VERSION ""

NS_ :

BS_:

BU_:

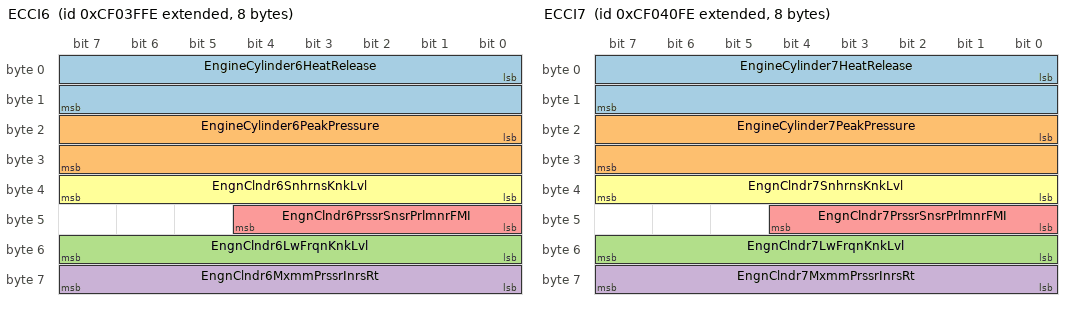
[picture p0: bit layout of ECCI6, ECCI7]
BO_ 2364555262 ECCI6: 8 Vector__XXX
 SG_ EngineCylinder6HeatRelease : 0|16@1+ (0.0001220703125,-1) [-1|6.84362793] "kJ/l" Vector__XXX
 SG_ EngineCylinder6PeakPressure : 16|16@1+ (0.0009765625,0) [0|62.74902344] "MPa" Vector__XXX
 SG_ EngnClndr6LwFrqnKnkLvl : 48|8@1+ (1,0) [0|250] "%" Vector__XXX
 SG_ EngnClndr6MxmmPrssrInrsRt : 56|8@1+ (16,0) [0|4000] "kPa/deg crank angle" Vector__XXX
 SG_ EngnClndr6PrssrSnsrPrlmnrFMI : 40|5@1+ (1,0) [0|31] "binary" Vector__XXX
 SG_ EngnClndr6SnhrnsKnkLvl : 32|8@1+ (1,0) [0|250] "%" Vector__XXX

BO_ 2364555518 ECCI7: 8 Vector__XXX
 SG_ EngineCylinder7HeatRelease : 0|16@1+ (0.0001220703125,-1) [-1|6.84362793] "kJ/l" Vector__XXX
 SG_ EngineCylinder7PeakPressure : 16|16@1+ (0.0009765625,0) [0|62.74902344] "MPa" Vector__XXX
 SG_ EngnClndr7LwFrqnKnkLvl : 48|8@1+ (1,0) [0|250] "%" Vector__XXX
 SG_ EngnClndr7MxmmPrssrInrsRt : 56|8@1+ (16,0) [0|4000] "kPa/deg crank angle" Vector__XXX
 SG_ EngnClndr7PrssrSnsrPrlmnrFMI : 40|5@1+ (1,0) [0|31] "binary" Vector__XXX
 SG_ EngnClndr7SnhrnsKnkLvl : 32|8@1+ (1,0) [0|250] "%" Vector__XXX

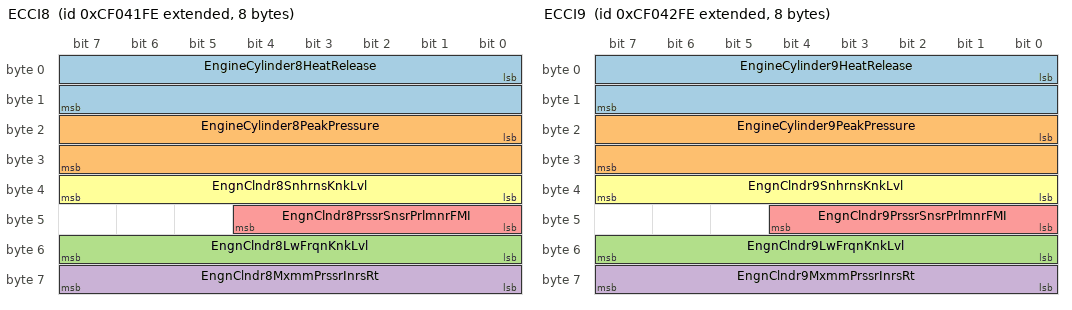
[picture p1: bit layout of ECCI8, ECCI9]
BO_ 2364555774 ECCI8: 8 Vector__XXX
 SG_ EngineCylinder8HeatRelease : 0|16@1+ (0.0001220703125,-1) [-1|6.84362793] "kJ/l" Vector__XXX
 SG_ EngineCylinder8PeakPressure : 16|16@1+ (0.0009765625,0) [0|62.74902344] "MPa" Vector__XXX
 SG_ EngnClndr8LwFrqnKnkLvl : 48|8@1+ (1,0) [0|250] "%" Vector__XXX
 SG_ EngnClndr8MxmmPrssrInrsRt : 56|8@1+ (16,0) [0|4000] "kPa/deg crank angle" Vector__XXX
 SG_ EngnClndr8PrssrSnsrPrlmnrFMI : 40|5@1+ (1,0) [0|31] "binary" Vector__XXX
 SG_ EngnClndr8SnhrnsKnkLvl : 32|8@1+ (1,0) [0|250] "%" Vector__XXX

BO_ 2364556030 ECCI9: 8 Vector__XXX
 SG_ EngineCylinder9HeatRelease : 0|16@1+ (0.0001220703125,-1) [-1|6.84362793] "kJ/l" Vector__XXX
 SG_ EngineCylinder9PeakPressure : 16|16@1+ (0.0009765625,0) [0|62.74902344] "MPa" Vector__XXX
 SG_ EngnClndr9LwFrqnKnkLvl : 48|8@1+ (1,0) [0|250] "%" Vector__XXX
 SG_ EngnClndr9MxmmPrssrInrsRt : 56|8@1+ (16,0) [0|4000] "kPa/deg crank angle" Vector__XXX
 SG_ EngnClndr9PrssrSnsrPrlmnrFMI : 40|5@1+ (1,0) [0|31] "binary" Vector__XXX
 SG_ EngnClndr9SnhrnsKnkLvl : 32|8@1+ (1,0) [0|250] "%" Vector__XXX

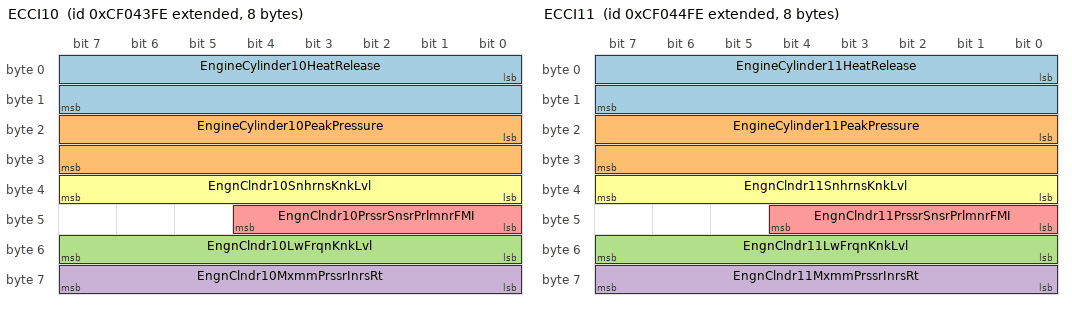
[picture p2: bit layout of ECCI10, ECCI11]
BO_ 2364556286 ECCI10: 8 Vector__XXX
 SG_ EngineCylinder10HeatRelease : 0|16@1+ (0.0001220703125,-1) [-1|6.84362793] "kJ/l" Vector__XXX
 SG_ EngineCylinder10PeakPressure : 16|16@1+ (0.0009765625,0) [0|62.74902344] "MPa" Vector__XXX
 SG_ EngnClndr10LwFrqnKnkLvl : 48|8@1+ (1,0) [0|250] "%" Vector__XXX
 SG_ EngnClndr10MxmmPrssrInrsRt : 56|8@1+ (16,0) [0|4000] "kPa/deg crank angle" Vector__XXX
 SG_ EngnClndr10PrssrSnsrPrlmnrFMI : 40|5@1+ (1,0) [0|31] "binary" Vector__XXX
 SG_ EngnClndr10SnhrnsKnkLvl : 32|8@1+ (1,0) [0|250] "%" Vector__XXX

BO_ 2364556542 ECCI11: 8 Vector__XXX
 SG_ EngineCylinder11HeatRelease : 0|16@1+ (0.0001220703125,-1) [-1|6.84362793] "kJ/l" Vector__XXX
 SG_ EngineCylinder11PeakPressure : 16|16@1+ (0.0009765625,0) [0|62.74902344] "MPa" Vector__XXX
 SG_ EngnClndr11LwFrqnKnkLvl : 48|8@1+ (1,0) [0|250] "%" Vector__XXX
 SG_ EngnClndr11MxmmPrssrInrsRt : 56|8@1+ (16,0) [0|4000] "kPa/deg crank angle" Vector__XXX
 SG_ EngnClndr11PrssrSnsrPrlmnrFMI : 40|5@1+ (1,0) [0|31] "binary" Vector__XXX
 SG_ EngnClndr11SnhrnsKnkLvl : 32|8@1+ (1,0) [0|250] "%" Vector__XXX

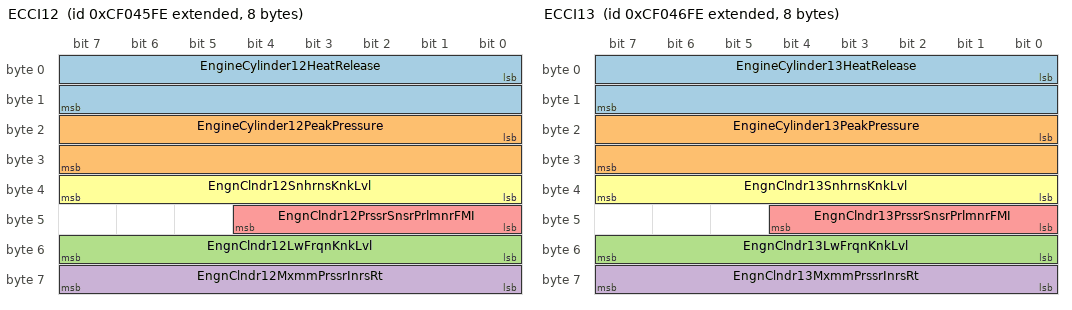
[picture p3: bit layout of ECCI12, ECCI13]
BO_ 2364556798 ECCI12: 8 Vector__XXX
 SG_ EngineCylinder12HeatRelease : 0|16@1+ (0.0001220703125,-1) [-1|6.84362793] "kJ/l" Vector__XXX
 SG_ EngineCylinder12PeakPressure : 16|16@1+ (0.0009765625,0) [0|62.74902344] "MPa" Vector__XXX
 SG_ EngnClndr12LwFrqnKnkLvl : 48|8@1+ (1,0) [0|250] "%" Vector__XXX
 SG_ EngnClndr12MxmmPrssrInrsRt : 56|8@1+ (16,0) [0|4000] "kPa/deg crank angle" Vector__XXX
 SG_ EngnClndr12PrssrSnsrPrlmnrFMI : 40|5@1+ (1,0) [0|31] "binary" Vector__XXX
 SG_ EngnClndr12SnhrnsKnkLvl : 32|8@1+ (1,0) [0|250] "%" Vector__XXX

BO_ 2364557054 ECCI13: 8 Vector__XXX
 SG_ EngineCylinder13HeatRelease : 0|16@1+ (0.0001220703125,-1) [-1|6.84362793] "kJ/l" Vector__XXX
 SG_ EngineCylinder13PeakPressure : 16|16@1+ (0.0009765625,0) [0|62.74902344] "MPa" Vector__XXX
 SG_ EngnClndr13LwFrqnKnkLvl : 48|8@1+ (1,0) [0|250] "%" Vector__XXX
 SG_ EngnClndr13MxmmPrssrInrsRt : 56|8@1+ (16,0) [0|4000] "kPa/deg crank angle" Vector__XXX
 SG_ EngnClndr13PrssrSnsrPrlmnrFMI : 40|5@1+ (1,0) [0|31] "binary" Vector__XXX
 SG_ EngnClndr13SnhrnsKnkLvl : 32|8@1+ (1,0) [0|250] "%" Vector__XXX

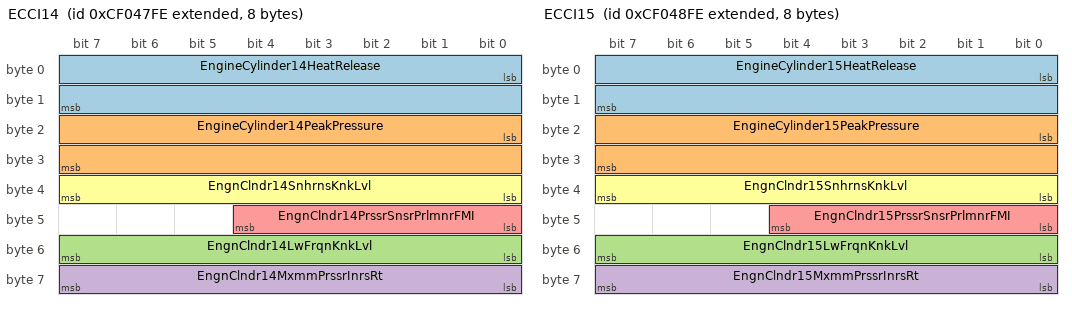
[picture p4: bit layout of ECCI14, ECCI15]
BO_ 2364557310 ECCI14: 8 Vector__XXX
 SG_ EngineCylinder14HeatRelease : 0|16@1+ (0.0001220703125,-1) [-1|6.84362793] "kJ/l" Vector__XXX
 SG_ EngineCylinder14PeakPressure : 16|16@1+ (0.0009765625,0) [0|62.74902344] "MPa" Vector__XXX
 SG_ EngnClndr14LwFrqnKnkLvl : 48|8@1+ (1,0) [0|250] "%" Vector__XXX
 SG_ EngnClndr14MxmmPrssrInrsRt : 56|8@1+ (16,0) [0|4000] "kPa/deg crank angle" Vector__XXX
 SG_ EngnClndr14PrssrSnsrPrlmnrFMI : 40|5@1+ (1,0) [0|31] "binary" Vector__XXX
 SG_ EngnClndr14SnhrnsKnkLvl : 32|8@1+ (1,0) [0|250] "%" Vector__XXX

BO_ 2364557566 ECCI15: 8 Vector__XXX
 SG_ EngineCylinder15HeatRelease : 0|16@1+ (0.0001220703125,-1) [-1|6.84362793] "kJ/l" Vector__XXX
 SG_ EngineCylinder15PeakPressure : 16|16@1+ (0.0009765625,0) [0|62.74902344] "MPa" Vector__XXX
 SG_ EngnClndr15LwFrqnKnkLvl : 48|8@1+ (1,0) [0|250] "%" Vector__XXX
 SG_ EngnClndr15MxmmPrssrInrsRt : 56|8@1+ (16,0) [0|4000] "kPa/deg crank angle" Vector__XXX
 SG_ EngnClndr15PrssrSnsrPrlmnrFMI : 40|5@1+ (1,0) [0|31] "binary" Vector__XXX
 SG_ EngnClndr15SnhrnsKnkLvl : 32|8@1+ (1,0) [0|250] "%" Vector__XXX

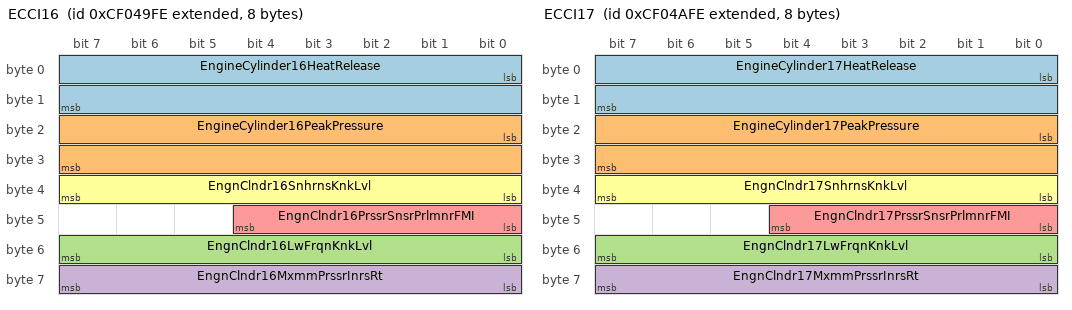
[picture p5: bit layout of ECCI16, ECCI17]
BO_ 2364557822 ECCI16: 8 Vector__XXX
 SG_ EngineCylinder16HeatRelease : 0|16@1+ (0.0001220703125,-1) [-1|6.84362793] "kJ/l" Vector__XXX
 SG_ EngineCylinder16PeakPressure : 16|16@1+ (0.0009765625,0) [0|62.74902344] "MPa" Vector__XXX
 SG_ EngnClndr16LwFrqnKnkLvl : 48|8@1+ (1,0) [0|250] "%" Vector__XXX
 SG_ EngnClndr16MxmmPrssrInrsRt : 56|8@1+ (16,0) [0|4000] "kPa/deg crank angle" Vector__XXX
 SG_ EngnClndr16PrssrSnsrPrlmnrFMI : 40|5@1+ (1,0) [0|31] "binary" Vector__XXX
 SG_ EngnClndr16SnhrnsKnkLvl : 32|8@1+ (1,0) [0|250] "%" Vector__XXX

BO_ 2364558078 ECCI17: 8 Vector__XXX
 SG_ EngineCylinder17HeatRelease : 0|16@1+ (0.0001220703125,-1) [-1|6.84362793] "kJ/l" Vector__XXX
 SG_ EngineCylinder17PeakPressure : 16|16@1+ (0.0009765625,0) [0|62.74902344] "MPa" Vector__XXX
 SG_ EngnClndr17LwFrqnKnkLvl : 48|8@1+ (1,0) [0|250] "%" Vector__XXX
 SG_ EngnClndr17MxmmPrssrInrsRt : 56|8@1+ (16,0) [0|4000] "kPa/deg crank angle" Vector__XXX
 SG_ EngnClndr17PrssrSnsrPrlmnrFMI : 40|5@1+ (1,0) [0|31] "binary" Vector__XXX
 SG_ EngnClndr17SnhrnsKnkLvl : 32|8@1+ (1,0) [0|250] "%" Vector__XXX

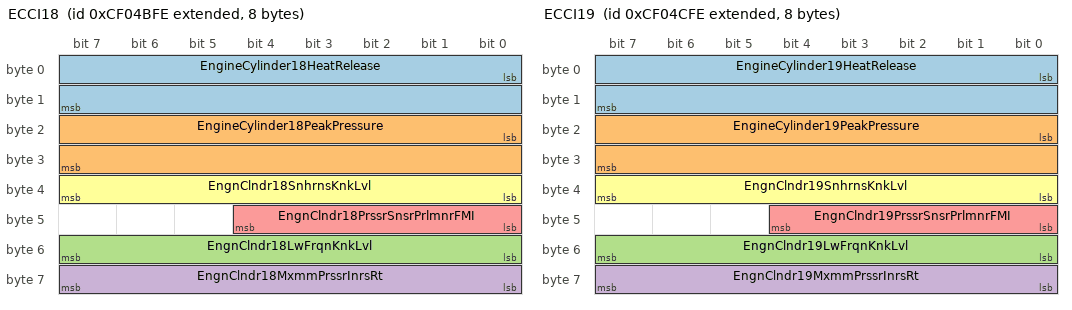
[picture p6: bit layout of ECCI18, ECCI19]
BO_ 2364558334 ECCI18: 8 Vector__XXX
 SG_ EngineCylinder18HeatRelease : 0|16@1+ (0.0001220703125,-1) [-1|6.84362793] "kJ/l" Vector__XXX
 SG_ EngineCylinder18PeakPressure : 16|16@1+ (0.0009765625,0) [0|62.74902344] "MPa" Vector__XXX
 SG_ EngnClndr18LwFrqnKnkLvl : 48|8@1+ (1,0) [0|250] "%" Vector__XXX
 SG_ EngnClndr18MxmmPrssrInrsRt : 56|8@1+ (16,0) [0|4000] "kPa/deg crank angle" Vector__XXX
 SG_ EngnClndr18PrssrSnsrPrlmnrFMI : 40|5@1+ (1,0) [0|31] "binary" Vector__XXX
 SG_ EngnClndr18SnhrnsKnkLvl : 32|8@1+ (1,0) [0|250] "%" Vector__XXX

BO_ 2364558590 ECCI19: 8 Vector__XXX
 SG_ EngineCylinder19HeatRelease : 0|16@1+ (0.0001220703125,-1) [-1|6.84362793] "kJ/l" Vector__XXX
 SG_ EngineCylinder19PeakPressure : 16|16@1+ (0.0009765625,0) [0|62.74902344] "MPa" Vector__XXX
 SG_ EngnClndr19LwFrqnKnkLvl : 48|8@1+ (1,0) [0|250] "%" Vector__XXX
 SG_ EngnClndr19MxmmPrssrInrsRt : 56|8@1+ (16,0) [0|4000] "kPa/deg crank angle" Vector__XXX
 SG_ EngnClndr19PrssrSnsrPrlmnrFMI : 40|5@1+ (1,0) [0|31] "binary" Vector__XXX
 SG_ EngnClndr19SnhrnsKnkLvl : 32|8@1+ (1,0) [0|250] "%" Vector__XXX

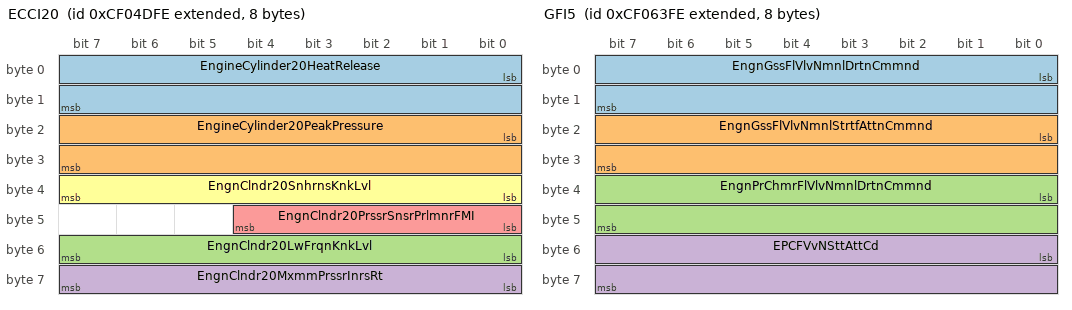
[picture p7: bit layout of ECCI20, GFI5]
BO_ 2364558846 ECCI20: 8 Vector__XXX
 SG_ EngineCylinder20HeatRelease : 0|16@1+ (0.0001220703125,-1) [-1|6.84362793] "kJ/l" Vector__XXX
 SG_ EngineCylinder20PeakPressure : 16|16@1+ (0.0009765625,0) [0|62.74902344] "MPa" Vector__XXX
 SG_ EngnClndr20LwFrqnKnkLvl : 48|8@1+ (1,0) [0|250] "%" Vector__XXX
 SG_ EngnClndr20MxmmPrssrInrsRt : 56|8@1+ (16,0) [0|4000] "kPa/deg crank angle" Vector__XXX
 SG_ EngnClndr20PrssrSnsrPrlmnrFMI : 40|5@1+ (1,0) [0|31] "binary" Vector__XXX
 SG_ EngnClndr20SnhrnsKnkLvl : 32|8@1+ (1,0) [0|250] "%" Vector__XXX

BO_ 2364564478 GFI5: 8 Vector__XXX
 SG_ EngnGssFlVlvNmnlDrtnCmmnd : 0|16@1+ (2,0) [0|128510] "micro s" Vector__XXX
 SG_ EngnGssFlVlvNmnlStrtfAttnCmmnd : 16|16@1+ (0.0078125,-400) [-400|101.99] "deg" Vector__XXX
 SG_ EngnPrChmrFlVlvNmnlDrtnCmmnd : 32|16@1+ (2,0) [0|128510] "micro s" Vector__XXX
 SG_ EPCFVvNSttAttCd : 48|16@1+ (0.0078125,-400) [-400|101.99] "deg" Vector__XXX

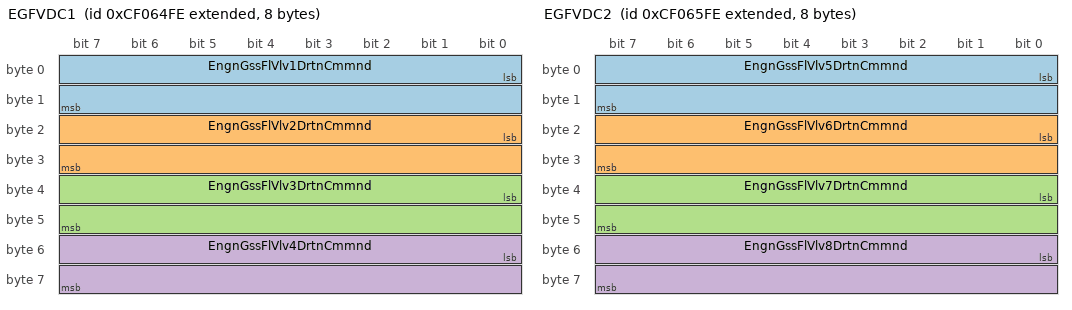
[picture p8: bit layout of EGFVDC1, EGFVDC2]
BO_ 2364564734 EGFVDC1: 8 Vector__XXX
 SG_ EngnGssFlVlv1DrtnCmmnd : 0|16@1+ (2,0) [0|128510] "micro s" Vector__XXX
 SG_ EngnGssFlVlv2DrtnCmmnd : 16|16@1+ (2,0) [0|128510] "micro s" Vector__XXX
 SG_ EngnGssFlVlv3DrtnCmmnd : 32|16@1+ (2,0) [0|128510] "micro s" Vector__XXX
 SG_ EngnGssFlVlv4DrtnCmmnd : 48|16@1+ (2,0) [0|128510] "micro s" Vector__XXX

BO_ 2364564990 EGFVDC2: 8 Vector__XXX
 SG_ EngnGssFlVlv5DrtnCmmnd : 0|16@1+ (2,0) [0|128510] "micro s" Vector__XXX
 SG_ EngnGssFlVlv6DrtnCmmnd : 16|16@1+ (2,0) [0|128510] "micro s" Vector__XXX
 SG_ EngnGssFlVlv7DrtnCmmnd : 32|16@1+ (2,0) [0|128510] "micro s" Vector__XXX
 SG_ EngnGssFlVlv8DrtnCmmnd : 48|16@1+ (2,0) [0|128510] "micro s" Vector__XXX

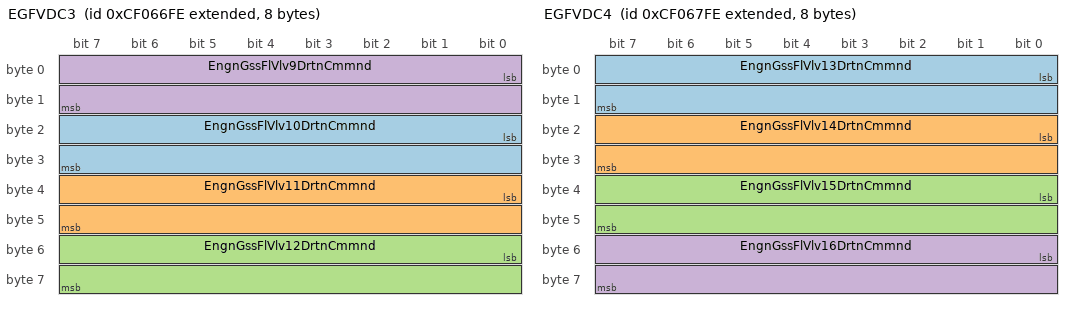
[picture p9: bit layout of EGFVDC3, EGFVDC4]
BO_ 2364565246 EGFVDC3: 8 Vector__XXX
 SG_ EngnGssFlVlv10DrtnCmmnd : 16|16@1+ (2,0) [0|128510] "micro s" Vector__XXX
 SG_ EngnGssFlVlv11DrtnCmmnd : 32|16@1+ (2,0) [0|128510] "micro s" Vector__XXX
 SG_ EngnGssFlVlv12DrtnCmmnd : 48|16@1+ (2,0) [0|128510] "micro s" Vector__XXX
 SG_ EngnGssFlVlv9DrtnCmmnd : 0|16@1+ (2,0) [0|128510] "micro s" Vector__XXX

BO_ 2364565502 EGFVDC4: 8 Vector__XXX
 SG_ EngnGssFlVlv13DrtnCmmnd : 0|16@1+ (2,0) [0|128510] "micro s" Vector__XXX
 SG_ EngnGssFlVlv14DrtnCmmnd : 16|16@1+ (2,0) [0|128510] "micro s" Vector__XXX
 SG_ EngnGssFlVlv15DrtnCmmnd : 32|16@1+ (2,0) [0|128510] "micro s" Vector__XXX
 SG_ EngnGssFlVlv16DrtnCmmnd : 48|16@1+ (2,0) [0|128510] "micro s" Vector__XXX

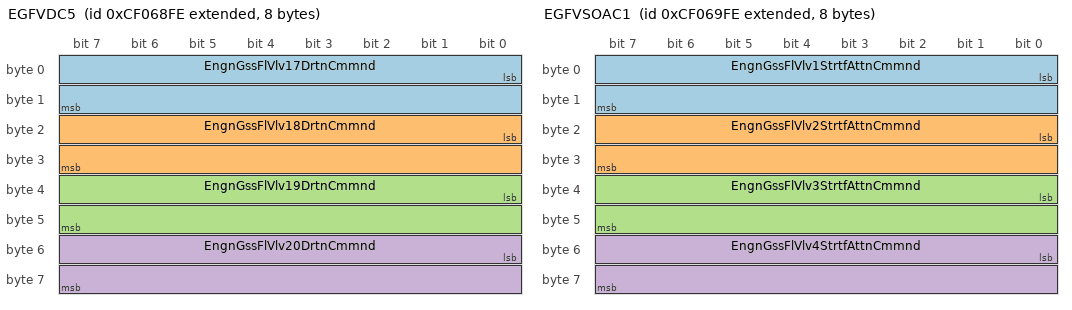
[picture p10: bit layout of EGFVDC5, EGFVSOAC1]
BO_ 2364565758 EGFVDC5: 8 Vector__XXX
 SG_ EngnGssFlVlv17DrtnCmmnd : 0|16@1+ (2,0) [0|128510] "micro s" Vector__XXX
 SG_ EngnGssFlVlv18DrtnCmmnd : 16|16@1+ (2,0) [0|128510] "micro s" Vector__XXX
 SG_ EngnGssFlVlv19DrtnCmmnd : 32|16@1+ (2,0) [0|128510] "micro s" Vector__XXX
 SG_ EngnGssFlVlv20DrtnCmmnd : 48|16@1+ (2,0) [0|128510] "micro s" Vector__XXX

BO_ 2364566014 EGFVSOAC1: 8 Vector__XXX
 SG_ EngnGssFlVlv1StrtfAttnCmmnd : 0|16@1+ (0.0078125,-400) [-400|101.99] "deg" Vector__XXX
 SG_ EngnGssFlVlv2StrtfAttnCmmnd : 16|16@1+ (0.0078125,-400) [-400|101.99] "deg" Vector__XXX
 SG_ EngnGssFlVlv3StrtfAttnCmmnd : 32|16@1+ (0.0078125,-400) [-400|101.99] "deg" Vector__XXX
 SG_ EngnGssFlVlv4StrtfAttnCmmnd : 48|16@1+ (0.0078125,-400) [-400|101.99] "deg" Vector__XXX

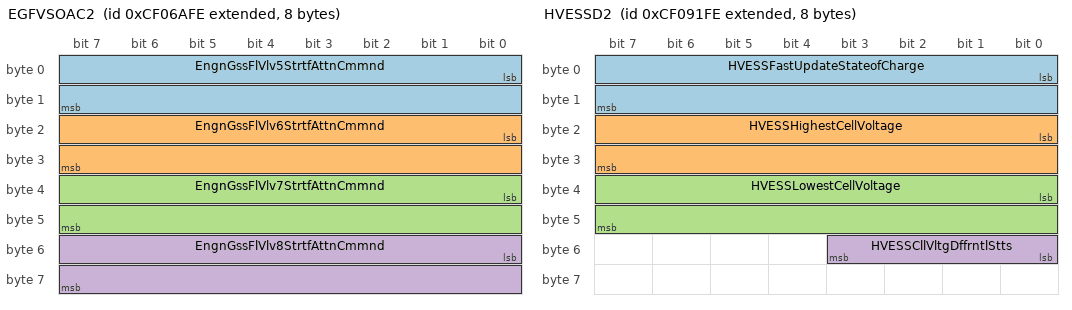
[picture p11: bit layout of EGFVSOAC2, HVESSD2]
BO_ 2364566270 EGFVSOAC2: 8 Vector__XXX
 SG_ EngnGssFlVlv5StrtfAttnCmmnd : 0|16@1+ (0.0078125,-400) [-400|101.99] "deg" Vector__XXX
 SG_ EngnGssFlVlv6StrtfAttnCmmnd : 16|16@1+ (0.0078125,-400) [-400|101.99] "deg" Vector__XXX
 SG_ EngnGssFlVlv7StrtfAttnCmmnd : 32|16@1+ (0.0078125,-400) [-400|101.99] "deg" Vector__XXX
 SG_ EngnGssFlVlv8StrtfAttnCmmnd : 48|16@1+ (0.0078125,-400) [-400|101.99] "deg" Vector__XXX

BO_ 2364566526 EGFVSOAC3: 8 Vector__XXX
 SG_ EngnGssFlVlv10StrtfAttnCmmnd : 16|16@1+ (0.0078125,-400) [-400|101.99] "deg" Vector__XXX
 SG_ EngnGssFlVlv11StrtfAttnCmmnd : 32|16@1+ (0.0078125,-400) [-400|101.99] "deg" Vector__XXX
 SG_ EngnGssFlVlv12StrtfAttnCmmnd : 48|16@1+ (0.0078125,-400) [-400|101.99] "deg" Vector__XXX
 SG_ EngnGssFlVlv9StrtfAttnCmmnd : 0|16@1+ (0.0078125,-400) [-400|101.99] "deg" Vector__XXX

BO_ 2364566782 EGFVSOAC4: 8 Vector__XXX
 SG_ EngnGssFlVlv13StrtfAttnCmmnd : 0|16@1+ (0.0078125,-400) [-400|101.99] "deg" Vector__XXX
 SG_ EngnGssFlVlv14StrtfAttnCmmnd : 16|16@1+ (0.0078125,-400) [-400|101.99] "deg" Vector__XXX
 SG_ EngnGssFlVlv15StrtfAttnCmmnd : 32|16@1+ (0.0078125,-400) [-400|101.99] "deg" Vector__XXX
 SG_ EngnGssFlVlv16StrtfAttnCmmnd : 48|16@1+ (0.0078125,-400) [-400|101.99] "deg" Vector__XXX

BO_ 2364567038 EGFVSOAC5: 8 Vector__XXX
 SG_ EngnGssFlVlv17StrtfAttnCmmnd : 0|16@1+ (0.0078125,-400) [-400|101.99] "deg" Vector__XXX
 SG_ EngnGssFlVlv18StrtfAttnCmmnd : 16|16@1+ (0.0078125,-400) [-400|101.99] "deg" Vector__XXX
 SG_ EngnGssFlVlv19StrtfAttnCmmnd : 32|16@1+ (0.0078125,-400) [-400|101.99] "deg" Vector__XXX
 SG_ EngnGssFlVlv20StrtfAttnCmmnd : 48|16@1+ (0.0078125,-400) [-400|101.99] "deg" Vector__XXX

BO_ 2364567294 FPAC: 8 Vector__XXX
 SG_ EngnFlInjtnPmp1FlCntrlVlvCmmnd : 0|16@1+ (0.0025,0) [0|160.6375] "%" Vector__XXX
 SG_ EngnFlInjtnPmp2FlCntrlVlvCmmnd : 16|16@1+ (0.0025,0) [0|160.6375] "%" Vector__XXX

BO_ 2364575998 HVESSD1: 8 Vector__XXX
 SG_ HVESSAvailableDischargePower : 0|16@1+ (0.05,0) [0|3212.75] "kW" Vector__XXX
 SG_ HVESSAvailableChargePower : 16|16@1+ (0.05,0) [0|3212.75] "kW" Vector__XXX
 SG_ HVESSVoltageLevel : 32|16@1+ (0.05,0) [0|3212.75] "V" Vector__XXX
 SG_ HVESSCurrent : 48|16@1+ (0.05,-1600) [-1600|1612.75] "A" Vector__XXX

BO_ 2364576254 HVESSD2: 8 Vector__XXX
 SG_ HVESSFastUpdateStateofCharge : 0|16@1+ (0.0015625,0) [0|100.3984375] "%" Vector__XXX
 SG_ HVESSHighestCellVoltage : 16|16@1+ (0.001,0) [0|64.255] "V" Vector__XXX
 SG_ HVESSLowestCellVoltage : 32|16@1+ (0.001,0) [0|64.255] "V" Vector__XXX
 SG_ HVESSCllVltgDffrntlStts : 48|4@1+ (1,0) [0|15] "" Vector__XXX

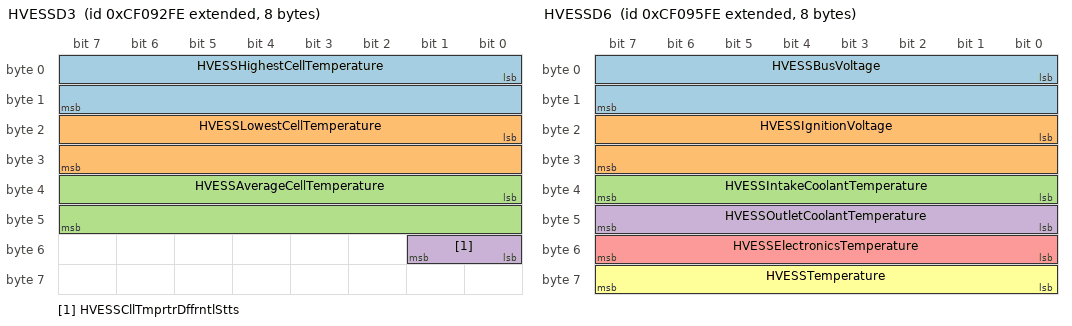
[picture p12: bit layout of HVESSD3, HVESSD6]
BO_ 2364576510 HVESSD3: 8 Vector__XXX
 SG_ HVESSHighestCellTemperature : 0|16@1+ (0.03125,-273) [-273|1734.96875] "degC" Vector__XXX
 SG_ HVESSLowestCellTemperature : 16|16@1+ (0.03125,-273) [-273|1734.96875] "degC" Vector__XXX
 SG_ HVESSAverageCellTemperature : 32|16@1+ (0.03125,-273) [-273|1734.96875] "degC" Vector__XXX
 SG_ HVESSCllTmprtrDffrntlStts : 48|2@1+ (1,0) [0|3] "" Vector__XXX

BO_ 2364576766 HVESSD4: 8 Vector__XXX
 SG_ HVESSDischargeCapacity : 0|16@1+ (0.01,0) [0|642.55] "Ah" Vector__XXX
 SG_ HVESSChargeCapacity : 16|16@1+ (0.01,0) [0|642.55] "Ah" Vector__XXX
 SG_ HVESSCellBalancingCount : 32|16@1+ (1,0) [0|64255] "count" Vector__XXX

BO_ 2364577022 HVESSD5: 8 Vector__XXX
 SG_ HVESSDischargeCurrentLimit : 0|16@1+ (0.05,-1600) [-1600|1612.75] "A" Vector__XXX
 SG_ HVESSChargeCurrentLimit : 16|16@1+ (0.05,-1600) [-1600|1612.75] "A" Vector__XXX
 SG_ HVESSMinimumCellStateofCharge : 32|16@1+ (0.0015625,0) [0|100.3984375] "%" Vector__XXX
 SG_ HVESSMaximumCellStateofCharge : 48|16@1+ (0.0015625,0) [0|100.3984375] "%" Vector__XXX

BO_ 2364577278 HVESSD6: 8 Vector__XXX
 SG_ HVESSBusVoltage : 0|16@1+ (0.05,0) [0|3212.75] "V" Vector__XXX
 SG_ HVESSIgnitionVoltage : 16|16@1+ (0.01,0) [0|642.55] "V" Vector__XXX
 SG_ HVESSIntakeCoolantTemperature : 32|8@1+ (1,-40) [-40|210] "degC" Vector__XXX
 SG_ HVESSOutletCoolantTemperature : 40|8@1+ (1,-40) [-40|210] "degC" Vector__XXX
 SG_ HVESSElectronicsTemperature : 48|8@1+ (1,-40) [-40|210] "degC" Vector__XXX
 SG_ HVESSTemperature : 56|8@1+ (1,-40) [-40|210] "degC" Vector__XXX

BO_ 2364577534 HVESSS1: 8 Vector__XXX
 SG_ HVESSHghVltgBsPstvCnttrStt : 0|2@1+ (1,0) [0|3] "" Vector__XXX
 SG_ HVESSHghVltgBsNgtvCnttrStt : 2|2@1+ (1,0) [0|3] "" Vector__XXX
 SG_ HVESSHghVltgBsDsnntFrwrnng : 4|4@1+ (1,0) [0|15] "" Vector__XXX
 SG_ HVESSHghVltgBsPrChrgRlStt : 8|2@1+ (1,0) [0|3] "" Vector__XXX
 SG_ HVESSCenterofPackContactorState : 10|2@1+ (1,0) [0|3] "" Vector__XXX
 SG_ HVESSHghVltgBsAtvIsltnTstStts : 12|4@1+ (1,0) [0|15] "" Vector__XXX
 SG_ HVESSHghVltgBsPssvIsltnTstStts : 16|4@1+ (1,0) [0|15] "" Vector__XXX
 SG_ HVESSHVILStatus : 20|2@1+ (1,0) [0|3] "" Vector__XXX
 SG_ HVESSInertiaSwitchStatus : 22|2@1+ (1,0) [0|3] "" Vector__XXX
 SG_ HVESSStateofChargeStatus : 24|4@1+ (1,0) [0|15] "" Vector__XXX
 SG_ HVESSCellBalanceStatus : 28|2@1+ (1,0) [0|3] "" Vector__XXX
 SG_ HVESSCellBalancingActive : 30|2@1+ (1,0) [0|3] "" Vector__XXX
 SG_ HVESSInternalChargerStatus : 32|2@1+ (1,0) [0|3] "" Vector__XXX
 SG_ HVESSHghVltgBsCnntnStts : 40|4@1+ (1,0) [0|15] "" Vector__XXX
 SG_ HVESSOperationalStatus : 44|4@1+ (1,0) [0|15] "" Vector__XXX
 SG_ HVESSNumberofHVESPsReady : 48|8@1+ (1,0) [0|250] "count" Vector__XXX
 SG_ HVESSStatus1Counter : 36|4@1+ (1,0) [0|15] "" Vector__XXX
 SG_ HVESSStatus1CRC : 56|8@1+ (1,0) [0|255] "count" Vector__XXX

BO_ 2364580094 HVESSD7: 8 Vector__XXX
 SG_ HVESSDischargeEnergyCapacity : 0|24@1+ (0.001,0) [0|16449.535] "kWh" Vector__XXX
 SG_ HVESSChargeEnergyCapacity : 24|24@1+ (0.001,0) [0|16449.535] "kWh" Vector__XXX
 SG_ HVESSMaximumChargeVoltageLimit : 48|16@1+ (0.05,0) [0|3212.75] "V" Vector__XXX

BO_ 2364590334 DCACAI1S2: 8 Vector__XXX
 SG_ DCACAssrInvrtr1DCSdCrrnt : 32|16@1+ (0.0625,0) [0|4015.9375] "A" Vector__XXX
 SG_ DCACAssrInvrtr1DCSdPwr : 0|16@1+ (0.0625,0) [0|4015.9375] "kW" Vector__XXX
 SG_ DCACAssrInvrtr1DCSdVltg : 16|16@1+ (0.05,0) [0|3212.75] "V" Vector__XXX
 SG_ DCACAssIvt1DCSdNtvtCsssGdVt : 48|16@1+ (0.05,0) [0|3212.75] "V" Vector__XXX

BO_ 2364590590 DCACAI1V: 8 Vector__XXX
 SG_ DCACAssrInvrtr1IgntnVltg : 0|16@1+ (0.05,0) [0|3212.75] "V" Vector__XXX
 SG_ DCACAssrInvrtr1UnswthdSLIVltg : 16|16@1+ (0.05,0) [0|3212.75] "V" Vector__XXX

BO_ 2364591102 DCACAI2S2: 8 Vector__XXX
 SG_ DCACAssrInvrtr2DCSdCrrnt : 32|16@1+ (0.0625,0) [0|4015.9375] "A" Vector__XXX
 SG_ DCACAssrInvrtr2DCSdPwr : 0|16@1+ (0.0625,0) [0|4015.9375] "kW" Vector__XXX
 SG_ DCACAssrInvrtr2DCSdVltg : 16|16@1+ (0.05,0) [0|3212.75] "V" Vector__XXX
 SG_ DCACAssIvt2DCSdNtvtCsssGdVt : 48|16@1+ (0.05,0) [0|3212.75] "V" Vector__XXX

BO_ 2364591358 DCACAI2V: 8 Vector__XXX
 SG_ DCACAssrInvrtr2IgntnVltg : 0|16@1+ (0.05,0) [0|3212.75] "V" Vector__XXX
 SG_ DCACAssrInvrtr2UnswthdSLIVltg : 16|16@1+ (0.05,0) [0|3212.75] "V" Vector__XXX

BO_ 2364592382 ECCR: 8 Vector__XXX
 SG_ EngnClndr10ExldfrmCmstnRqst : 26|2@1+ (1,0) [0|3] "" Vector__XXX
 SG_ EngnClndr11ExldfrmCmstnRqst : 28|2@1+ (1,0) [0|3] "" Vector__XXX
 SG_ EngnClndr12ExldfrmCmstnRqst : 30|2@1+ (1,0) [0|3] "" Vector__XXX
 SG_ EngnClndr13ExldfrmCmstnRqst : 32|2@1+ (1,0) [0|3] "" Vector__XXX
 SG_ EngnClndr14ExldfrmCmstnRqst : 34|2@1+ (1,0) [0|3] "" Vector__XXX
 SG_ EngnClndr15ExldfrmCmstnRqst : 36|2@1+ (1,0) [0|3] "" Vector__XXX
 SG_ EngnClndr16ExldfrmCmstnRqst : 38|2@1+ (1,0) [0|3] "" Vector__XXX
 SG_ EngnClndr17ExldfrmCmstnRqst : 40|2@1+ (1,0) [0|3] "" Vector__XXX
 SG_ EngnClndr18ExldfrmCmstnRqst : 42|2@1+ (1,0) [0|3] "" Vector__XXX
 SG_ EngnClndr19ExldfrmCmstnRqst : 44|2@1+ (1,0) [0|3] "" Vector__XXX
 SG_ EngnClndr1ExldfrmCmstnRqst : 8|2@1+ (1,0) [0|3] "" Vector__XXX
 SG_ EngnClndr20ExldfrmCmstnRqst : 46|2@1+ (1,0) [0|3] "" Vector__XXX
 SG_ EngnClndr21ExldfrmCmstnRqst : 48|2@1+ (1,0) [0|3] "" Vector__XXX
 SG_ EngnClndr22ExldfrmCmstnRqst : 50|2@1+ (1,0) [0|3] "" Vector__XXX
 SG_ EngnClndr23ExldfrmCmstnRqst : 52|2@1+ (1,0) [0|3] "" Vector__XXX
 SG_ EngnClndr24ExldfrmCmstnRqst : 54|2@1+ (1,0) [0|3] "" Vector__XXX
 SG_ EngnClndr2ExldfrmCmstnRqst : 10|2@1+ (1,0) [0|3] "" Vector__XXX
 SG_ EngnClndr3ExldfrmCmstnRqst : 12|2@1+ (1,0) [0|3] "" Vector__XXX
 SG_ EngnClndr4ExldfrmCmstnRqst : 14|2@1+ (1,0) [0|3] "" Vector__XXX
 SG_ EngnClndr5ExldfrmCmstnRqst : 16|2@1+ (1,0) [0|3] "" Vector__XXX
 SG_ EngnClndr6ExldfrmCmstnRqst : 18|2@1+ (1,0) [0|3] "" Vector__XXX
 SG_ EngnClndr7ExldfrmCmstnRqst : 20|2@1+ (1,0) [0|3] "" Vector__XXX
 SG_ EngnClndr8ExldfrmCmstnRqst : 22|2@1+ (1,0) [0|3] "" Vector__XXX
 SG_ EngnClndr9ExldfrmCmstnRqst : 24|2@1+ (1,0) [0|3] "" Vector__XXX
 SG_ NmrfEngnClndrstExldfrmCmstn : 0|8@1+ (1,0) [0|250] "count" Vector__XXX

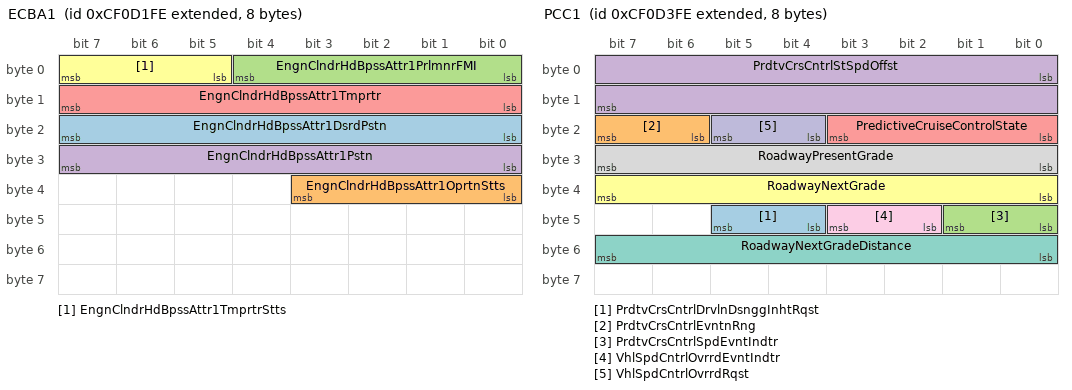
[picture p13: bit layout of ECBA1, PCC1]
BO_ 2364592638 ECBA1: 8 Vector__XXX
 SG_ EngnClndrHdBpssAttr1DsrdPstn : 16|8@1+ (0.4,0) [0|100] "%" Vector__XXX
 SG_ EngnClndrHdBpssAttr1OprtnStts : 32|4@1+ (1,0) [0|15] "" Vector__XXX
 SG_ EngnClndrHdBpssAttr1PrlmnrFMI : 0|5@1+ (1,0) [0|31] "binary" Vector__XXX
 SG_ EngnClndrHdBpssAttr1Pstn : 24|8@1+ (0.4,0) [0|100] "%" Vector__XXX
 SG_ EngnClndrHdBpssAttr1Tmprtr : 8|8@1+ (1,-40) [-40|210] "degC" Vector__XXX
 SG_ EngnClndrHdBpssAttr1TmprtrStts : 5|3@1+ (1,0) [0|7] "" Vector__XXX

BO_ 2364592894 EEC18: 8 Vector__XXX
 SG_ EngineIntakeAirSourceValve : 16|2@1+ (1,0) [0|3] "" Vector__XXX
 SG_ EngnClndrHdBpssAttr1Cmmnd : 0|16@1+ (0.0025,0) [0|160.6375] "%" Vector__XXX
 SG_ EngnExhstGsRstrtnVlvPstn : 32|16@1+ (0.0025,0) [0|160.6375] "%" Vector__XXX

BO_ 2364593150 PCC1: 8 Vector__XXX
 SG_ PrdtvCrsCntrlDrvlnDsnggInhtRqst : 44|2@1+ (1,0) [0|3] "" Vector__XXX
 SG_ PrdtvCrsCntrlEvntnRng : 22|2@1+ (1,0) [0|3] "" Vector__XXX
 SG_ PrdtvCrsCntrlSpdEvntIndtr : 40|2@1+ (1,0) [0|3] "" Vector__XXX
 SG_ PrdtvCrsCntrlStSpdOffst : 0|16@1+ (0.00390625,-125) [-125|125.996] "km/h" Vector__XXX
 SG_ PredictiveCruiseControlState : 16|4@1+ (1,0) [0|15] "" Vector__XXX
 SG_ RoadwayNextGrade : 32|8@1+ (0.125,-16) [-16|15.25] "%" Vector__XXX
 SG_ RoadwayNextGradeDistance : 48|8@1+ (25,0) [0|6250] "m" Vector__XXX
 SG_ RoadwayPresentGrade : 24|8@1+ (0.125,-16) [-16|15.25] "%" Vector__XXX
 SG_ VhlSpdCntrlOvrrdEvntIndtr : 42|2@1+ (1,0) [0|3] "" Vector__XXX
 SG_ VhlSpdCntrlOvrrdRqst : 20|2@1+ (1,0) [0|3] "" Vector__XXX

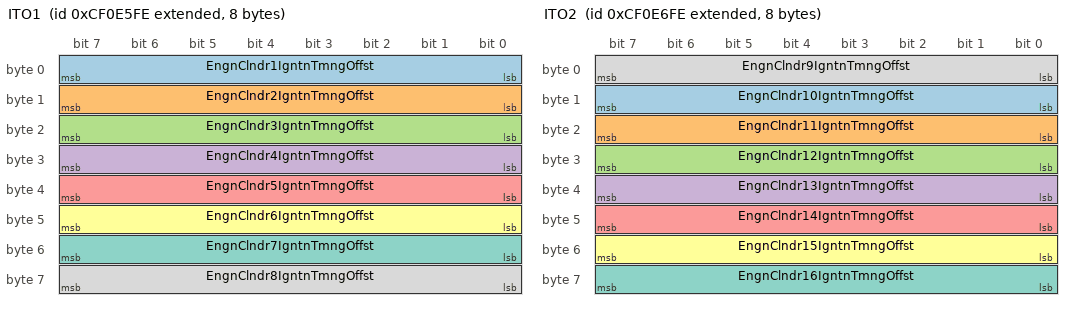
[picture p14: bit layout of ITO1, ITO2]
BO_ 2364597758 ITO1: 8 Vector__XXX
 SG_ EngnClndr1IgntnTmngOffst : 0|8@1+ (0.1,-12.5) [-12.5|12.5] "deg" Vector__XXX
 SG_ EngnClndr2IgntnTmngOffst : 8|8@1+ (0.1,-12.5) [-12.5|12.5] "deg" Vector__XXX
 SG_ EngnClndr3IgntnTmngOffst : 16|8@1+ (0.1,-12.5) [-12.5|12.5] "deg" Vector__XXX
 SG_ EngnClndr4IgntnTmngOffst : 24|8@1+ (0.1,-12.5) [-12.5|12.5] "deg" Vector__XXX
 SG_ EngnClndr5IgntnTmngOffst : 32|8@1+ (0.1,-12.5) [-12.5|12.5] "deg" Vector__XXX
 SG_ EngnClndr6IgntnTmngOffst : 40|8@1+ (0.1,-12.5) [-12.5|12.5] "deg" Vector__XXX
 SG_ EngnClndr7IgntnTmngOffst : 48|8@1+ (0.1,-12.5) [-12.5|12.5] "deg" Vector__XXX
 SG_ EngnClndr8IgntnTmngOffst : 56|8@1+ (0.1,-12.5) [-12.5|12.5] "deg" Vector__XXX

BO_ 2364598014 ITO2: 8 Vector__XXX
 SG_ EngnClndr10IgntnTmngOffst : 8|8@1+ (0.1,-12.5) [-12.5|12.5] "deg" Vector__XXX
 SG_ EngnClndr11IgntnTmngOffst : 16|8@1+ (0.1,-12.5) [-12.5|12.5] "deg" Vector__XXX
 SG_ EngnClndr12IgntnTmngOffst : 24|8@1+ (0.1,-12.5) [-12.5|12.5] "deg" Vector__XXX
 SG_ EngnClndr13IgntnTmngOffst : 32|8@1+ (0.1,-12.5) [-12.5|12.5] "deg" Vector__XXX
 SG_ EngnClndr14IgntnTmngOffst : 40|8@1+ (0.1,-12.5) [-12.5|12.5] "deg" Vector__XXX
 SG_ EngnClndr15IgntnTmngOffst : 48|8@1+ (0.1,-12.5) [-12.5|12.5] "deg" Vector__XXX
 SG_ EngnClndr16IgntnTmngOffst : 56|8@1+ (0.1,-12.5) [-12.5|12.5] "deg" Vector__XXX
 SG_ EngnClndr9IgntnTmngOffst : 0|8@1+ (0.1,-12.5) [-12.5|12.5] "deg" Vector__XXX

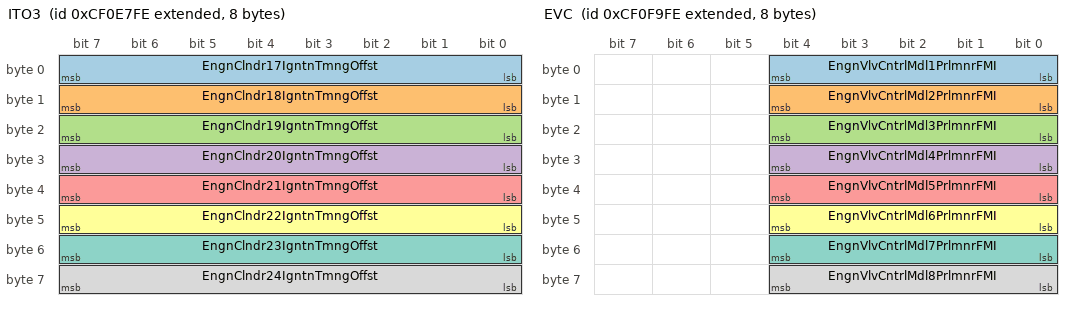
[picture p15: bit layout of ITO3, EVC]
BO_ 2364598270 ITO3: 8 Vector__XXX
 SG_ EngnClndr17IgntnTmngOffst : 0|8@1+ (0.1,-12.5) [-12.5|12.5] "deg" Vector__XXX
 SG_ EngnClndr18IgntnTmngOffst : 8|8@1+ (0.1,-12.5) [-12.5|12.5] "deg" Vector__XXX
 SG_ EngnClndr19IgntnTmngOffst : 16|8@1+ (0.1,-12.5) [-12.5|12.5] "deg" Vector__XXX
 SG_ EngnClndr20IgntnTmngOffst : 24|8@1+ (0.1,-12.5) [-12.5|12.5] "deg" Vector__XXX
 SG_ EngnClndr21IgntnTmngOffst : 32|8@1+ (0.1,-12.5) [-12.5|12.5] "deg" Vector__XXX
 SG_ EngnClndr22IgntnTmngOffst : 40|8@1+ (0.1,-12.5) [-12.5|12.5] "deg" Vector__XXX
 SG_ EngnClndr23IgntnTmngOffst : 48|8@1+ (0.1,-12.5) [-12.5|12.5] "deg" Vector__XXX
 SG_ EngnClndr24IgntnTmngOffst : 56|8@1+ (0.1,-12.5) [-12.5|12.5] "deg" Vector__XXX

BO_ 2364598526 TFAC2: 8 Vector__XXX
 SG_ EngnFlAttr3CntrlCmmnd : 32|16@1+ (0.0025,0) [0|160.6375] "%" Vector__XXX
 SG_ EngnFlAttr4CntrlCmmnd : 48|16@1+ (0.0025,0) [0|160.6375] "%" Vector__XXX

BO_ 2364602878 EVC: 8 Vector__XXX
 SG_ EngnVlvCntrlMdl1PrlmnrFMI : 0|5@1+ (1,0) [0|31] "binary" Vector__XXX
 SG_ EngnVlvCntrlMdl2PrlmnrFMI : 8|5@1+ (1,0) [0|31] "binary" Vector__XXX
 SG_ EngnVlvCntrlMdl3PrlmnrFMI : 16|5@1+ (1,0) [0|31] "binary" Vector__XXX
 SG_ EngnVlvCntrlMdl4PrlmnrFMI : 24|5@1+ (1,0) [0|31] "binary" Vector__XXX
 SG_ EngnVlvCntrlMdl5PrlmnrFMI : 32|5@1+ (1,0) [0|31] "binary" Vector__XXX
 SG_ EngnVlvCntrlMdl6PrlmnrFMI : 40|5@1+ (1,0) [0|31] "binary" Vector__XXX
 SG_ EngnVlvCntrlMdl7PrlmnrFMI : 48|5@1+ (1,0) [0|31] "binary" Vector__XXX
 SG_ EngnVlvCntrlMdl8PrlmnrFMI : 56|5@1+ (1,0) [0|31] "binary" Vector__XXX

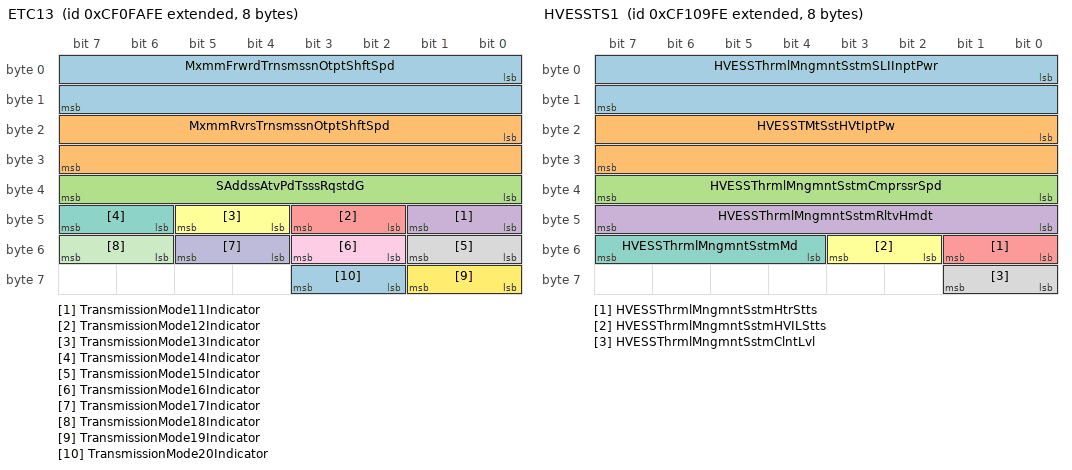
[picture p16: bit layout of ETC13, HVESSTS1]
BO_ 2364603134 ETC13: 8 Vector__XXX
 SG_ MxmmFrwrdTrnsmssnOtptShftSpd : 0|16@1+ (0.125,0) [0|8031.875] "rpm" Vector__XXX
 SG_ MxmmRvrsTrnsmssnOtptShftSpd : 16|16@1+ (0.125,0) [0|8031.875] "rpm" Vector__XXX
 SG_ SAddssAtvPdTsssRqstdG : 32|8@1+ (1,0) [0|255] "SA" Vector__XXX
 SG_ TransmissionMode11Indicator : 40|2@1+ (1,0) [0|3] "" Vector__XXX
 SG_ TransmissionMode12Indicator : 42|2@1+ (1,0) [0|3] "" Vector__XXX
 SG_ TransmissionMode13Indicator : 44|2@1+ (1,0) [0|3] "" Vector__XXX
 SG_ TransmissionMode14Indicator : 46|2@1+ (1,0) [0|3] "" Vector__XXX
 SG_ TransmissionMode15Indicator : 48|2@1+ (1,0) [0|3] "" Vector__XXX
 SG_ TransmissionMode16Indicator : 50|2@1+ (1,0) [0|3] "" Vector__XXX
 SG_ TransmissionMode17Indicator : 52|2@1+ (1,0) [0|3] "" Vector__XXX
 SG_ TransmissionMode18Indicator : 54|2@1+ (1,0) [0|3] "" Vector__XXX
 SG_ TransmissionMode19Indicator : 56|2@1+ (1,0) [0|3] "" Vector__XXX
 SG_ TransmissionMode20Indicator : 58|2@1+ (1,0) [0|3] "" Vector__XXX

BO_ 2364603390 A1SCRDSR3: 8 Vector__XXX
 SG_ Atttt1DsExstFdDsVv1Cd : 16|16@1+ (0.0025,0) [0|160.6375] "%" Vector__XXX
 SG_ Atttt1DsExstFdRqstdQttIttHRst : 0|16@1+ (0.001,0) [0|64.255] "g" Vector__XXX

BO_ 2364603646 A2SCRDSR3: 8 Vector__XXX
 SG_ Atttt2DsExstFdRqstdQttIttHRst : 0|16@1+ (0.001,0) [0|64.255] "g" Vector__XXX

BO_ 2364603902 A1SCRDSI4: 8 Vector__XXX
 SG_ Atttt1DsExstFdAtQttIttHRst : 0|16@1+ (0.001,0) [0|64.255] "g" Vector__XXX

BO_ 2364604158 A2SCRDSI4: 8 Vector__XXX
 SG_ Atttt2DsExstFdAtQttIttHRst : 0|16@1+ (0.001,0) [0|64.255] "g" Vector__XXX

BO_ 2364605438 GTRACE: 8 Vector__XXX
 SG_ GeneratorTripkVArHoursExport : 32|32@1+ (1,0) [0|4211081215] "kVArh" Vector__XXX
 SG_ GeneratorTripkWHoursExport : 0|32@1+ (1,0) [0|4211081215] "kWh" Vector__XXX

BO_ 2364605950 HPD: 8 Vector__XXX
 SG_ HydraulicLinePressure : 0|16@1+ (1,0) [0|64255] "kPa" Vector__XXX
 SG_ MechanicalMovementAngle : 16|16@1+ (0.0078125,0) [0|501.99] "deg" Vector__XXX

BO_ 2364606718 HVESSMS1: 8 Vector__XXX
 SG_ HVESSModule1OperationalStatus : 0|2@1+ (1,0) [0|3] "" Vector__XXX
 SG_ HVESSModule2OperationalStatus : 2|2@1+ (1,0) [0|3] "" Vector__XXX
 SG_ HVESSModule3OperationalStatus : 4|2@1+ (1,0) [0|3] "" Vector__XXX
 SG_ HVESSModule4OperationalStatus : 6|2@1+ (1,0) [0|3] "" Vector__XXX
 SG_ HVESSModule5OperationalStatus : 8|2@1+ (1,0) [0|3] "" Vector__XXX
 SG_ HVESSModule6OperationalStatus : 10|2@1+ (1,0) [0|3] "" Vector__XXX
 SG_ HVESSModule7OperationalStatus : 12|2@1+ (1,0) [0|3] "" Vector__XXX
 SG_ HVESSModule8OperationalStatus : 14|2@1+ (1,0) [0|3] "" Vector__XXX
 SG_ HVESSModule9OperationalStatus : 16|2@1+ (1,0) [0|3] "" Vector__XXX
 SG_ HVESSModule10OperationalStatus : 18|2@1+ (1,0) [0|3] "" Vector__XXX
 SG_ HVESSModule11OperationalStatus : 20|2@1+ (1,0) [0|3] "" Vector__XXX
 SG_ HVESSModule12OperationalStatus : 22|2@1+ (1,0) [0|3] "" Vector__XXX
 SG_ HVESSModule13OperationalStatus : 24|2@1+ (1,0) [0|3] "" Vector__XXX
 SG_ HVESSModule14OperationalStatus : 26|2@1+ (1,0) [0|3] "" Vector__XXX
 SG_ HVESSModule15OperationalStatus : 28|2@1+ (1,0) [0|3] "" Vector__XXX
 SG_ HVESSModule16OperationalStatus : 30|2@1+ (1,0) [0|3] "" Vector__XXX
 SG_ HVESSModule17OperationalStatus : 32|2@1+ (1,0) [0|3] "" Vector__XXX
 SG_ HVESSModule18OperationalStatus : 34|2@1+ (1,0) [0|3] "" Vector__XXX
 SG_ HVESSModule19OperationalStatus : 36|2@1+ (1,0) [0|3] "" Vector__XXX
 SG_ HVESSModule20OperationalStatus : 38|2@1+ (1,0) [0|3] "" Vector__XXX
 SG_ HVESSModule21OperationalStatus : 40|2@1+ (1,0) [0|3] "" Vector__XXX
 SG_ HVESSModule22OperationalStatus : 42|2@1+ (1,0) [0|3] "" Vector__XXX
 SG_ HVESSModule23OperationalStatus : 44|2@1+ (1,0) [0|3] "" Vector__XXX
 SG_ HVESSModule24OperationalStatus : 46|2@1+ (1,0) [0|3] "" Vector__XXX
 SG_ HVESSModule25OperationalStatus : 48|2@1+ (1,0) [0|3] "" Vector__XXX
 SG_ HVESSModule26OperationalStatus : 50|2@1+ (1,0) [0|3] "" Vector__XXX
 SG_ HVESSModule27OperationalStatus : 52|2@1+ (1,0) [0|3] "" Vector__XXX
 SG_ HVESSModule28OperationalStatus : 54|2@1+ (1,0) [0|3] "" Vector__XXX
 SG_ HVESSModule29OperationalStatus : 56|2@1+ (1,0) [0|3] "" Vector__XXX
 SG_ HVESSModule30OperationalStatus : 58|2@1+ (1,0) [0|3] "" Vector__XXX
 SG_ HVESSModule31OperationalStatus : 60|2@1+ (1,0) [0|3] "" Vector__XXX
 SG_ HVESSModule32OperationalStatus : 62|2@1+ (1,0) [0|3] "" Vector__XXX

BO_ 2364606974 HVESSTS1: 8 Vector__XXX
 SG_ HVESSThrmlMngmntSstmSLIInptPwr : 0|16@1+ (0.5,0) [0|32127.5] "W" Vector__XXX
 SG_ HVESSTMtSstHVtIptPw : 16|16@1+ (0.5,0) [0|32127.5] "W" Vector__XXX
 SG_ HVESSThrmlMngmntSstmCmprssrSpd : 32|8@1+ (32,0) [0|8000] "rpm" Vector__XXX
 SG_ HVESSThrmlMngmntSstmRltvHmdt : 40|8@1+ (0.4,0) [0|100] "%" Vector__XXX
 SG_ HVESSThrmlMngmntSstmHtrStts : 48|2@1+ (1,0) [0|3] "" Vector__XXX
 SG_ HVESSThrmlMngmntSstmHVILStts : 50|2@1+ (1,0) [0|3] "" Vector__XXX
 SG_ HVESSThrmlMngmntSstmMd : 52|4@1+ (1,0) [0|15] "" Vector__XXX
 SG_ HVESSThrmlMngmntSstmClntLvl : 56|2@1+ (1,0) [0|3] "" Vector__XXX

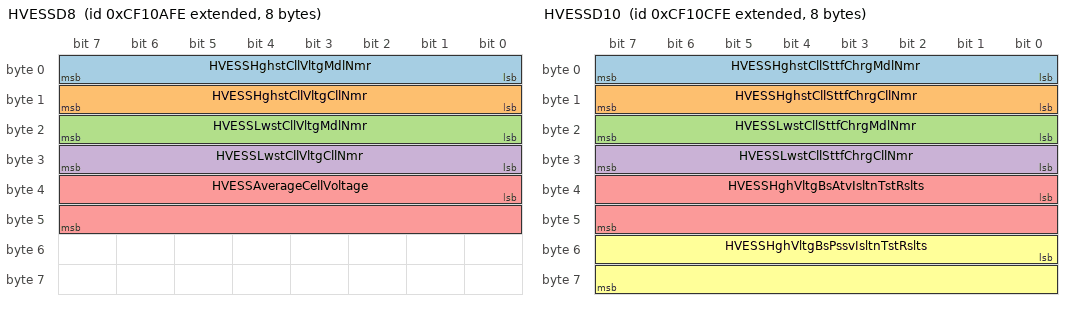
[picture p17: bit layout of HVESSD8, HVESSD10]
BO_ 2364607230 HVESSD8: 8 Vector__XXX
 SG_ HVESSHghstCllVltgMdlNmr : 0|8@1+ (1,0) [0|250] "count" Vector__XXX
 SG_ HVESSHghstCllVltgCllNmr : 8|8@1+ (1,0) [0|250] "count" Vector__XXX
 SG_ HVESSLwstCllVltgMdlNmr : 16|8@1+ (1,0) [0|250] "count" Vector__XXX
 SG_ HVESSLwstCllVltgCllNmr : 24|8@1+ (1,0) [0|250] "count" Vector__XXX
 SG_ HVESSAverageCellVoltage : 32|16@1+ (0.001,0) [0|64.255] "V" Vector__XXX

BO_ 2364607486 HVESSD9: 8 Vector__XXX
 SG_ HVESSHghstCllTmprtrMdlNmr : 0|8@1+ (1,0) [0|250] "count" Vector__XXX
 SG_ HVESSHghstCllTmprtrCllNmr : 8|8@1+ (1,0) [0|250] "count" Vector__XXX
 SG_ HVESSLwstCllTmprtrMdlNmr : 16|8@1+ (1,0) [0|250] "count" Vector__XXX
 SG_ HVESSLwstCllTmprtrCllNmr : 24|8@1+ (1,0) [0|250] "count" Vector__XXX

BO_ 2364607742 HVESSD10: 8 Vector__XXX
 SG_ HVESSHghstCllSttfChrgMdlNmr : 0|8@1+ (1,0) [0|250] "count" Vector__XXX
 SG_ HVESSHghstCllSttfChrgCllNmr : 8|8@1+ (1,0) [0|250] "count" Vector__XXX
 SG_ HVESSLwstCllSttfChrgMdlNmr : 16|8@1+ (1,0) [0|250] "count" Vector__XXX
 SG_ HVESSLwstCllSttfChrgCllNmr : 24|8@1+ (1,0) [0|250] "count" Vector__XXX
 SG_ HVESSHghVltgBsAtvIsltnTstRslts : 32|16@1+ (0.1,0) [0|6425.5] "ohm/V" Vector__XXX
 SG_ HVESSHghVltgBsPssvIsltnTstRslts : 48|16@1+ (0.1,0) [0|6425.5] "ohm/V" Vector__XXX

BO_ 2364608510 EOI2: 8 Vector__XXX
 SG_ EnginePowerDerateRequest : 16|16@1+ (0.5,0) [0|32127.5] "kW" Vector__XXX
 SG_ EngineSelfInducedDerateLoad : 0|16@1+ (0.5,0) [0|32127.5] "kW" Vector__XXX

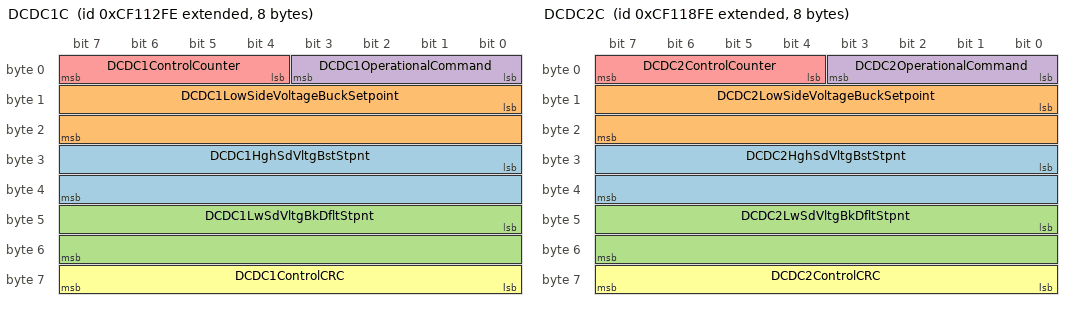
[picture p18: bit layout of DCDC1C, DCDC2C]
BO_ 2364609278 DCDC1C: 8 Vector__XXX
 SG_ DCDC1HghSdVltgBstStpnt : 24|16@1+ (0.05,0) [0|3212.75] "V" Vector__XXX
 SG_ DCDC1LowSideVoltageBuckSetpoint : 8|16@1+ (0.01,0) [0|642.55] "V" Vector__XXX
 SG_ DCDC1LwSdVltgBkDfltStpnt : 40|16@1+ (0.01,0) [0|642.55] "V" Vector__XXX
 SG_ DCDC1OperationalCommand : 0|4@1+ (1,0) [0|15] "" Vector__XXX
 SG_ DCDC1ControlCounter : 4|4@1+ (1,0) [0|15] "" Vector__XXX
 SG_ DCDC1ControlCRC : 56|8@1+ (1,0) [0|255] "count" Vector__XXX

BO_ 2364609534 DCDC1OS: 8 Vector__XXX
 SG_ DCDC1HVILStatus : 4|2@1+ (1,0) [0|3] "" Vector__XXX
 SG_ DCDC1LoadshedRequest : 6|2@1+ (1,0) [0|3] "" Vector__XXX
 SG_ DCDC1OperationalStatus : 0|4@1+ (1,0) [0|15] "" Vector__XXX
 SG_ DCDC1PwrLmtdtCnvrtrTmprtr : 20|2@1+ (1,0) [0|3] "" Vector__XXX
 SG_ DCDC1PwrLmtdtEltrnFltrTmprtr : 22|2@1+ (1,0) [0|3] "" Vector__XXX
 SG_ DCDC1PwrLmtdtHghSdCrrnt : 8|2@1+ (1,0) [0|3] "" Vector__XXX
 SG_ DCDC1PwrLmtdtHghSdVltgMnmm : 12|2@1+ (1,0) [0|3] "" Vector__XXX
 SG_ DCDC1PwrLmtdtHghSdVltgMxmm : 14|2@1+ (1,0) [0|3] "" Vector__XXX
 SG_ DCDC1PwrLmtdtLwSdCrrnt : 10|2@1+ (1,0) [0|3] "" Vector__XXX
 SG_ DCDC1PwrLmtdtLwSdVltgMnmm : 16|2@1+ (1,0) [0|3] "" Vector__XXX
 SG_ DCDC1PwrLmtdtLwSdVltgMxmm : 18|2@1+ (1,0) [0|3] "" Vector__XXX
 SG_ DCDC1PwrLmtdtPwrEltrnsTmprtr : 24|2@1+ (1,0) [0|3] "" Vector__XXX
 SG_ DCDC1PwrLmtdtSLIBttrTrmnlCrrnt : 28|2@1+ (1,0) [0|3] "" Vector__XXX
 SG_ DCDC1PwrLmtdtSLIBttrTrmnlTmprtr : 30|2@1+ (1,0) [0|3] "" Vector__XXX
 SG_ DCDC1PwrLmtdtSLIBttrTrmnlVltg : 26|2@1+ (1,0) [0|3] "" Vector__XXX
 SG_ DCDC1PwrLmtdtUndfndRsn : 32|2@1+ (1,0) [0|3] "" Vector__XXX
 SG_ DCDC1OperatingStatusCounter : 52|4@1+ (1,0) [0|15] "" Vector__XXX
 SG_ DCDC1OperatingStatusCRC : 56|8@1+ (1,0) [0|255] "count" Vector__XXX

BO_ 2364609790 DCDC1VC: 8 Vector__XXX
 SG_ DCDC1HighSideCurrent : 48|16@1+ (0.1,-3212.7) [-3212.7|3212.8] "A" Vector__XXX
 SG_ DCDC1HighSideVoltage : 32|16@1+ (0.05,0) [0|3212.75] "V" Vector__XXX
 SG_ DCDC1LowSideCurrent : 16|16@1+ (0.1,-3212.7) [-3212.7|3212.8] "A" Vector__XXX
 SG_ DCDC1LowSideVoltage : 0|16@1+ (0.01,0) [0|642.55] "V" Vector__XXX

BO_ 2364610046 DCDC1SBS: 8 Vector__XXX
 SG_ DCDC1SLIBatteryTerminalCurrent : 16|16@1+ (0.1,-3212.7) [-3212.7|3212.8] "A" Vector__XXX
 SG_ DCDC1SLIBatteryTerminalVoltage : 0|16@1+ (0.01,0) [0|642.55] "V" Vector__XXX
 SG_ DCDC1SLIBttrTrmnlTmprtr : 32|8@1+ (1,-40) [-40|210] "degC" Vector__XXX

BO_ 2364610558 DCDC1S2: 8 Vector__XXX
 SG_ DCDC1HighSidePower : 16|16@1+ (0.05,-1600) [-1600|1612.75] "kW" Vector__XXX
 SG_ DCDC1LowSidePower : 0|16@1+ (0.05,-1600) [-1600|1612.75] "kW" Vector__XXX
 SG_ DCDC1HghSdNgtvtChsssGrndVltg : 32|16@1+ (0.05,0) [0|3212.75] "V" Vector__XXX

BO_ 2364610814 DCDC2C: 8 Vector__XXX
 SG_ DCDC2HghSdVltgBstStpnt : 24|16@1+ (0.05,0) [0|3212.75] "V" Vector__XXX
 SG_ DCDC2LowSideVoltageBuckSetpoint : 8|16@1+ (0.01,0) [0|642.55] "V" Vector__XXX
 SG_ DCDC2LwSdVltgBkDfltStpnt : 40|16@1+ (0.01,0) [0|642.55] "V" Vector__XXX
 SG_ DCDC2OperationalCommand : 0|4@1+ (1,0) [0|15] "" Vector__XXX
 SG_ DCDC2ControlCounter : 4|4@1+ (1,0) [0|15] "" Vector__XXX
 SG_ DCDC2ControlCRC : 56|8@1+ (1,0) [0|255] "count" Vector__XXX

BO_ 2364611070 DCDC2OS: 8 Vector__XXX
 SG_ DCDC2HVILStatus : 4|2@1+ (1,0) [0|3] "" Vector__XXX
 SG_ DCDC2LoadshedRequest : 6|2@1+ (1,0) [0|3] "" Vector__XXX
 SG_ DCDC2OperationalStatus : 0|4@1+ (1,0) [0|15] "" Vector__XXX
 SG_ DCDC2PwrLmtdtCnvrtrTmprtr : 20|2@1+ (1,0) [0|3] "" Vector__XXX
 SG_ DCDC2PwrLmtdtEltrnFltrTmprtr : 22|2@1+ (1,0) [0|3] "" Vector__XXX
 SG_ DCDC2PwrLmtdtHghSdCrrnt : 8|2@1+ (1,0) [0|3] "" Vector__XXX
 SG_ DCDC2PwrLmtdtHghSdVltgMnmm : 12|2@1+ (1,0) [0|3] "" Vector__XXX
 SG_ DCDC2PwrLmtdtHghSdVltgMxmm : 14|2@1+ (1,0) [0|3] "" Vector__XXX
 SG_ DCDC2PwrLmtdtLwSdCrrnt : 10|2@1+ (1,0) [0|3] "" Vector__XXX
 SG_ DCDC2PwrLmtdtLwSdVltgMnmm : 16|2@1+ (1,0) [0|3] "" Vector__XXX
 SG_ DCDC2PwrLmtdtLwSdVltgMxmm : 18|2@1+ (1,0) [0|3] "" Vector__XXX
 SG_ DCDC2PwrLmtdtPwrEltrnsTmprtr : 24|2@1+ (1,0) [0|3] "" Vector__XXX
 SG_ DCDC2PwrLmtdtSLIBttrTrmnlCrrnt : 28|2@1+ (1,0) [0|3] "" Vector__XXX
 SG_ DCDC2PwrLmtdtSLIBttrTrmnlTmprtr : 30|2@1+ (1,0) [0|3] "" Vector__XXX
 SG_ DCDC2PwrLmtdtSLIBttrTrmnlVltg : 26|2@1+ (1,0) [0|3] "" Vector__XXX
 SG_ DCDC2PwrLmtdtUndfndRsn : 32|2@1+ (1,0) [0|3] "" Vector__XXX
 SG_ DCDC2OperatingStatusCounter : 52|4@1+ (1,0) [0|15] "" Vector__XXX
 SG_ DCDC2OperatingStatusCRC : 56|8@1+ (1,0) [0|255] "count" Vector__XXX

BO_ 2364611326 DCDC2VC: 8 Vector__XXX
 SG_ DCDC2HighSideCurrent : 48|16@1+ (0.1,-3212.7) [-3212.7|3212.8] "A" Vector__XXX
 SG_ DCDC2HighSideVoltage : 32|16@1+ (0.05,0) [0|3212.75] "V" Vector__XXX
 SG_ DCDC2LowSideCurrent : 16|16@1+ (0.1,-3212.7) [-3212.7|3212.8] "A" Vector__XXX
 SG_ DCDC2LowSideVoltage : 0|16@1+ (0.01,0) [0|642.55] "V" Vector__XXX

BO_ 2364611582 DCDC2SBS: 8 Vector__XXX
 SG_ DCDC2SLIBatteryTerminalCurrent : 16|16@1+ (0.1,-3212.7) [-3212.7|3212.8] "A" Vector__XXX
 SG_ DCDC2SLIBatteryTerminalVoltage : 0|16@1+ (0.01,0) [0|642.55] "V" Vector__XXX
 SG_ DCDC2SLIBttrTrmnlTmprtr : 32|8@1+ (1,-40) [-40|210] "degC" Vector__XXX

BO_ 2364611838 DCDC2S2: 8 Vector__XXX
 SG_ DCDC2HighSidePower : 16|16@1+ (0.05,-1600) [-1600|1612.75] "kW" Vector__XXX
 SG_ DCDC2LowSidePower : 0|16@1+ (0.05,-1600) [-1600|1612.75] "kW" Vector__XXX
 SG_ DCDC2HghSdNgtvtChsssGrndVltg : 32|16@1+ (0.05,0) [0|3212.75] "V" Vector__XXX

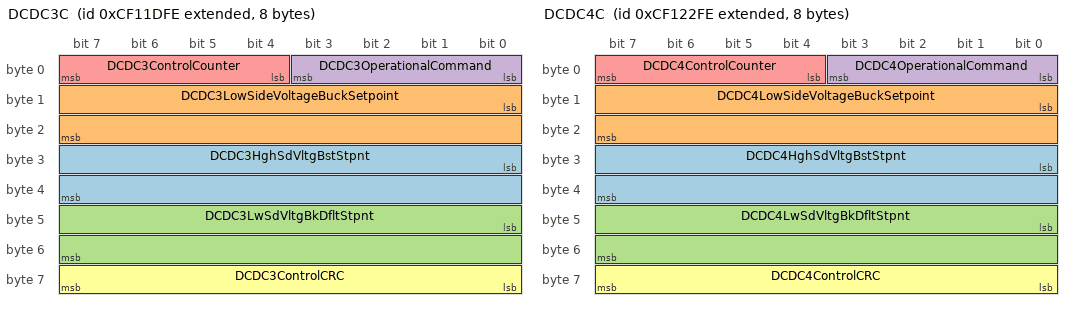
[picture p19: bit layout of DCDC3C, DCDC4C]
BO_ 2364612094 DCDC3C: 8 Vector__XXX
 SG_ DCDC3HghSdVltgBstStpnt : 24|16@1+ (0.05,0) [0|3212.75] "V" Vector__XXX
 SG_ DCDC3LowSideVoltageBuckSetpoint : 8|16@1+ (0.01,0) [0|642.55] "V" Vector__XXX
 SG_ DCDC3LwSdVltgBkDfltStpnt : 40|16@1+ (0.01,0) [0|642.55] "V" Vector__XXX
 SG_ DCDC3OperationalCommand : 0|4@1+ (1,0) [0|15] "" Vector__XXX
 SG_ DCDC3ControlCounter : 4|4@1+ (1,0) [0|15] "" Vector__XXX
 SG_ DCDC3ControlCRC : 56|8@1+ (1,0) [0|255] "count" Vector__XXX

BO_ 2364612350 DCDC3OS: 8 Vector__XXX
 SG_ DCDC3HVILStatus : 4|2@1+ (1,0) [0|3] "" Vector__XXX
 SG_ DCDC3LoadshedRequest : 6|2@1+ (1,0) [0|3] "" Vector__XXX
 SG_ DCDC3OperationalStatus : 0|4@1+ (1,0) [0|15] "" Vector__XXX
 SG_ DCDC3PwrLmtdtCnvrtrTmprtr : 20|2@1+ (1,0) [0|3] "" Vector__XXX
 SG_ DCDC3PwrLmtdtEltrnFltrTmprtr : 22|2@1+ (1,0) [0|3] "" Vector__XXX
 SG_ DCDC3PwrLmtdtHghSdCrrnt : 8|2@1+ (1,0) [0|3] "" Vector__XXX
 SG_ DCDC3PwrLmtdtHghSdVltgMnmm : 12|2@1+ (1,0) [0|3] "" Vector__XXX
 SG_ DCDC3PwrLmtdtHghSdVltgMxmm : 14|2@1+ (1,0) [0|3] "" Vector__XXX
 SG_ DCDC3PwrLmtdtLwSdCrrnt : 10|2@1+ (1,0) [0|3] "" Vector__XXX
 SG_ DCDC3PwrLmtdtLwSdVltgMnmm : 16|2@1+ (1,0) [0|3] "" Vector__XXX
 SG_ DCDC3PwrLmtdtLwSdVltgMxmm : 18|2@1+ (1,0) [0|3] "" Vector__XXX
 SG_ DCDC3PwrLmtdtPwrEltrnsTmprtr : 24|2@1+ (1,0) [0|3] "" Vector__XXX
 SG_ DCDC3PwrLmtdtSLIBttrTrmnlCrrnt : 28|2@1+ (1,0) [0|3] "" Vector__XXX
 SG_ DCDC3PwrLmtdtSLIBttrTrmnlTmprtr : 30|2@1+ (1,0) [0|3] "" Vector__XXX
 SG_ DCDC3PwrLmtdtSLIBttrTrmnlVltg : 26|2@1+ (1,0) [0|3] "" Vector__XXX
 SG_ DCDC3PwrLmtdtUndfndRsn : 32|2@1+ (1,0) [0|3] "" Vector__XXX
 SG_ DCDC3OperatingStatusCounter : 52|4@1+ (1,0) [0|15] "" Vector__XXX
 SG_ DCDC3OperatingStatusCRC : 56|8@1+ (1,0) [0|255] "count" Vector__XXX

BO_ 2364612606 DCDC3VC: 8 Vector__XXX
 SG_ DCDC3HighSideCurrent : 48|16@1+ (0.1,-3212.7) [-3212.7|3212.8] "A" Vector__XXX
 SG_ DCDC3HighSideVoltage : 32|16@1+ (0.05,0) [0|3212.75] "V" Vector__XXX
 SG_ DCDC3LowSideCurrent : 16|16@1+ (0.1,-3212.7) [-3212.7|3212.8] "A" Vector__XXX
 SG_ DCDC3LowSideVoltage : 0|16@1+ (0.01,0) [0|642.55] "V" Vector__XXX

BO_ 2364612862 DCDC3SBS: 8 Vector__XXX
 SG_ DCDC3SLIBatteryTerminalCurrent : 16|16@1+ (0.1,-3212.7) [-3212.7|3212.8] "A" Vector__XXX
 SG_ DCDC3SLIBatteryTerminalVoltage : 0|16@1+ (0.01,0) [0|642.55] "V" Vector__XXX
 SG_ DCDC3SLIBttrTrmnlTmprtr : 32|8@1+ (1,-40) [-40|210] "degC" Vector__XXX

BO_ 2364613118 DCDC3S2: 8 Vector__XXX
 SG_ DCDC3HighSidePower : 16|16@1+ (0.05,-1600) [-1600|1612.75] "kW" Vector__XXX
 SG_ DCDC3LowSidePower : 0|16@1+ (0.05,-1600) [-1600|1612.75] "kW" Vector__XXX
 SG_ DCDC3HghSdNgtvtChsssGrndVltg : 32|16@1+ (0.05,0) [0|3212.75] "V" Vector__XXX

BO_ 2364613374 DCDC4C: 8 Vector__XXX
 SG_ DCDC4HghSdVltgBstStpnt : 24|16@1+ (0.05,0) [0|3212.75] "V" Vector__XXX
 SG_ DCDC4LowSideVoltageBuckSetpoint : 8|16@1+ (0.01,0) [0|642.55] "V" Vector__XXX
 SG_ DCDC4LwSdVltgBkDfltStpnt : 40|16@1+ (0.01,0) [0|642.55] "V" Vector__XXX
 SG_ DCDC4OperationalCommand : 0|4@1+ (1,0) [0|15] "" Vector__XXX
 SG_ DCDC4ControlCounter : 4|4@1+ (1,0) [0|15] "" Vector__XXX
 SG_ DCDC4ControlCRC : 56|8@1+ (1,0) [0|255] "count" Vector__XXX

CM_ BO_ 2364555262 "Engine Cylinder 6 Combustion Information";
CM_ SG_ 2364555262 EngineCylinder6HeatRelease "Engine Cylinder 6 Heat Release: The amount of heat produced during combustion in engine cylinder 6.  The negative range is to cover thermodynamic behavior during misfire.";
CM_ SG_ 2364555262 EngineCylinder6PeakPressure "Engine Cylinder 6 Peak Pressure: Peak pressure in engine cylinder 6 in combustion cycle.";
CM_ SG_ 2364555262 EngnClndr6LwFrqnKnkLvl "Engine Cylinder 6 Low Frequency Knock Level: Indicates the level of low frequency knock for engine cylinder 6. This knock occurs at frequencies below the typical knock level reported on SPNs 1357 & 6418.  The level of low frequency knock is reported ...";
CM_ SG_ 2364555262 EngnClndr6MxmmPrssrInrsRt "Engine Cylinder 6 Maximum Pressure Increase Rate: The maximum slope, in degrees of crank angle, of the pressure increase in engine cylinder 6 during the combustion cycle.";
CM_ SG_ 2364555262 EngnClndr6PrssrSnsrPrlmnrFMI "Engine Cylinder 6 Pressure Sensor Preliminary FMI: Used to identify the applicable J1939-73 FMI detected in the engine cylinder 6 pressure sensor.  In the case of multiple failures the most severe is communicated.A value of 31 is sent to indicate tha...";
CM_ SG_ 2364555262 EngnClndr6SnhrnsKnkLvl "Engine Cylinder 6 Synchronous Knock Level: Used to indicate the level of knock for engine cylinder 6. The level of knock is reported using a relative scale where 0% is least level of knock, and increasing levels indicate more knock until 100% indicat...";
CM_ BO_ 2364555518 "Engine Cylinder 7 Combustion Information";
CM_ SG_ 2364555518 EngineCylinder7HeatRelease "Engine Cylinder 7 Heat Release: The amount of heat produced during combustion in engine cylinder 7.  The negative range is to cover thermodynamic behavior during misfire.";
CM_ SG_ 2364555518 EngineCylinder7PeakPressure "Engine Cylinder 7 Peak Pressure: Peak pressure in engine cylinder 7 in combustion cycle.";
CM_ SG_ 2364555518 EngnClndr7LwFrqnKnkLvl "Engine Cylinder 7 Low Frequency Knock Level: Indicates the level of low frequency knock for engine cylinder 7. This knock occurs at frequencies below the typical knock level reported on SPNs 1358 & 6422.  The level of low frequency knock is reported ...";
CM_ SG_ 2364555518 EngnClndr7MxmmPrssrInrsRt "Engine Cylinder 7 Maximum Pressure Increase Rate: The maximum slope, in degrees of crank angle, of the pressure increase in engine cylinder 7 during the combustion cycle.";
CM_ SG_ 2364555518 EngnClndr7PrssrSnsrPrlmnrFMI "Engine Cylinder 7 Pressure Sensor Preliminary FMI: Used to identify the applicable J1939-73 FMI detected in the engine cylinder 7 pressure sensor. In the case of multiple failures the most severe is communicated.A value of 31 is sent to indicate that...";
CM_ SG_ 2364555518 EngnClndr7SnhrnsKnkLvl "Engine Cylinder 7 Synchronous Knock Level: Used to indicate the level of knock for engine cylinder 7. The level of knock is reported using a relative scale where 0% is least level of knock, and increasing levels indicate more knock until 100% indicat...";
CM_ BO_ 2364555774 "Engine Cylinder 8 Combustion Information";
CM_ SG_ 2364555774 EngineCylinder8HeatRelease "Engine Cylinder 8 Heat Release: The amount of heat produced during combustion in engine cylinder 8.  The negative range is to cover thermodynamic behavior during misfire.";
CM_ SG_ 2364555774 EngineCylinder8PeakPressure "Engine Cylinder 8 Peak Pressure: Peak pressure in engine cylinder 8 in combustion cycle.";
CM_ SG_ 2364555774 EngnClndr8LwFrqnKnkLvl "Engine Cylinder 8 Low Frequency Knock Level: Indicates the level of low frequency knock for engine cylinder 8. This knock occurs at frequencies below the typical knock level reported on SPNs 1359 & 6426.  The level of low frequency knock is reported ...";
CM_ SG_ 2364555774 EngnClndr8MxmmPrssrInrsRt "Engine Cylinder 8 Maximum Pressure Increase Rate: The maximum slope, in degrees of crank angle, of the pressure increase in engine cylinder 8 during the combustion cycle.";
CM_ SG_ 2364555774 EngnClndr8PrssrSnsrPrlmnrFMI "Engine Cylinder 8 Pressure Sensor Preliminary FMI: Used to identify the applicable J1939-73 FMI detected in the engine cylinder 8 pressure sensor.  In the case of multiple failures the most severe is communicated.A value of 31 is sent to indicate tha...";
CM_ SG_ 2364555774 EngnClndr8SnhrnsKnkLvl "Engine Cylinder 8 Synchronous Knock Level: Used to indicate the level of knock for engine cylinder 8. The level of knock is reported using a relative scale where 0% is least level of knock, and increasing levels indicate more knock until 100% indicat...";
CM_ BO_ 2364556030 "Engine Cylinder 9 Combustion Information";
CM_ SG_ 2364556030 EngineCylinder9HeatRelease "Engine Cylinder 9 Heat Release: The amount of heat produced during combustion in engine cylinder 9.  The negative range is to cover thermodynamic behavior during misfire.";
CM_ SG_ 2364556030 EngineCylinder9PeakPressure "Engine Cylinder 9 Peak Pressure: Peak pressure in engine cylinder 9 in combustion cycle.";
CM_ SG_ 2364556030 EngnClndr9LwFrqnKnkLvl "Engine Cylinder 9 Low Frequency Knock Level: Indicates the level of low frequency knock for engine cylinder 9. This knock occurs at frequencies below the typical knock level reported on SPNs 1360 & 6430.  The level of low frequency knock is reported ...";
CM_ SG_ 2364556030 EngnClndr9MxmmPrssrInrsRt "Engine Cylinder 9 Maximum Pressure Increase Rate: The maximum slope, in degrees of crank angle, of the pressure increase in engine cylinder 9 during the combustion cycle.";
CM_ SG_ 2364556030 EngnClndr9PrssrSnsrPrlmnrFMI "Engine Cylinder 9 Pressure Sensor Preliminary FMI: Used to identify the applicable J1939-73 FMI detected in the engine cylinder 9 pressure sensor.  In the case of multiple failures the most severe is communicated.A value of 31 is sent to indicate tha...";
CM_ SG_ 2364556030 EngnClndr9SnhrnsKnkLvl "Engine Cylinder 9 Synchronous Knock Level: Used to indicate the level of knock for engine cylinder 9. The level of knock is reported using a relative scale where 0% is least level of knock, and increasing levels indicate more knock until 100% indicat...";
CM_ BO_ 2364556286 "Engine Cylinder 10 Combustion Information";
CM_ SG_ 2364556286 EngineCylinder10HeatRelease "Engine Cylinder 10 Heat Release: The amount of heat produced during combustion in engine cylinder 10.  The negative range is to cover thermodynamic behavior during misfire.";
CM_ SG_ 2364556286 EngineCylinder10PeakPressure "Engine Cylinder 10 Peak Pressure: Peak pressure in engine cylinder 10 in combustion cycle.";
CM_ SG_ 2364556286 EngnClndr10LwFrqnKnkLvl "Engine Cylinder 10 Low Frequency Knock Level: Indicates the level of low frequency knock for engine cylinder 10. This knock occurs at frequencies below the typical knock level reported on SPNs 1361 & 6434.  The level of low frequency knock is reporte...";
CM_ SG_ 2364556286 EngnClndr10MxmmPrssrInrsRt "Engine Cylinder 10 Maximum Pressure Increase Rate: The maximum slope, in degrees of crank angle, of the pressure increase in engine cylinder 10 during the combustion cycle.";
CM_ SG_ 2364556286 EngnClndr10PrssrSnsrPrlmnrFMI "Engine Cylinder 10 Pressure Sensor Preliminary FMI: Used to identify the applicable J1939-73 FMI detected in the engine cylinder 10 pressure sensor.  In the case of multiple failures the most severe is communicated.A value of 31 is sent to indicate t...";
CM_ SG_ 2364556286 EngnClndr10SnhrnsKnkLvl "Engine Cylinder 10 Synchronous Knock Level: Used to indicate the level of knock for engine cylinder 10. The level of knock is reported using a relative scale where 0% is least level of knock, and increasing levels indicate more knock until 100% indic...";
CM_ BO_ 2364556542 "Engine Cylinder 11 Combustion Information";
CM_ SG_ 2364556542 EngineCylinder11HeatRelease "Engine Cylinder 11 Heat Release: The amount of heat produced during combustion in engine cylinder 11.  The negative range is to cover thermodynamic behavior during misfire.";
CM_ SG_ 2364556542 EngineCylinder11PeakPressure "Engine Cylinder 11 Peak Pressure: Peak pressure in engine cylinder 11 in combustion cycle.";
CM_ SG_ 2364556542 EngnClndr11LwFrqnKnkLvl "Engine Cylinder 11 Low Frequency Knock Level: Indicates the level of low frequency knock for engine cylinder 11. This knock occurs at frequencies below the typical knock level reported on SPNs 1362 & 6438.  The level of low frequency knock is reporte...";
CM_ SG_ 2364556542 EngnClndr11MxmmPrssrInrsRt "Engine Cylinder 11 Maximum Pressure Increase Rate: The maximum slope, in degrees of crank angle, of the pressure increase in engine cylinder 11 during the combustion cycle.";
CM_ SG_ 2364556542 EngnClndr11PrssrSnsrPrlmnrFMI "Engine Cylinder 11 Pressure Sensor Preliminary FMI: Used to identify the applicable J1939-73 FMI detected in the engine cylinder 11 pressure sensor.  In the case of multiple failures the most severe is communicated.A value of 31 is sent to indicate t...";
CM_ SG_ 2364556542 EngnClndr11SnhrnsKnkLvl "Engine Cylinder 11 Synchronous Knock Level: Used to indicate the level of knock for engine cylinder 11. The level of knock is reported using a relative scale where 0% is least level of knock, and increasing levels indicate more knock until 100% indic...";
CM_ BO_ 2364556798 "Engine Cylinder 12 Combustion Information";
CM_ SG_ 2364556798 EngineCylinder12HeatRelease "Engine Cylinder 12 Heat Release: The amount of heat produced during combustion in engine cylinder 12.  The negative range is to cover thermodynamic behavior during misfire.";
CM_ SG_ 2364556798 EngineCylinder12PeakPressure "Engine Cylinder 12 Peak Pressure: Peak pressure in engine cylinder 12 in combustion cycle.";
CM_ SG_ 2364556798 EngnClndr12LwFrqnKnkLvl "Engine Cylinder 12 Low Frequency Knock Level: Indicates the level of low frequency knock for engine cylinder 12. This knock occurs at frequencies below the typical knock level reported on SPNs 1363 & 6442.  The level of low frequency knock is reporte...";
CM_ SG_ 2364556798 EngnClndr12MxmmPrssrInrsRt "Engine Cylinder 12 Maximum Pressure Increase Rate: The maximum slope, in degrees of crank angle, of the pressure increase in engine cylinder 12 during the combustion cycle.";
CM_ SG_ 2364556798 EngnClndr12PrssrSnsrPrlmnrFMI "Engine Cylinder 12 Pressure Sensor Preliminary FMI: Used to identify the applicable J1939-73 FMI detected in the engine cylinder 12 pressure sensor.  In the case of multiple failures the most severe is communicated.A value of 31 is sent to indicate t...";
CM_ SG_ 2364556798 EngnClndr12SnhrnsKnkLvl "Engine Cylinder 12 Synchronous Knock Level: Used to indicate the level of knock for engine cylinder 12. The level of knock is reported using a relative scale where 0% is least level of knock, and increasing levels indicate more knock until 100% indic...";
CM_ BO_ 2364557054 "Engine Cylinder 13 Combustion Information";
CM_ SG_ 2364557054 EngineCylinder13HeatRelease "Engine Cylinder 13 Heat Release: The amount of heat produced during combustion in engine cylinder 13.  The negative range is to cover thermodynamic behavior during misfire.";
CM_ SG_ 2364557054 EngineCylinder13PeakPressure "Engine Cylinder 13 Peak Pressure: Peak pressure in engine cylinder 13 in combustion cycle.";
CM_ SG_ 2364557054 EngnClndr13LwFrqnKnkLvl "Engine Cylinder 13 Low Frequency Knock Level: Indicates the level of low frequency knock for engine cylinder 13. This knock occurs at frequencies below the typical knock level reported on SPNs 1364 & 6446.  The level of low frequency knock is reporte...";
CM_ SG_ 2364557054 EngnClndr13MxmmPrssrInrsRt "Engine Cylinder 13 Maximum Pressure Increase Rate: The maximum slope, in degrees of crank angle, of the pressure increase in engine cylinder 13 during the combustion cycle.";
CM_ SG_ 2364557054 EngnClndr13PrssrSnsrPrlmnrFMI "Engine Cylinder 13 Pressure Sensor Preliminary FMI: Used to identify the applicable J1939-73 FMI detected in the engine cylinder 13 pressure sensor.  In the case of multiple failures the most severe is communicated.A value of 31 is sent to indicate t...";
CM_ SG_ 2364557054 EngnClndr13SnhrnsKnkLvl "Engine Cylinder 13 Synchronous Knock Level: Used to indicate the level of knock for engine cylinder 13. The level of knock is reported using a relative scale where 0% is least level of knock, and increasing levels indicate more knock until 100% indic...";
CM_ BO_ 2364557310 "Engine Cylinder 14 Combustion Information";
CM_ SG_ 2364557310 EngineCylinder14HeatRelease "Engine Cylinder 14 Heat Release: The amount of heat produced during combustion in engine cylinder 14.  The negative range is to cover thermodynamic behavior during misfire.";
CM_ SG_ 2364557310 EngineCylinder14PeakPressure "Engine Cylinder 14 Peak Pressure: Peak pressure in engine cylinder 14 in combustion cycle.";
CM_ SG_ 2364557310 EngnClndr14LwFrqnKnkLvl "Engine Cylinder 14 Low Frequency Knock Level: Indicates the level of low frequency knock for engine cylinder 14. This knock occurs at frequencies below the typical knock level reported on SPNs 1365 & 6450.  The level of low frequency knock is reporte...";
CM_ SG_ 2364557310 EngnClndr14MxmmPrssrInrsRt "Engine Cylinder 14 Maximum Pressure Increase Rate: The maximum slope, in degrees of crank angle, of the pressure increase in engine cylinder 14 during the combustion cycle.";
CM_ SG_ 2364557310 EngnClndr14PrssrSnsrPrlmnrFMI "Engine Cylinder 14 Pressure Sensor Preliminary FMI: Used to identify the applicable J1939-73 FMI detected in the engine cylinder 14 pressure sensor.  In the case of multiple failures the most severe is communicated.A value of 31 is sent to indicate t...";
CM_ SG_ 2364557310 EngnClndr14SnhrnsKnkLvl "Engine Cylinder 14 Synchronous Knock Level: Used to indicate the level of knock for engine cylinder 14. The level of knock is reported using a relative scale where 0% is least level of knock, and increasing levels indicate more knock until 100% indic...";
CM_ BO_ 2364557566 "Engine Cylinder 15 Combustion Information";
CM_ SG_ 2364557566 EngineCylinder15HeatRelease "Engine Cylinder 15 Heat Release: The amount of heat produced during combustion in engine cylinder 15.  The negative range is to cover thermodynamic behavior during misfire.";
CM_ SG_ 2364557566 EngineCylinder15PeakPressure "Engine Cylinder 15 Peak Pressure: Peak pressure in engine cylinder 15 in combustion cycle.";
CM_ SG_ 2364557566 EngnClndr15LwFrqnKnkLvl "Engine Cylinder 15 Low Frequency Knock Level: Indicates the level of low frequency knock for engine cylinder 15. This knock occurs at frequencies below the typical knock level reported on SPNs 1366 & 6454.  The level of low frequency knock is reporte...";
CM_ SG_ 2364557566 EngnClndr15MxmmPrssrInrsRt "Engine Cylinder 15 Maximum Pressure Increase Rate: The maximum slope, in degrees of crank angle, of the pressure increase in engine cylinder 15 during the combustion cycle.";
CM_ SG_ 2364557566 EngnClndr15PrssrSnsrPrlmnrFMI "Engine Cylinder 15 Pressure Sensor Preliminary FMI: Used to identify the applicable J1939-73 FMI detected in the engine cylinder 15 pressure sensor.  In the case of multiple failures the most severe is communicated.A value of 31 is sent to indicate t...";
CM_ SG_ 2364557566 EngnClndr15SnhrnsKnkLvl "Engine Cylinder 15 Synchronous Knock Level: Used to indicate the level of knock for engine cylinder 15. The level of knock is reported using a relative scale where 0% is least level of knock, and increasing levels indicate more knock until 100% indic...";
CM_ BO_ 2364557822 "Engine Cylinder 16 Combustion Information";
CM_ SG_ 2364557822 EngineCylinder16HeatRelease "Engine Cylinder 16 Heat Release: The amount of heat produced during combustion in engine cylinder 16.  The negative range is to cover thermodynamic behavior during misfire.";
CM_ SG_ 2364557822 EngineCylinder16PeakPressure "Engine Cylinder 16 Peak Pressure: Peak pressure in engine cylinder 16 in combustion cycle.";
CM_ SG_ 2364557822 EngnClndr16LwFrqnKnkLvl "Engine Cylinder 16 Low Frequency Knock Level: Indicates the level of low frequency knock for engine cylinder 16. This knock occurs at frequencies below the typical knock level reported on SPNs 1367 & 6458.  The level of low frequency knock is reporte...";
CM_ SG_ 2364557822 EngnClndr16MxmmPrssrInrsRt "Engine Cylinder 16 Maximum Pressure Increase Rate: The maximum slope, in degrees of crank angle, of the pressure increase in engine cylinder 16 during the combustion cycle.";
CM_ SG_ 2364557822 EngnClndr16PrssrSnsrPrlmnrFMI "Engine Cylinder 16 Pressure Sensor Preliminary FMI: Used to identify the applicable J1939-73 FMI detected in the engine cylinder 16 pressure sensor.  In the case of multiple failures the most severe is communicated.A value of 31 is sent to indicate t...";
CM_ SG_ 2364557822 EngnClndr16SnhrnsKnkLvl "Engine Cylinder 16 Synchronous Knock Level: Used to indicate the level of knock for engine cylinder 16. The level of knock is reported using a relative scale where 0% is least level of knock, and increasing levels indicate more knock until 100% indic...";
CM_ BO_ 2364558078 "Engine Cylinder 17 Combustion Information";
CM_ SG_ 2364558078 EngineCylinder17HeatRelease "Engine Cylinder 17 Heat Release: The amount of heat produced during combustion in engine cylinder 17.  The negative range is to cover thermodynamic behavior during misfire.";
CM_ SG_ 2364558078 EngineCylinder17PeakPressure "Engine Cylinder 17 Peak Pressure: Peak pressure in engine cylinder 17 in combustion cycle.";
CM_ SG_ 2364558078 EngnClndr17LwFrqnKnkLvl "Engine Cylinder 17 Low Frequency Knock Level: Indicates the level of low frequency knock for engine cylinder 17. This knock occurs at frequencies below the typical knock level reported on SPNs 1368 & 6462.  The level of low frequency knock is reporte...";
CM_ SG_ 2364558078 EngnClndr17MxmmPrssrInrsRt "Engine Cylinder 17 Maximum Pressure Increase Rate: The maximum slope, in degrees of crank angle, of the pressure increase in engine cylinder 17 during the combustion cycle.";
CM_ SG_ 2364558078 EngnClndr17PrssrSnsrPrlmnrFMI "Engine Cylinder 17 Pressure Sensor Preliminary FMI: Used to identify the applicable J1939-73 FMI detected in the engine cylinder 17 pressure sensor.  In the case of multiple failures the most severe is communicated.A value of 31 is sent to indicate t...";
CM_ SG_ 2364558078 EngnClndr17SnhrnsKnkLvl "Engine Cylinder 17 Synchronous Knock Level: Used to indicate the level of knock for engine cylinder 17. The level of knock is reported using a relative scale where 0% is least level of knock, and increasing levels indicate more knock until 100% indic...";
CM_ BO_ 2364558334 "Engine Cylinder 18 Combustion Information";
CM_ SG_ 2364558334 EngineCylinder18HeatRelease "Engine Cylinder 18 Heat Release: The amount of heat produced during combustion in engine cylinder 18.  The negative range is to cover thermodynamic behavior during misfire.";
CM_ SG_ 2364558334 EngineCylinder18PeakPressure "Engine Cylinder 18 Peak Pressure: Peak pressure in engine cylinder 18 in combustion cycle.";
CM_ SG_ 2364558334 EngnClndr18LwFrqnKnkLvl "Engine Cylinder 18 Low Frequency Knock Level: Indicates the level of low frequency knock for engine cylinder 18. This knock occurs at frequencies below the typical knock level reported on SPNs 1369 & 6466.  The level of low frequency knock is reporte...";
CM_ SG_ 2364558334 EngnClndr18MxmmPrssrInrsRt "Engine Cylinder 18 Maximum Pressure Increase Rate: The maximum slope, in degrees of crank angle, of the pressure increase in engine cylinder 18 during the combustion cycle.";
CM_ SG_ 2364558334 EngnClndr18PrssrSnsrPrlmnrFMI "Engine Cylinder 18 Pressure Sensor Preliminary FMI: Used to identify the applicable J1939-73 FMI detected in the engine cylinder 18 pressure sensor. In the case of multiple failures the most severe is communicated.A value of 31 is sent to indicate th...";
CM_ SG_ 2364558334 EngnClndr18SnhrnsKnkLvl "Engine Cylinder 18 Synchronous Knock Level: Used to indicate the level of knock for engine cylinder 18. The level of knock is reported using a relative scale where 0% is least level of knock, and increasing levels indicate more knock until 100% indic...";
CM_ BO_ 2364558590 "Engine Cylinder 19 Combustion Information";
CM_ SG_ 2364558590 EngineCylinder19HeatRelease "Engine Cylinder 19 Heat Release: The amount of heat produced during combustion in engine cylinder 19.  The negative range is to cover thermodynamic behavior during misfire.";
CM_ SG_ 2364558590 EngineCylinder19PeakPressure "Engine Cylinder 19 Peak Pressure: Peak pressure in engine cylinder 19 in combustion cycle.";
CM_ SG_ 2364558590 EngnClndr19LwFrqnKnkLvl "Engine Cylinder 19 Low Frequency Knock Level: Indicates the level of low frequency knock for engine cylinder 19. This knock occurs at frequencies below the typical knock level reported on SPNs 1370 & 6470.  The level of low frequency knock is reporte...";
CM_ SG_ 2364558590 EngnClndr19MxmmPrssrInrsRt "Engine Cylinder 19 Maximum Pressure Increase Rate: The maximum slope, in degrees of crank angle, of the pressure increase in engine cylinder 19 during the combustion cycle.";
CM_ SG_ 2364558590 EngnClndr19PrssrSnsrPrlmnrFMI "Engine Cylinder 19 Pressure Sensor Preliminary FMI: Used to identify the applicable J1939-73 FMI detected in the engine cylinder 19 pressure sensor.  In the case of multiple failures the most severe is communicated.A value of 31 is sent to indicate t...";
CM_ SG_ 2364558590 EngnClndr19SnhrnsKnkLvl "Engine Cylinder 19 Synchronous Knock Level: Used to indicate the level of knock for engine cylinder 19. The level of knock is reported using a relative scale where 0% is least level of knock, and increasing levels indicate more knock until 100% indic...";
CM_ BO_ 2364558846 "Engine Cylinder 20 Combustion Information";
CM_ SG_ 2364558846 EngineCylinder20HeatRelease "Engine Cylinder 20 Heat Release: The amount of heat produced during combustion in engine cylinder 20.  The negative range is to cover thermodynamic behavior during misfire.";
CM_ SG_ 2364558846 EngineCylinder20PeakPressure "Engine Cylinder 20 Peak Pressure: Peak pressure in engine cylinder 20 in combustion cycle.";
CM_ SG_ 2364558846 EngnClndr20LwFrqnKnkLvl "Engine Cylinder 20 Low Frequency Knock Level: Indicates the level of low frequency knock for engine cylinder 20. This knock occurs at frequencies below the typical knock level reported on SPNs 1371 & 6474.  The level of low frequency knock is reporte...";
CM_ SG_ 2364558846 EngnClndr20MxmmPrssrInrsRt "Engine Cylinder 20 Maximum Pressure Increase Rate: The maximum slope, in degrees of crank angle, of the pressure increase in engine cylinder 20 during the combustion cycle.";
CM_ SG_ 2364558846 EngnClndr20PrssrSnsrPrlmnrFMI "Engine Cylinder 20 Pressure Sensor Preliminary FMI: Used to identify the applicable J1939-73 FMI detected in the engine cylinder 20 pressure sensor.  In the case of multiple failures the most severe is communicated.A value of 31 is sent to indicate t...";
CM_ SG_ 2364558846 EngnClndr20SnhrnsKnkLvl "Engine Cylinder 20 Synchronous Knock Level: Used to indicate the level of knock for engine cylinder 20. The level of knock is reported using a relative scale where 0% is least level of knock, and increasing levels indicate more knock until 100% indic...";
CM_ BO_ 2364564478 "Fuel Information 5 (Gaseous)";
CM_ SG_ 2364564478 EngnGssFlVlvNmnlDrtnCmmnd "Engine Gaseous Fuel Valve Nominal Duration Command: Amount of time the gaseous fuel valves are activated.  It's a nominal value used for all the gaseous fuel valves in the engine.Note: Please see SPNs 6658 - 6677 for duration command for each gaseous...";
CM_ SG_ 2364564478 EngnGssFlVlvNmnlStrtfAttnCmmnd "Engine Gaseous Fuel Valve Nominal Start of Actuation Command: The angle, relative to the TDC of each cylinder, with 0 being the TDC before the power stroke commences, at the which gaseous fuel valves are activated to open.  It's a nominal value used ...";
CM_ SG_ 2364564478 EngnPrChmrFlVlvNmnlDrtnCmmnd "Engine Pre-Chamber Fuel Valve Nominal Duration Command: Amount of time the pre-chamber fuel valves are activated. It's a nominal value used for all the prechamber fuel valves in the engine.Note: Please see SPNs 9591-9610 for duration command for each...";
CM_ SG_ 2364564478 EPCFVvNSttAttCd "Engine Pre-Chamber Fuel Valve Nominal Start of Actuation Command: The angle, relative to the TDC of each cylinder, with 0 being the TDC before the power stroke commences, at the which pre-chamber fuel valves are activated to open. It's a nominal valu...";
CM_ BO_ 2364564734 "Engine Gaseous Fuel Valve Duration Command 1";
CM_ SG_ 2364564734 EngnGssFlVlv1DrtnCmmnd "Engine Gaseous Fuel Valve 1 Duration Command: Amount of time the gaseous fuel valve 1 is activated.";
CM_ SG_ 2364564734 EngnGssFlVlv2DrtnCmmnd "Engine Gaseous Fuel Valve 2 Duration Command: Amount of time the gaseous fuel valve 2 is activated.";
CM_ SG_ 2364564734 EngnGssFlVlv3DrtnCmmnd "Engine Gaseous Fuel Valve 3 Duration Command: Amount of time the gaseous fuel valve 3 is activated.";
CM_ SG_ 2364564734 EngnGssFlVlv4DrtnCmmnd "Engine Gaseous Fuel Valve 4 Duration Command: Amount of time the gaseous fuel valve 4 is activated.";
CM_ BO_ 2364564990 "Engine Gaseous Fuel Valve Duration Command 2";
CM_ SG_ 2364564990 EngnGssFlVlv5DrtnCmmnd "Engine Gaseous Fuel Valve 5 Duration Command: Amount of time the gaseous fuel valve 5 is activated.";
CM_ SG_ 2364564990 EngnGssFlVlv6DrtnCmmnd "Engine Gaseous Fuel Valve 6 Duration Command: Amount of time the gaseous fuel valve 6 is activated.";
CM_ SG_ 2364564990 EngnGssFlVlv7DrtnCmmnd "Engine Gaseous Fuel Valve 7 Duration Command: Amount of time the gaseous fuel valve 7 is activated.";
CM_ SG_ 2364564990 EngnGssFlVlv8DrtnCmmnd "Engine Gaseous Fuel Valve 8 Duration Command: Amount of time the gaseous fuel valve 8 is activated.";
CM_ BO_ 2364565246 "Engine Gaseous Fuel Valve Duration Command 3";
CM_ SG_ 2364565246 EngnGssFlVlv10DrtnCmmnd "Engine Gaseous Fuel Valve 10 Duration Command: Amount of time the gaseous fuel valve 10 is activated.";
CM_ SG_ 2364565246 EngnGssFlVlv11DrtnCmmnd "Engine Gaseous Fuel Valve 11 Duration Command: Amount of time the gaseous fuel valve 11 is activated.";
CM_ SG_ 2364565246 EngnGssFlVlv12DrtnCmmnd "Engine Gaseous Fuel Valve 12 Duration Command: Amount of time the gaseous fuel valve 12 is activated.";
CM_ SG_ 2364565246 EngnGssFlVlv9DrtnCmmnd "Engine Gaseous Fuel Valve 9 Duration Command: Amount of time the gaseous fuel valve 9 is activated.";
CM_ BO_ 2364565502 "Engine Gaseous Fuel Valve Duration Command 4";
CM_ SG_ 2364565502 EngnGssFlVlv13DrtnCmmnd "Engine Gaseous Fuel Valve 13 Duration Command: Amount of time the gaseous fuel valve 13 is activated.";
CM_ SG_ 2364565502 EngnGssFlVlv14DrtnCmmnd "Engine Gaseous Fuel Valve 14 Duration Command: Amount of time the gaseous fuel valve 14 is activated.";
CM_ SG_ 2364565502 EngnGssFlVlv15DrtnCmmnd "Engine Gaseous Fuel Valve 15 Duration Command: Amount of time the gaseous fuel valve 15 is activated.";
CM_ SG_ 2364565502 EngnGssFlVlv16DrtnCmmnd "Engine Gaseous Fuel Valve 16 Duration Command: Amount of time the gaseous fuel valve 16 is activated.";
CM_ BO_ 2364565758 "Engine Gaseous Fuel Valve Duration Command 5";
CM_ SG_ 2364565758 EngnGssFlVlv17DrtnCmmnd "Engine Gaseous Fuel Valve 17 Duration Command: Amount of time the gaseous fuel valve 17 is activated.";
CM_ SG_ 2364565758 EngnGssFlVlv18DrtnCmmnd "Engine Gaseous Fuel Valve 18 Duration Command: Amount of time the gaseous fuel valve 18 is activated.";
CM_ SG_ 2364565758 EngnGssFlVlv19DrtnCmmnd "Engine Gaseous Fuel Valve 19 Duration Command: Amount of time the gaseous fuel valve 19 is activated.";
CM_ SG_ 2364565758 EngnGssFlVlv20DrtnCmmnd "Engine Gaseous Fuel Valve 20 Duration Command: Amount of time the gaseous fuel valve 20 is activated.";
CM_ BO_ 2364566014 "Engine Gaseous Fuel Valve Start of Actuation Command 1";
CM_ SG_ 2364566014 EngnGssFlVlv1StrtfAttnCmmnd "Engine Gaseous Fuel Valve 1 Start of Actuation Command: The angle, relative to the TDC of cylinder 1, with 0 being the TDC before the power stroke commences, at the which gaseous fuel valve 1 is activated to open.Timings after TDC are referred with p...";
CM_ SG_ 2364566014 EngnGssFlVlv2StrtfAttnCmmnd "Engine Gaseous Fuel Valve 2 Start of Actuation Command: The angle, relative to the TDC of cylinder 2, with 0 being the TDC before the power stroke commences, at the which gaseous fuel valve 2 is activated to open.Timings after TDC are referred with p...";
CM_ SG_ 2364566014 EngnGssFlVlv3StrtfAttnCmmnd "Engine Gaseous Fuel Valve 3 Start of Actuation Command: The angle, relative to the TDC of cylinder 3, with 0 being the TDC before the power stroke commences, at the which gaseous fuel valve 3 is activated to open.Timings after TDC are referred with p...";
CM_ SG_ 2364566014 EngnGssFlVlv4StrtfAttnCmmnd "Engine Gaseous Fuel Valve 4 Start of Actuation Command: The angle, relative to the TDC of cylinder 4, with 0 being the TDC before the power stroke commences, at the which gaseous fuel valve 4 is activated to open.Timings after TDC are referred with p...";
CM_ BO_ 2364566270 "Engine Gaseous Fuel Valve Start of Actuation Command 2";
CM_ SG_ 2364566270 EngnGssFlVlv5StrtfAttnCmmnd "Engine Gaseous Fuel Valve 5 Start of Actuation Command: The angle, relative to the TDC of cylinder 5, with 0 being the TDC before the power stroke commences, at the which gaseous fuel valve 5 is activated to open.Timings after TDC are referred with p...";
CM_ SG_ 2364566270 EngnGssFlVlv6StrtfAttnCmmnd "Engine Gaseous Fuel Valve 6 Start of Actuation Command: The angle, relative to the TDC of cylinder 6, with 0 being the TDC before the power stroke commences, at the which gaseous fuel valve 6 is activated to open.Timings after TDC are referred with p...";
CM_ SG_ 2364566270 EngnGssFlVlv7StrtfAttnCmmnd "Engine Gaseous Fuel Valve 7 Start of Actuation Command: The angle, relative to the TDC of cylinder 7, with 0 being the TDC before the power stroke commences, at the which gaseous fuel valve 7 is activated to open.Timings after TDC are referred with p...";
CM_ SG_ 2364566270 EngnGssFlVlv8StrtfAttnCmmnd "Engine Gaseous Fuel Valve 8 Start of Actuation Command: The angle, relative to the TDC of cylinder 8, with 0 being the TDC before the power stroke commences, at the which gaseous fuel valve 8 is activated to open.Timings after TDC are referred with p...";
CM_ BO_ 2364566526 "Engine Gaseous Fuel Valve Start of Actuation Command 3";
CM_ SG_ 2364566526 EngnGssFlVlv10StrtfAttnCmmnd "Engine Gaseous Fuel Valve 10 Start of Actuation Command: The angle, relative to the TDC of cylinder 10, with 0 being the TDC before the power stroke commences, at the which gaseous fuel valve 10 is activated to open.Timings after TDC are referred wit...";
CM_ SG_ 2364566526 EngnGssFlVlv11StrtfAttnCmmnd "Engine Gaseous Fuel Valve 11 Start of Actuation Command: The angle, relative to the TDC of cylinder 11, with 0 being the TDC before the power stroke commences, at the which gaseous fuel valve 11 is activated to open.Timings after TDC are referred wit...";
CM_ SG_ 2364566526 EngnGssFlVlv12StrtfAttnCmmnd "Engine Gaseous Fuel Valve 12 Start of Actuation Command: The angle, relative to the TDC of cylinder 12, with 0 being the TDC before the power stroke commences, at the which gaseous fuel valve 12 is activated to open.Timings after TDC are referred wit...";
CM_ SG_ 2364566526 EngnGssFlVlv9StrtfAttnCmmnd "Engine Gaseous Fuel Valve 9 Start of Actuation Command: The angle, relative to the TDC of cylinder 9, with 0 being the TDC before the power stroke commences, at the which gaseous fuel valve 9 is activated to open.Timings after TDC are referred with p...";
CM_ BO_ 2364566782 "Engine Gaseous Fuel Valve Start of Actuation Command 4";
CM_ SG_ 2364566782 EngnGssFlVlv13StrtfAttnCmmnd "Engine Gaseous Fuel Valve 13 Start of Actuation Command: The angle, relative to the TDC of cylinder 13, with 0 being the TDC before the power stroke commences, at the which gaseous fuel valve 13 is activated to open.Timings after TDC are referred wit...";
CM_ SG_ 2364566782 EngnGssFlVlv14StrtfAttnCmmnd "Engine Gaseous Fuel Valve 14 Start of Actuation Command: The angle, relative to the TDC of cylinder 14, with 0 being the TDC before the power stroke commences, at the which gaseous fuel valve 14 is activated to open.Timings after TDC are referred wit...";
CM_ SG_ 2364566782 EngnGssFlVlv15StrtfAttnCmmnd "Engine Gaseous Fuel Valve 15 Start of Actuation Command: The angle, relative to the TDC of cylinder 15, with 0 being the TDC before the power stroke commences, at the which gaseous fuel valve 15 is activated to open.Timings after TDC are referred wit...";
CM_ SG_ 2364566782 EngnGssFlVlv16StrtfAttnCmmnd "Engine Gaseous Fuel Valve 16 Start of Actuation Command: The angle, relative to the TDC of cylinder 16, with 0 being the TDC before the power stroke commences, at the which gaseous fuel valve 16 is activated to open.Timings after TDC are referred wit...";
CM_ BO_ 2364567038 "Engine Gaseous Fuel Valve Start of Actuation Command 5";
CM_ SG_ 2364567038 EngnGssFlVlv17StrtfAttnCmmnd "Engine Gaseous Fuel Valve 17 Start of Actuation Command: The angle, relative to the TDC of cylinder 17, with 0 being the TDC before the power stroke commences, at the which gaseous fuel valve 17 is activated to open.Timings after TDC are referred wit...";
CM_ SG_ 2364567038 EngnGssFlVlv18StrtfAttnCmmnd "Engine Gaseous Fuel Valve 18 Start of Actuation Command: The angle, relative to the TDC of cylinder 18, with 0 being the TDC before the power stroke commences, at the which gaseous fuel valve 18 is activated to open.Timings after TDC are referred wit...";
CM_ SG_ 2364567038 EngnGssFlVlv19StrtfAttnCmmnd "Engine Gaseous Fuel Valve 19 Start of Actuation Command: The angle, relative to the TDC of cylinder 19, with 0 being the TDC before the power stroke commences, at the which gaseous fuel valve 19 is activated to open.Timings after TDC are referred wit...";
CM_ SG_ 2364567038 EngnGssFlVlv20StrtfAttnCmmnd "Engine Gaseous Fuel Valve 20 Start of Actuation Command: The angle, relative to the TDC of cylinder 20, with 0 being the TDC before the power stroke commences, at the which gaseous fuel valve 20 is activated to open.Timings after TDC are referred wit...";
CM_ BO_ 2364567294 "Fuel Pump Actuator Control Command";
CM_ SG_ 2364567294 EngnFlInjtnPmp1FlCntrlVlvCmmnd "Engine Fuel Injection Pump 1 Fuel Control Valve Command: The control command to fuel control valve in fuel pump 1, normalized to percent, where 0% represents fully closed and 100% represents fully open.";
CM_ SG_ 2364567294 EngnFlInjtnPmp2FlCntrlVlvCmmnd "Engine Fuel Injection Pump 2 Fuel Control Valve Command: The control command to fuel control valve in fuel pump 2, normalized to percent, where 0% represents fully closed and 100% represents fully open.";
CM_ BO_ 2364575998 "High Voltage Energy Storage System Data 1";
CM_ SG_ 2364575998 HVESSAvailableDischargePower "HVESS Available Discharge Power: The rate at which the High Voltage Energy Storage System (or Pack 1 in systems with only one pack) can currently provide energy for propulsion or other uses.This parameter provides HVES system level information. If th...";
CM_ SG_ 2364575998 HVESSAvailableChargePower "HVESS Available Charge Power: The rate at which the High Voltage Energy Storage System (or Pack 1 in systems with only one pack) can currently receive energy from a regenerative or recharging system.This parameter provides HVES system level informati...";
CM_ SG_ 2364575998 HVESSVoltageLevel "HVESS Voltage Level: The voltage level of the High Voltage Energy Storage System (or Pack 1 in systems with only one pack). This parameter should be synchronized with SPN 5920 (HVESS Current) such that a realized power value can be calculated.  If th...";
CM_ SG_ 2364575998 HVESSCurrent "HVESS Current: The current in or out of the High Voltage Energy Storage System (or Pack 1 in systems with only one pack). This parameter should be synchronized with SPN 5919 (HVESS Voltage Level) such that a realized power value can be calculated.  T...";
CM_ BO_ 2364576254 "High Voltage Energy Storage System Data 2";
CM_ SG_ 2364576254 HVESSFastUpdateStateofCharge "HVESS Fast Update State of Charge: Indicates the High Voltage Energy Storage System (or Pack 1 in systems with only one pack) state of charge.  0% means no charge remaining, 100% means the system is fully charged in terms of physical limits of the en...";
CM_ SG_ 2364576254 HVESSHighestCellVoltage "HVESS Highest Cell Voltage: The highest voltage level reported by any cell in the High Voltage Energy Storage System (or Pack 1 in systems with only one pack). If a single voltage sensor covers more than one cell, the value in this parameter is for t...";
CM_ SG_ 2364576254 HVESSLowestCellVoltage "HVESS Lowest Cell Voltage: The lowest voltage level reported by any cell in the High Voltage Energy Storage System (or Pack 1 in systems with only one pack). If a single voltage sensor covers more than one cell, the value in this parameter is for the...";
CM_ SG_ 2364576254 HVESSCllVltgDffrntlStts "HVESS Cell Voltage Differential Status: Indicates whether or not the differential between the highest and lowest cell voltages are within acceptable limits, according to the High Voltage Energy Storage System (or Pack 1 in systems with only one pack)...";
CM_ BO_ 2364576510 "High Voltage Energy Storage System Data 3";
CM_ SG_ 2364576510 HVESSHighestCellTemperature "HVESS Highest Cell Temperature: The highest temperature level reported by any cell in the High Voltage Energy Storage System (or Pack 1 in systems with only one pack).  If a single temperature sensor covers more than one cell, the value in this param...";
CM_ SG_ 2364576510 HVESSLowestCellTemperature "HVESS Lowest Cell Temperature: The lowest temperature level reported by any cell in the High Voltage Energy Storage System (or Pack 1 in systems with only one pack).  If a single temperature sensor covers more than one cell, the value in this paramet...";
CM_ SG_ 2364576510 HVESSAverageCellTemperature "HVESS Average Cell Temperature: The average temperature level of all cells in the High Voltage Energy Storage System (or Pack 1 in systems with only one pack).This parameter provides HVES system level information. If there are multiple packs in the s...";
CM_ SG_ 2364576510 HVESSCllTmprtrDffrntlStts "HVESS Cell Temperature Differential Status: Indicates whether or not the differential between the highest and lowest cell temperatures are within acceptable limits per the High Voltage Energy Storage System (or Pack 1 in systems with only one pack). ...";
CM_ BO_ 2364576766 "High Voltage Energy Storage System Data 4";
CM_ SG_ 2364576766 HVESSDischargeCapacity "HVESS Discharge Capacity: The amount of stored electrical charge in the High Voltage Energy Storage System (or Pack 1 in systems with only one pack) that is available for use by the hybrid system, i.e. “how full is the tank”.  See SPN 8205 (HVESS Dis...";
CM_ SG_ 2364576766 HVESSChargeCapacity "HVESS Charge Capacity: The amount of unused electrical charge storage in the High Voltage Energy Storage System (or Pack 1 in systems with only one pack) that is available to be filled by charging, i.e. “how much empty space is remaining in the tank”...";
CM_ SG_ 2364576766 HVESSCellBalancingCount "HVESS Cell Balancing Count: The number of cells that are currently being balanced in the High Voltage Energy Storage System (or Pack 1 in systems with only one pack).This parameter provides HVES system level information. If there are multiple packs i...";
CM_ BO_ 2364577022 "High Voltage Energy Storage System Data 5";
CM_ SG_ 2364577022 HVESSDischargeCurrentLimit "HVESS Discharge Current Limit: The maximum permissible current flow out of the High Voltage Energy Storage System (or Pack 1 in systems with only one pack). This parameter is defined from the high voltage energy storage system's point of view.A negat...";
CM_ SG_ 2364577022 HVESSChargeCurrentLimit "HVESS Charge Current Limit: The maximum permissible current flow into the High Voltage Energy Storage System (or Pack 1 in systems with only one pack). This parameter is defined from the high voltage energy storage system's point of view.A positive v...";
CM_ SG_ 2364577022 HVESSMinimumCellStateofCharge "HVESS Minimum Cell State of Charge: Indicates the state of charge of the lowest-charged cell in the High Voltage Energy Storage System (or Pack 1 in systems with only one pack).  0% means no charge remaining, 100% means the cell is fully charged.   I...";
CM_ SG_ 2364577022 HVESSMaximumCellStateofCharge "HVESS Maximum Cell State of Charge: Indicates the state of charge of the highest-charged cell in the High Voltage Energy Storage System (or Pack 1 in systems with only one pack).  0% means no charge remaining, 100% means the cell is fully charged.  I...";
CM_ BO_ 2364577278 "High Voltage Energy Storage System Data 6";
CM_ SG_ 2364577278 HVESSBusVoltage "HVESS Bus Voltage: The voltage level of the high voltage bus, as measured by the High Voltage Energy Storage System (or Pack 1 in systems with only one pack) on the bus side (not the battery side) of its contactors.This parameter provides HVES system...";
CM_ SG_ 2364577278 HVESSIgnitionVoltage "HVESS Ignition Voltage: The voltage level at the ignition input of the High Voltage Energy Storage System (or Pack 1 in systems with only one pack) controller.This parameter provides HVES system level information. If there are multiple packs in the s...";
CM_ SG_ 2364577278 HVESSIntakeCoolantTemperature "HVESS Intake Coolant Temperature: The temperature of liquid coolant as it enters the High Voltage Energy Storage System (or Pack 1 in systems with only one pack).This parameter provides HVES system level information. If there are multiple packs in th...";
CM_ SG_ 2364577278 HVESSOutletCoolantTemperature "HVESS Outlet Coolant Temperature: The temperature of liquid coolant as it exits the High Voltage Energy Storage System (or Pack 1 in systems with only one pack).This parameter provides HVES system level information. If there are multiple packs in the...";
CM_ SG_ 2364577278 HVESSElectronicsTemperature "HVESS Electronics Temperature: The temperature of the electronics or control modules in the High Voltage Energy Storage System (or Pack 1 in systems with only one pack).  If there are multiple temperature sensors then this parameter would be set to t...";
CM_ SG_ 2364577278 HVESSTemperature "HVESS Temperature: The temperature of High Voltage Energy Storage System (or Pack 1 in systems with only one pack). The value may be determined from a unique sensor specifically for this purpose, or by aggregating various temperature sensor readings ...";
CM_ BO_ 2364577534 "High Voltage Energy Storage System Status 1";
CM_ SG_ 2364577534 HVESSHghVltgBsPstvCnttrStt "HVESS High-Voltage Bus (Positive) Contactor State: Position of the High Voltage Energy Storage System (or Pack 1 in systems with only one pack) positive side bus contactor.  When this contactor is closed, the positive side of this HVES instance is co...";
CM_ SG_ 2364577534 HVESSHghVltgBsNgtvCnttrStt "HVESS High-Voltage Bus (Negative) Contactor State: Position of the High Voltage Energy Storage System (or Pack 1 in systems with only one pack) negative side bus contactor.  When this contactor is closed, the negative side of this HVES instance is co...";
CM_ SG_ 2364577534 HVESSHghVltgBsDsnntFrwrnng "HVESS High-Voltage Bus Disconnect Forewarning: Indicates that the High Voltage Energy Storage System (or Pack 1 in systems with only one pack) is about to disconnect from the high voltage bus due to unacceptable conditions.This parameter provides HVE...";
CM_ SG_ 2364577534 HVESSHghVltgBsPrChrgRlStt "HVESS High-Voltage Bus Pre-Charge Relay State: Position of the high-voltage bus contactor pre-charge relay.  When this relay is closed, the High Voltage Energy Storage System (or Pack 1 in systems with only one pack) is bringing the high-voltage bus ...";
CM_ SG_ 2364577534 HVESSCenterofPackContactorState "HVESS Center of Pack Contactor State: Position of the center high-voltage contactor.  When this contactor is closed, the positive half of the High Voltage Energy Storage System (or Pack 1 in systems with only one pack) is connected to the negative ha...";
CM_ SG_ 2364577534 HVESSHghVltgBsAtvIsltnTstStts "HVESS High-Voltage Bus Active Isolation Test Status: Status of the high-voltage bus electrical active isolation test as performed by the High Voltage Energy Storage System (or Pack 1 in systems with only one pack).This parameter provides HVES system ...";
CM_ SG_ 2364577534 HVESSHghVltgBsPssvIsltnTstStts "HVESS High-Voltage Bus Passive Isolation Test Status: Status of the high-voltage bus electrical passive isolation test as performed by the High Voltage Energy Storage System (or Pack 1 in systems with only one pack).This parameter provides HVES syste...";
CM_ SG_ 2364577534 HVESSHVILStatus "HVESS HVIL Status: Status of the High Voltage Interlock Loop from the viewpoint of the High Voltage Energy Storage System (or Pack 1 in systems with only one pack).This parameter provides HVES system level information. If there are multiple packs in ...";
CM_ SG_ 2364577534 HVESSInertiaSwitchStatus "HVESS Inertia Switch Status: Switch indicating that an impact has been sensed by the High Voltage Energy Storage System (or Pack 1 in systems with only one pack). The impact indication may require action by another controller, or by this HVES instanc...";
CM_ SG_ 2364577534 HVESSStateofChargeStatus "HVESS State of Charge Status: Status of the High Voltage Energy Storage System (or Pack 1 in systems with only one pack) State of Charge (SOC).  Note:  A given HVES controller may not support all of the states.This parameter provides HVES system leve...";
CM_ SG_ 2364577534 HVESSCellBalanceStatus "HVESS Cell Balance Status: Indicates whether or not the cells in the High Voltage Energy Storage System (or Pack 1 in systems with only one pack) are balanced.This parameter provides HVES system level information. If there are multiple packs in the s...";
CM_ SG_ 2364577534 HVESSCellBalancingActive "HVESS Cell Balancing Active: Indicates whether or not the cells in the High Voltage Energy Storage System (or Pack 1 in systems with only one pack) are currently being balanced.This parameter provides HVES system level information. If there are multi...";
CM_ SG_ 2364577534 HVESSInternalChargerStatus "HVESS Internal Charger Status: Indicates that the charger in this HVES instance is on.  External chargers may use the External Energy Source Connection Status (SPN 7898) and related SPs.This parameter provides HVES system level information. If there ...";
CM_ SG_ 2364577534 HVESSHghVltgBsCnntnStts "HVESS High-Voltage Bus Connection Status: This parameter provides high level feedback on the High Voltage Energy Storage System (or Pack 1 in systems with only one pack) high voltage bus connection.  For specific contactor information, see SPN 8091 (...";
CM_ SG_ 2364577534 HVESSOperationalStatus "HVESS Operational Status: Provides feedback on where the High Voltage Energy Storage System (or Pack 1 in systems with only one pack) is in its operating spectrum, and includes feedback in response to the Operation Consent [i.e. SPN 8412 (HVESS Opera...";
CM_ SG_ 2364577534 HVESSNumberofHVESPsReady "HVESS Number of HVESPs Ready: The number of High Voltage Energy Storage Packs that are currently ready to provide high voltage energy or are actively providing high voltage energy in the HVESS system. This parameter will increment after contactors ar...";
CM_ SG_ 2364577534 HVESSStatus1Counter "HVESS Status 1 Counter: The message counter is used to detect situations where the transmitting ECU malfunction repeats the same frame all the time. The receiver of the information may use the counter parameter to detect this situation. The transmitt...";
CM_ SG_ 2364577534 HVESSStatus1CRC "HVESS Status 1 CRC: The CRC is defined as follows: • Length: 8 bits • Polynomial: x^8+x^5+x^3+x^2+x+1 • Initial Value: FFh • Input Data Reflection: Not reflected • Result Data Reflection: Not reflected • XOR value: FFhSAE makes no claim of the functi...";
CM_ BO_ 2364580094 "High Voltage Energy Storage System Data 7";
CM_ SG_ 2364580094 HVESSDischargeEnergyCapacity "HVESS Discharge Energy Capacity: The amount of stored electrical energy in High Voltage Energy Storage System (or Pack 1 in systems with only one pack) that is available for use by the hybrid system, i.e. “how full is the tank”.  See SPN 8079 (HVESS ...";
CM_ SG_ 2364580094 HVESSChargeEnergyCapacity "HVESS Charge Energy Capacity: The amount of unused electrical energy storage available to be filled by charging High Voltage Energy Storage System (or Pack 1 in systems with only one pack), i.e. “how much empty space is remaining in the tank”.  See S...";
CM_ SG_ 2364580094 HVESSMaximumChargeVoltageLimit "HVESS Maximum Charge Voltage Limit: The maximum voltage level not to be exceeded while charging the High Voltage Energy Storage System (or Pack 1 in systems with only one pack).  If this parameter is not supported, the maximum charge voltage should b...";
CM_ BO_ 2364590334 "DC/AC Accessory Inverter 1 Status 2";
CM_ SG_ 2364590334 DCACAssrInvrtr1DCSdCrrnt "DC/AC Accessory Inverter 1 DC Side Current: DC Side input current measured at the point of control inside the DC/AC Accessory Inverter.";
CM_ SG_ 2364590334 DCACAssrInvrtr1DCSdPwr "DC/AC Accessory Inverter 1 DC Side Power: Power measured at the DC Side input to the DC/AC Accessory Inverter. ";
CM_ SG_ 2364590334 DCACAssrInvrtr1DCSdVltg "DC/AC Accessory Inverter 1 DC Side Voltage: DC Side input voltage measured at the point of control inside the DC/AC Accessory Inverter.";
CM_ SG_ 2364590334 DCACAssIvt1DCSdNtvtCsssGdVt "DC/AC Accessory Inverter 1 DC Side Negative to Chassis Ground Voltage: The voltage level of the high voltage DC side, as measured by the DC/AC between the negative side of the High Voltage DC Side input and the chassis of the DC/AC enclosure.  This v...";
CM_ BO_ 2364590590 "DC/AC Accessory Inverter 1 Voltage";
CM_ SG_ 2364590590 DCACAssrInvrtr1IgntnVltg "DC/AC Accessory Inverter 1 Ignition Voltage: Ignition voltage supplied to the  DC/AC Accessory Inverter controller.";
CM_ SG_ 2364590590 DCACAssrInvrtr1UnswthdSLIVltg "DC/AC Accessory Inverter 1 Unswitched SLI Voltage: Continuously supplied SLI power to this instance of the DC/AC Accessory Inverter controller.";
CM_ BO_ 2364591102 "DC/AC Accessory Inverter 2 Status 2";
CM_ SG_ 2364591102 DCACAssrInvrtr2DCSdCrrnt "DC/AC Accessory Inverter 2 DC Side Current: DC Side input current measured at the point of control inside the DC/AC Accessory Inverter.";
CM_ SG_ 2364591102 DCACAssrInvrtr2DCSdPwr "DC/AC Accessory Inverter 2 DC Side Power: Power measured at the DC Side input to the DC/AC Accessory Inverter. ";
CM_ SG_ 2364591102 DCACAssrInvrtr2DCSdVltg "DC/AC Accessory Inverter 2 DC Side Voltage: DC Side input voltage measured at the point of control inside the DC/AC Accessory Inverter.";
CM_ SG_ 2364591102 DCACAssIvt2DCSdNtvtCsssGdVt "DC/AC Accessory Inverter 2 DC Side Negative to Chassis Ground Voltage: The voltage level of the high voltage DC side, as measured by the DC/AC between the negative side of the High Voltage DC Side input and the chassis of the DC/AC enclosure.  This v...";
CM_ BO_ 2364591358 "DC/AC Accessory Inverter 2 Voltage";
CM_ SG_ 2364591358 DCACAssrInvrtr2IgntnVltg "DC/AC Accessory Inverter 2 Ignition Voltage: Ignition voltage supplied to the  DC/AC Accessory Inverter controller.";
CM_ SG_ 2364591358 DCACAssrInvrtr2UnswthdSLIVltg "DC/AC Accessory Inverter 2 Unswitched SLI Voltage: Continuously supplied SLI power to this instance of the DC/AC Accessory Inverter controller.";
CM_ BO_ 2364592382 "Engine Cylinder Combustion Request";
CM_ SG_ 2364592382 EngnClndr10ExldfrmCmstnRqst "Engine Cylinder 10 Exclude from Combustion Request: Request to the engine ECU to exclude (skip or cut-out) cylinder 10 from combustion.00b = Exclude from Combustion01b = Include for Combustion10b = Reserved11b = Not available/Do not care";
CM_ SG_ 2364592382 EngnClndr11ExldfrmCmstnRqst "Engine Cylinder 11 Exclude from Combustion Request: Request to the engine ECU to exclude (skip or cut-out) cylinder 11 from combustion.00b = Exclude from Combustion01b = Include for Combustion10b = Reserved11b = Not available/Do not care";
CM_ SG_ 2364592382 EngnClndr12ExldfrmCmstnRqst "Engine Cylinder 12 Exclude from Combustion Request: Request to the engine ECU to exclude (skip or cut-out) cylinder 12 from combustion.00b = Exclude from Combustion01b = Include for Combustion10b = Reserved11b = Not available/Do not care";
CM_ SG_ 2364592382 EngnClndr13ExldfrmCmstnRqst "Engine Cylinder 13 Exclude from Combustion Request: Request to the engine ECU to exclude (skip or cut-out) cylinder 13 from combustion.00b = Exclude from Combustion01b = Include for Combustion10b = Reserved11b = Not available/Do not care";
CM_ SG_ 2364592382 EngnClndr14ExldfrmCmstnRqst "Engine Cylinder 14 Exclude from Combustion Request: Request to the engine ECU to exclude (skip or cut-out) cylinder 14 from combustion.00b = Exclude from Combustion01b = Include for Combustion10b = Reserved11b = Not available/Do not care";
CM_ SG_ 2364592382 EngnClndr15ExldfrmCmstnRqst "Engine Cylinder 15 Exclude from Combustion Request: Request to the engine ECU to exclude (skip or cut-out) cylinder 15 from combustion.00b = Exclude from Combustion01b = Include for Combustion10b = Reserved11b = Not available/Do not care";
CM_ SG_ 2364592382 EngnClndr16ExldfrmCmstnRqst "Engine Cylinder 16 Exclude from Combustion Request: Request to the engine ECU to exclude (skip or cut-out) cylinder 16 from combustion.00b = Exclude from Combustion01b = Include for Combustion10b = Reserved11b = Not available/Do not care";
CM_ SG_ 2364592382 EngnClndr17ExldfrmCmstnRqst "Engine Cylinder 17 Exclude from Combustion Request: Request to the engine ECU to exclude (skip or cut-out) cylinder 17 from combustion.00b = Exclude from Combustion01b = Include for Combustion10b = Reserved11b = Not available/Do not care";
CM_ SG_ 2364592382 EngnClndr18ExldfrmCmstnRqst "Engine Cylinder 18 Exclude from Combustion Request: Request to the engine ECU to exclude (skip or cut-out) cylinder 18 from combustion.00b = Exclude from Combustion01b = Include for Combustion10b = Reserved11b = Not available/Do not care";
CM_ SG_ 2364592382 EngnClndr19ExldfrmCmstnRqst "Engine Cylinder 19 Exclude from Combustion Request: Request to the engine ECU to exclude (skip or cut-out) cylinder 19 from combustion.00b = Exclude from Combustion01b = Include for Combustion10b = Reserved11b = Not available/Do not care";
CM_ SG_ 2364592382 EngnClndr1ExldfrmCmstnRqst "Engine Cylinder 1 Exclude from Combustion Request: Request to the engine ECU to exclude (skip or cut-out) cylinder 1 from combustion.00b = Exclude from Combustion01b = Include for Combustion10b = Reserved11b = Not available/Do not care";
CM_ SG_ 2364592382 EngnClndr20ExldfrmCmstnRqst "Engine Cylinder 20 Exclude from Combustion Request: Request to the engine ECU to exclude (skip or cut-out) cylinder 20 from combustion.00b = Exclude from Combustion01b = Include for Combustion10b = Reserved11b = Not available/Do not care";
CM_ SG_ 2364592382 EngnClndr21ExldfrmCmstnRqst "Engine Cylinder 21 Exclude from Combustion Request: Request to the engine ECU to exclude (skip or cut-out) cylinder 21 from combustion.00b = Exclude from Combustion01b = Include for Combustion10b = Reserved11b = Not available/Do not care";
CM_ SG_ 2364592382 EngnClndr22ExldfrmCmstnRqst "Engine Cylinder 22 Exclude from Combustion Request: Request to the engine ECU to exclude (skip or cut-out) cylinder 22 from combustion.00b = Exclude from Combustion01b = Include for Combustion10b = Reserved11b = Not available/Do not care";
CM_ SG_ 2364592382 EngnClndr23ExldfrmCmstnRqst "Engine Cylinder 23 Exclude from Combustion Request: Request to the engine ECU to exclude (skip or cut-out) cylinder 23 from combustion.00b = Exclude from Combustion01b = Include for Combustion10b = Reserved11b = Not available/Do not care";
CM_ SG_ 2364592382 EngnClndr24ExldfrmCmstnRqst "Engine Cylinder 24 Exclude from Combustion Request: Request to the engine ECU to exclude (skip or cut-out) cylinder 24 from combustion.00b = Exclude from Combustion01b = Include for Combustion10b = Reserved11b = Not available/Do not care";
CM_ SG_ 2364592382 EngnClndr2ExldfrmCmstnRqst "Engine Cylinder 2 Exclude from Combustion Request: Request to the engine ECU to exclude (skip or cut-out) cylinder 2 from combustion.00b = Exclude from Combustion01b = Include for Combustion10b = Reserved11b = Not available/Do not care";
CM_ SG_ 2364592382 EngnClndr3ExldfrmCmstnRqst "Engine Cylinder 3 Exclude from Combustion Request: Request to the engine ECU to exclude (skip or cut-out) cylinder 3 from combustion.00b = Exclude from Combustion01b = Include for Combustion10b = Reserved11b = Not available/Do not care";
CM_ SG_ 2364592382 EngnClndr4ExldfrmCmstnRqst "Engine Cylinder 4 Exclude from Combustion Request: Request to the engine ECU to exclude (skip or cut-out) cylinder 4 from combustion.00b = Exclude from Combustion01b = Include for Combustion10b = Reserved11b = Not available/Do not care";
CM_ SG_ 2364592382 EngnClndr5ExldfrmCmstnRqst "Engine Cylinder 5 Exclude from Combustion Request: Request to the engine ECU to exclude (skip or cut-out) cylinder 5 from combustion.00b = Exclude from Combustion01b = Include for Combustion10b = Reserved11b = Not available/Do not care";
CM_ SG_ 2364592382 EngnClndr6ExldfrmCmstnRqst "Engine Cylinder 6 Exclude from Combustion Request: Request to the engine ECU to exclude (skip or cut-out) cylinder 6 from combustion.00b = Exclude from Combustion01b = Include for Combustion10b = Reserved11b = Not available/Do not care";
CM_ SG_ 2364592382 EngnClndr7ExldfrmCmstnRqst "Engine Cylinder 7 Exclude from Combustion Request: Request to the engine ECU to exclude (skip or cut-out) cylinder 7 from combustion.00b = Exclude from Combustion01b = Include for Combustion10b = Reserved11b = Not available/Do not care";
CM_ SG_ 2364592382 EngnClndr8ExldfrmCmstnRqst "Engine Cylinder 8 Exclude from Combustion Request: Request to the engine ECU to exclude (skip or cut-out) cylinder 8 from combustion.00b = Exclude from Combustion01b = Include for Combustion10b = Reserved11b = Not available/Do not care";
CM_ SG_ 2364592382 EngnClndr9ExldfrmCmstnRqst "Engine Cylinder 9 Exclude from Combustion Request: Request to the engine ECU to exclude (skip or cut-out) cylinder 9 from combustion.00b = Exclude from Combustion01b = Include for Combustion10b = Reserved11b = Not available/Do not care";
CM_ SG_ 2364592382 NmrfEngnClndrstExldfrmCmstn "Number of Engine Cylinders to Exclude from Combustion: Request to the engine ECU for the number of cylinders to exclude from combustion (cut-out or skip) for a given instance in time.  The engine ECU can decide on the cylinders to exclude from combus...";
CM_ BO_ 2364592638 "Engine Cylinder Head Bypass Actuator 1";
CM_ SG_ 2364592638 EngnClndrHdBpssAttr1DsrdPstn "Engine Cylinder Head Bypass Actuator 1 Desired Position: Requested position of Engine Cylinder Head Bypass actuator by engine ECM, where 0% represents bypass fully closed and 100% represents fully open. This is the position that the device is attempt...";
CM_ SG_ 2364592638 EngnClndrHdBpssAttr1OprtnStts "Engine Cylinder Head Bypass Actuator 1 Operation Status: Identifies the status of Engine Cylinder Head Bypass Actuator 1.Cylinder head bypass valve is used to release the air at the high pressure compressor outlet into turbocharger turbine inlet when...";
CM_ SG_ 2364592638 EngnClndrHdBpssAttr1PrlmnrFMI "Engine Cylinder Head Bypass Actuator 1 Preliminary FMI: Used to identify the applicable J1939-73 FMI detected in Engine Cylinder Head Bypass Actuator 1 by the manufacturer's software. When there are multiple failures, the most severe is transmitted.A...";
CM_ SG_ 2364592638 EngnClndrHdBpssAttr1Pstn "Engine Cylinder Head Bypass Actuator 1 Position: Actual position of Engine Cylinder Head Bypass actuator, where 0% represents fully closed and 100% represents fully open.Cylinder Head bypass valve is used to release the air at the high pressure compr...";
CM_ SG_ 2364592638 EngnClndrHdBpssAttr1Tmprtr "Engine Cylinder Head Bypass Actuator 1 Temperature: Temperature of the Engine Cylinder Head Bypass Actuator 1 drive circuitry. Temperature excursions may affect the torque output.Cylinder Head bypass valve is used to release the air at the high press...";
CM_ SG_ 2364592638 EngnClndrHdBpssAttr1TmprtrStts "Engine Cylinder Head Bypass Actuator 1 Temperature Status: Identifies the status of the Engine Cylinder Head Bypass Blowoff Actuator 1 drive circuitry temperature. Temperature excursions may affect the torque output.Cylinder Head bypass valve is used...";
CM_ BO_ 2364592894 "Engine Electronic Controller 18";
CM_ SG_ 2364592894 EngineIntakeAirSourceValve "Engine Intake Air Source Valve: Status of the actuator/valve in the airbox used to source engine intake air from either the engine compartment or external to the vehicle.00b = Off01b = On10b = Error11b = Not available";
CM_ SG_ 2364592894 EngnClndrHdBpssAttr1Cmmnd "Engine Cylinder Head Bypass Actuator 1 Command: Command to cylinder head bypass actuator 1, normalized to percent, where 0% nominally represents fully closed (No Flow) and 100% represents fully open (Max Flow). The purpose of the cylinder bypass valv...";
CM_ SG_ 2364592894 EngnExhstGsRstrtnVlvPstn "Engine Exhaust Gas Restriction Valve Position: The position of the exhaust gas restriction valve expressed as a percentage of full travel. 0% means the valve is closed and no exhaust gas is flowing into the intake air stream. 100% means the valve is ...";
CM_ BO_ 2364593150 "Predictive Cruise Control 1";
CM_ SG_ 2364593150 PrdtvCrsCntrlDrvlnDsnggInhtRqst "Predictive Cruise Control Driveline Disengage Inhibit Request: Request to temporarily inhibit a fuel saving feature that would normally open the driveline. Under certain conditions and with knowledge of the terrain, inhibiting this feature may improv...";
CM_ SG_ 2364593150 PrdtvCrsCntrlEvntnRng "Predictive Cruise Control Event in Range: Indicates that an event, such as a grade, is detected within the range of the predictive cruise control (PCC) look-ahead distance.00b = No PCC event in range01b = PCC event in range10b = Error11b = Not availa...";
CM_ SG_ 2364593150 PrdtvCrsCntrlSpdEvntIndtr "Predictive Cruise Control Speed Event Indicator: Indicates to the operator that a predictive cruise control (PCC) speed event is active. Typically, this will correspond to a Predictive Cruise Control Set Speed Offset (SPN 7316) request to increase or...";
CM_ SG_ 2364593150 PrdtvCrsCntrlStSpdOffst "Predictive Cruise Control Set Speed Offset: The amount by which the actual set point used by the cruise control algorithm should be changed as determined by external factors (e.g., anticipated road grade).If SPN 7317 indicates Enabled (0001b) and if ...";
CM_ SG_ 2364593150 PredictiveCruiseControlState "Predictive Cruise Control State: Indicates the state of the PCC controller.If this parameter is 0001b, the cruise control set point may be modified by the Predictive Cruise Control Set Speed Offset (SPN 7316) . For states other than 0001, the value i...";
CM_ SG_ 2364593150 RoadwayNextGrade "Roadway Next Grade: Road grade at an upcoming distance.  If SPN 9199 is supported, then this the road grade at the distance specified by SPN 9199. Positive numbers indicate uphill grade, negative are downhill for vehicle direction of travel.   For gr...";
CM_ SG_ 2364593150 RoadwayNextGradeDistance "Roadway Next Grade Distance: The distance from the current vehicle position to the grade indicated in SPN 7433.";
CM_ SG_ 2364593150 RoadwayPresentGrade "Roadway Present Grade: Road grade at present vehicle position. Positive numbers indicate uphill grade, negative are downhill for present vehicle direction of travel. For grades beyond the limits of the parameter, the limit value shall be reported.Par...";
CM_ SG_ 2364593150 VhlSpdCntrlOvrrdEvntIndtr "Vehicle Speed Control Override Event Indicator: Indicates to the operator that a Speed Control override event is active.  Speed Control refers to retarders or methods of automatically limiting vehicle speed, for instance on downhill grades.  An activ...";
CM_ SG_ 2364593150 VhlSpdCntrlOvrrdRqst "Vehicle Speed Control Override Request: Speed control override requested. Indicates that the minimum restriction of speed is desired, for instance when travelling downhill towards an impending uphill grade. This is not a request to inhibit engine bra...";
CM_ BO_ 2364597758 "Engine Ignition Timing Offset 1";
CM_ SG_ 2364597758 EngnClndr1IgntnTmngOffst "Engine Cylinder 1 Ignition Timing Offset: The ignition timing offset for Cylinder 1 from the engine timing advance (SPN 7355) as a command to the ignition control module. Positive values command an increasingly advanced timing.";
CM_ SG_ 2364597758 EngnClndr2IgntnTmngOffst "Engine Cylinder 2 Ignition Timing Offset: The ignition timing offset for Cylinder 2 from the engine timing advance (SPN 7355) as a command to the ignition control module. Positive values command an increasingly advanced timing.";
CM_ SG_ 2364597758 EngnClndr3IgntnTmngOffst "Engine Cylinder 3 Ignition Timing Offset: The ignition timing offset for Cylinder 3 from the engine timing advance (SPN 7355) as a command to the ignition control module. Positive values command an increasingly advanced timing.";
CM_ SG_ 2364597758 EngnClndr4IgntnTmngOffst "Engine Cylinder 4 Ignition Timing Offset: The ignition timing offset for Cylinder 4 from the engine timing advance (SPN 7355) as a command to the ignition control module. Positive values command an increasingly advanced timing.";
CM_ SG_ 2364597758 EngnClndr5IgntnTmngOffst "Engine Cylinder 5 Ignition Timing Offset: The ignition timing offset for Cylinder 5 from the engine timing advance (SPN 7355) as a command to the ignition control module. Positive values command an increasingly advanced timing.";
CM_ SG_ 2364597758 EngnClndr6IgntnTmngOffst "Engine Cylinder 6 Ignition Timing Offset: The ignition timing offset for Cylinder 6 from the engine timing advance (SPN 7355) as a command to the ignition control module. Positive values command an increasingly advanced timing.";
CM_ SG_ 2364597758 EngnClndr7IgntnTmngOffst "Engine Cylinder 7 Ignition Timing Offset: The ignition timing offset for Cylinder 7 from the engine timing advance (SPN 7355) as a command to the ignition control module. Positive values command an increasingly advanced timing.";
CM_ SG_ 2364597758 EngnClndr8IgntnTmngOffst "Engine Cylinder 8 Ignition Timing Offset: The ignition timing offset for Cylinder 8 from the engine timing advance (SPN 7355) as a command to the ignition control module. Positive values command an increasingly advanced timing.";
CM_ BO_ 2364598014 "Engine Ignition Timing Offset 2";
CM_ SG_ 2364598014 EngnClndr10IgntnTmngOffst "Engine Cylinder 10 Ignition Timing Offset: The ignition timing offset for Cylinder 10 from the engine timing advance (SPN 7355) as a command to the ignition control module. Positive values command an increasingly advanced timing.";
CM_ SG_ 2364598014 EngnClndr11IgntnTmngOffst "Engine Cylinder 11 Ignition Timing Offset: The ignition timing offset for Cylinder 11 from the engine timing advance (SPN 7355) as a command to the ignition control module. Positive values command an increasingly advanced timing.";
CM_ SG_ 2364598014 EngnClndr12IgntnTmngOffst "Engine Cylinder 12 Ignition Timing Offset: The ignition timing offset for Cylinder 12 from the engine timing advance (SPN 7355) as a command to the ignition control module. Positive values command an increasingly advanced timing.";
CM_ SG_ 2364598014 EngnClndr13IgntnTmngOffst "Engine Cylinder 13 Ignition Timing Offset: The ignition timing offset for Cylinder 13 from the engine timing advance (SPN 7355) as a command to the ignition control module. Positive values command an increasingly advanced timing.";
CM_ SG_ 2364598014 EngnClndr14IgntnTmngOffst "Engine Cylinder 14 Ignition Timing Offset: The ignition timing offset for Cylinder 14 from the engine timing advance (SPN 7355) as a command to the ignition control module. Positive values command an increasingly advanced timing.";
CM_ SG_ 2364598014 EngnClndr15IgntnTmngOffst "Engine Cylinder 15 Ignition Timing Offset: The ignition timing offset for Cylinder 15 from the engine timing advance (SPN 7355) as a command to the ignition control module. Positive values command an increasingly advanced timing.";
CM_ SG_ 2364598014 EngnClndr16IgntnTmngOffst "Engine Cylinder 16 Ignition Timing Offset: The ignition timing offset for Cylinder 16 from the engine timing advance (SPN 7355) as a command to the ignition control module. Positive values command an increasingly advanced timing.";
CM_ SG_ 2364598014 EngnClndr9IgntnTmngOffst "Engine Cylinder 9 Ignition Timing Offset: The ignition timing offset for Cylinder 9 from the engine timing advance (SPN 7355) as a command to the ignition control module. Positive values command an increasingly advanced timing.";
CM_ BO_ 2364598270 "Engine Ignition Timing Offset 3";
CM_ SG_ 2364598270 EngnClndr17IgntnTmngOffst "Engine Cylinder 17 Ignition Timing Offset: The ignition timing offset for Cylinder 17 from the engine timing advance (SPN 7355) as a command to the ignition control module. Positive values command an increasingly advanced timing.";
CM_ SG_ 2364598270 EngnClndr18IgntnTmngOffst "Engine Cylinder 18 Ignition Timing Offset: The ignition timing offset for Cylinder 18 from the engine timing advance (SPN 7355) as a command to the ignition control module. Positive values command an increasingly advanced timing.";
CM_ SG_ 2364598270 EngnClndr19IgntnTmngOffst "Engine Cylinder 19 Ignition Timing Offset: The ignition timing offset for Cylinder 19 from the engine timing advance (SPN 7355) as a command to the ignition control module. Positive values command an increasingly advanced timing.";
CM_ SG_ 2364598270 EngnClndr20IgntnTmngOffst "Engine Cylinder 20 Ignition Timing Offset: The ignition timing offset for Cylinder 20 from the engine timing advance (SPN 7355) as a command to the ignition control module. Positive values command an increasingly advanced timing.";
CM_ SG_ 2364598270 EngnClndr21IgntnTmngOffst "Engine Cylinder 21 Ignition Timing Offset: The ignition timing offset for Cylinder 21 from the engine timing advance (SPN 7355) as a command to the ignition control module. Positive values command an increasingly advanced timing.";
CM_ SG_ 2364598270 EngnClndr22IgntnTmngOffst "Engine Cylinder 22 Ignition Timing Offset: The ignition timing offset for Cylinder 22 from the engine timing advance (SPN 7355) as a command to the ignition control module. Positive values command an increasingly advanced timing.";
CM_ SG_ 2364598270 EngnClndr23IgntnTmngOffst "Engine Cylinder 23 Ignition Timing Offset: The ignition timing offset for Cylinder 23 from the engine timing advance (SPN 7355) as a command to the ignition control module. Positive values command an increasingly advanced timing.";
CM_ SG_ 2364598270 EngnClndr24IgntnTmngOffst "Engine Cylinder 24 Ignition Timing Offset: The ignition timing offset for Cylinder 24 from the engine timing advance (SPN 7355) as a command to the ignition control module. Positive values command an increasingly advanced timing.";
CM_ BO_ 2364598526 "Engine Throttle / Fuel Actuator Control Command 2";
CM_ SG_ 2364598526 EngnFlAttr3CntrlCmmnd "Engine Fuel Actuator 3 Control Command: The control command to fuel actuator 3, normalized to percent, where 0% represents fully closed and 100% represents fully open.  Typically, this fuel actuator is used to regulate low pressure natural gas flow r...";
CM_ SG_ 2364598526 EngnFlAttr4CntrlCmmnd "Engine Fuel Actuator 4 Control Command: The control command to fuel actuator 4, normalized to percent, where 0% represents fully closed and 100% represents fully open.  Typically, this fuel actuator is used to regulate low pressure natural gas flow r...";
CM_ BO_ 2364602878 "Engine Valve Controller";
CM_ SG_ 2364602878 EngnVlvCntrlMdl1PrlmnrFMI "Engine Valve Control Module 1 Preliminary FMI: Used to identify the applicable J1939-73 FMI detected in Engine Valve Control Module 1 by the manufacturer's software.  When there are multiple failures, the most severe is transmitted.A value of 31 is s...";
CM_ SG_ 2364602878 EngnVlvCntrlMdl2PrlmnrFMI "Engine Valve Control Module 2 Preliminary FMI: Used to identify the applicable J1939-73 FMI detected in Engine Valve Control Module 2 by the manufacturer's software.  When there are multiple failures, the most severe is transmitted.A value of 31 is s...";
CM_ SG_ 2364602878 EngnVlvCntrlMdl3PrlmnrFMI "Engine Valve Control Module 3 Preliminary FMI: Used to identify the applicable J1939-73 FMI detected in Engine Valve Control Module 3 by the manufacturer's software.  When there are multiple failures, the most severe is transmitted.A value of 31 is s...";
CM_ SG_ 2364602878 EngnVlvCntrlMdl4PrlmnrFMI "Engine Valve Control Module 4 Preliminary FMI: Used to identify the applicable J1939-73 FMI detected in Engine Valve Control Module 4 by the manufacturer's software.  When there are multiple failures, the most severe is transmitted.A value of 31 is s...";
CM_ SG_ 2364602878 EngnVlvCntrlMdl5PrlmnrFMI "Engine Valve Control Module 5 Preliminary FMI: Used to identify the applicable J1939-73 FMI detected in Engine Valve Control Module 5 by the manufacturer's software.  When there are multiple failures, the most severe is transmitted.A value of 31 is s...";
CM_ SG_ 2364602878 EngnVlvCntrlMdl6PrlmnrFMI "Engine Valve Control Module 6 Preliminary FMI: Used to identify the applicable J1939-73 FMI detected in Engine Valve Control Module 6 by the manufacturer's software.  When there are multiple failures, the most severe is transmitted.A value of 31 is s...";
CM_ SG_ 2364602878 EngnVlvCntrlMdl7PrlmnrFMI "Engine Valve Control Module 7 Preliminary FMI: Used to identify the applicable J1939-73 FMI detected in Engine Valve Control Module 7 by the manufacturer's software. When there are multiple failures, the most severe is transmitted.A value of 31 is se...";
CM_ SG_ 2364602878 EngnVlvCntrlMdl8PrlmnrFMI "Engine Valve Control Module 8 Preliminary FMI: Used to identify the applicable J1939-73 FMI detected in Engine Valve Control Module 8 by the manufacturer's software.  When there are multiple failures, the most severe is transmitted.A value of 31 is s...";
CM_ BO_ 2364603134 "Electronic Transmission Controller 13";
CM_ SG_ 2364603134 MxmmFrwrdTrnsmssnOtptShftSpd "Maximum Forward Transmission Output Shaft Speed: Maximum transmission output shaft speed that can be achieved in the forward direction, based on current operating conditions.";
CM_ SG_ 2364603134 MxmmRvrsTrnsmssnOtptShftSpd "Maximum Reverse Transmission Output Shaft Speed: Maximum transmission output shaft speed that can be achieved in the reverse direction, based on current operating conditions.";
CM_ SG_ 2364603134 SAddssAtvPdTsssRqstdG "Source Address of Active or Pending Transmission Requested Gear: This parameter indicates the source address of the device whose SPN 525 [Transmission Requested Gear] request is currently being acted upon by the transmission. If transmission response...";
CM_ SG_ 2364603134 TransmissionMode11Indicator "Transmission Mode 11 Indicator: This state signal is the transmission's indication that it is operating under transmission mode 11 (SPN 12949) as commanded via the TC2 message (PGN 3328).  The definition of the transmission mode is left to the discre...";
CM_ SG_ 2364603134 TransmissionMode12Indicator "Transmission Mode 12 Indicator: This state signal is the transmission's indication that it is operating under transmission mode 12 (SPN 12950) as commanded via the TC2 message (PGN 3328).  The definition of the transmission mode is left to the discre...";
CM_ SG_ 2364603134 TransmissionMode13Indicator "Transmission Mode 13 Indicator: This state signal is the transmission's indication that it is operating under transmission mode 13 (SPN 12951) as commanded via the TC2 message (PGN 3328).  The definition of the transmission mode is left to the discre...";
CM_ SG_ 2364603134 TransmissionMode14Indicator "Transmission Mode 14 Indicator: This state signal is the transmission's indication that it is operating under transmission mode 14 (SPN 12952) as commanded via the TC2 message (PGN 3328).  The definition of the transmission mode is left to the discre...";
CM_ SG_ 2364603134 TransmissionMode15Indicator "Transmission Mode 15 Indicator: This state signal is the transmission's indication that it is operating under transmission mode 15 (SPN 12953) as commanded via the TC2 message (PGN 3328).  The definition of the transmission mode is left to the discre...";
CM_ SG_ 2364603134 TransmissionMode16Indicator "Transmission Mode 16 Indicator: This state signal is the transmission's indication that it is operating under transmission mode 16 (SPN 12954) as commanded via the TC2 message (PGN 3328).  The definition of the transmission mode is left to the discre...";
CM_ SG_ 2364603134 TransmissionMode17Indicator "Transmission Mode 17 Indicator: This state signal is the transmission's indication that it is operating under transmission mode 17 (SPN 12955) as commanded via the TC2 message (PGN 3328).  The definition of the transmission mode is left to the discre...";
CM_ SG_ 2364603134 TransmissionMode18Indicator "Transmission Mode 18 Indicator: This state signal is the transmission's indication that it is operating under transmission mode 18 (SPN 12956) as commanded via the TC2 message (PGN 3328).  The definition of the transmission mode is left to the discre...";
CM_ SG_ 2364603134 TransmissionMode19Indicator "Transmission Mode 19 Indicator: This state signal is the transmission's indication that it is operating under transmission mode 19 (SPN 12957) as commanded via the TC2 message (PGN 3328).  The definition of the transmission mode is left to the discre...";
CM_ SG_ 2364603134 TransmissionMode20Indicator "Transmission Mode 20 Indicator: This state signal is the transmission's indication that it is operating under transmission mode 20 (SPN 12958) as commanded via the TC2 message (PGN 3328).  The definition of the transmission mode is left to the discre...";
CM_ BO_ 2364603390 "Aftertreatment 1 SCR Dosing System Requests 3";
CM_ SG_ 2364603390 Atttt1DsExstFdDsVv1Cd "Aftertreatment 1 Diesel Exhaust Fluid Doser Valve 1 Command: Command (in percent) sent to the diesel exhaust fluid (DEF) injector to control the amount of DEF being injected into the aftreatment exhaust stream.0% closes the valve; 100% fully opens th...";
CM_ SG_ 2364603390 Atttt1DsExstFdRqstdQttIttHRst "Aftertreatment 1 Diesel Exhaust Fluid Requested Quantity of Integrator (High Resolution): Represents the command for the diesel exhaust fluid quantity integrator in the dosing control unit. See SPN 4350 for alternate resolution.";
CM_ BO_ 2364603646 "Aftertreatment 2 SCR Dosing System Requests 3";
CM_ SG_ 2364603646 Atttt2DsExstFdRqstdQttIttHRst "Aftertreatment 2 Diesel Exhaust Fluid Requested Quantity of Integrator (High Resolution): Represents the command for the diesel exhaust fluid quantity integrator in the dosing control unit. See SPN 4403 for alternate resolution.";
CM_ BO_ 2364603902 "Aftertreatment 1 SCR Dosing System Information 4";
CM_ SG_ 2364603902 Atttt1DsExstFdAtQttIttHRst "Aftertreatment 1 Diesel Exhaust Fluid Actual Quantity of Integrator (High Resolution): The SCR requested diesel exhaust fluid integrator total quantity for aftertreatment system 1 (exhaust bank 1).  See SPN 4333 for alternate resolution.";
CM_ BO_ 2364604158 "Aftertreatment 2 SCR Dosing System Information 4";
CM_ SG_ 2364604158 Atttt2DsExstFdAtQttIttHRst "Aftertreatment 2 Diesel Exhaust Fluid Actual Quantity of Integrator (High Resolution): The SCR requested diesel exhaust fluid integrator total quantity for aftertreatment system 2 (exhaust bank 2).  See SPN 4386 for alternate resolution.";
CM_ BO_ 2364605438 "Generator Trip Energy";
CM_ SG_ 2364605438 GeneratorTripkVArHoursExport "Generator Trip kVAr Hours Export: The trip AC reactive energy exported by the generstor since the last reset of the trip kVArh meter.This value will be reset by the user at will.";
CM_ SG_ 2364605438 GeneratorTripkWHoursExport "Generator Trip kW Hours Export: The total kilowatt-hours that have been exported by the generator since the last reset of the trip kWh meter.This value will be reset by the user at will.";
CM_ BO_ 2364605950 "Hydraulic Pressure Displacement";
CM_ SG_ 2364605950 HydraulicLinePressure "Hydraulic Line Pressure: The pressure of the hydraulic fluid, measured in the hydraulic line.";
CM_ SG_ 2364605950 MechanicalMovementAngle "Mechanical Movement Angle: The angle of rotation of the mechanical component.The increase and decrease of the value (i.e. rotation about the X-axis) is in accordance to the right-hand rule, as specified in SAE J670, with the positive X axis directed ...";
CM_ BO_ 2364606718 "High Voltage Energy Storage System Module Status 1";
CM_ SG_ 2364606718 HVESSModule1OperationalStatus "HVESS Module 1 Operational Status: Operational Status of Module 1 in the High Voltage Energy Storage System (or Pack 1 in systems with only one pack).  Not Operational is used when the module is initializing or not able to function (e.g. internal mod...";
CM_ SG_ 2364606718 HVESSModule2OperationalStatus "HVESS Module 2 Operational Status: Operational Status of Module 2 in the High Voltage Energy Storage System (or Pack 1 in systems with only one pack).  Not Operational is used when the module is initializing or not able to function (e.g. internal mod...";
CM_ SG_ 2364606718 HVESSModule3OperationalStatus "HVESS Module 3 Operational Status: Operational Status of Module 3 in the High Voltage Energy Storage System (or Pack 1 in systems with only one pack).  Not Operational is used when the module is initializing or not able to function (e.g. internal mod...";
CM_ SG_ 2364606718 HVESSModule4OperationalStatus "HVESS Module 4 Operational Status: Operational Status of Module 4 in the High Voltage Energy Storage System (or Pack 1 in systems with only one pack).  Not Operational is used when the module is initializing or not able to function (e.g. internal mod...";
CM_ SG_ 2364606718 HVESSModule5OperationalStatus "HVESS Module 5 Operational Status: Operational Status of Module 5 in the High Voltage Energy Storage System (or Pack 1 in systems with only one pack).  Not Operational is used when the module is initializing or not able to function (e.g. internal mod...";
CM_ SG_ 2364606718 HVESSModule6OperationalStatus "HVESS Module 6 Operational Status: Operational Status of Module 6 in the High Voltage Energy Storage System (or Pack 1 in systems with only one pack).  Not Operational is used when the module is initializing or not able to function (e.g. internal mod...";
CM_ SG_ 2364606718 HVESSModule7OperationalStatus "HVESS Module 7 Operational Status: Operational Status of Module 7 in the High Voltage Energy Storage System (or Pack 1 in systems with only one pack).  Not Operational is used when the module is initializing or not able to function (e.g. internal mod...";
CM_ SG_ 2364606718 HVESSModule8OperationalStatus "HVESS Module 8 Operational Status: Operational Status of Module 8 in the High Voltage Energy Storage System (or Pack 1 in systems with only one pack).  Not Operational is used when the module is initializing or not able to function (e.g. internal mod...";
CM_ SG_ 2364606718 HVESSModule9OperationalStatus "HVESS Module 9 Operational Status: Operational Status of Module 9 in the High Voltage Energy Storage System (or Pack 1 in systems with only one pack).  Not Operational is used when the module is initializing or not able to function (e.g. internal mod...";
CM_ SG_ 2364606718 HVESSModule10OperationalStatus "HVESS Module 10 Operational Status: Operational Status of Module 10 in the High Voltage Energy Storage System (or Pack 1 in systems with only one pack).  Not Operational is used when the module is initializing or not able to function (e.g. internal m...";
CM_ SG_ 2364606718 HVESSModule11OperationalStatus "HVESS Module 11 Operational Status: Operational Status of Module 11 in the High Voltage Energy Storage System (or Pack 1 in systems with only one pack).  Not Operational is used when the module is initializing or not able to function (e.g. internal m...";
CM_ SG_ 2364606718 HVESSModule12OperationalStatus "HVESS Module 12 Operational Status: Operational Status of Module 12 in the High Voltage Energy Storage System (or Pack 1 in systems with only one pack).  Not Operational is used when the module is initializing or not able to function (e.g. internal m...";
CM_ SG_ 2364606718 HVESSModule13OperationalStatus "HVESS Module 13 Operational Status: Operational Status of Module 13 in the High Voltage Energy Storage System (or Pack 1 in systems with only one pack).  Not Operational is used when the module is initializing or not able to function (e.g. internal m...";
CM_ SG_ 2364606718 HVESSModule14OperationalStatus "HVESS Module 14 Operational Status: Operational Status of Module 14 in the High Voltage Energy Storage System (or Pack 1 in systems with only one pack).  Not Operational is used when the module is initializing or not able to function (e.g. internal m...";
CM_ SG_ 2364606718 HVESSModule15OperationalStatus "HVESS Module 15 Operational Status: Operational Status of Module 15 in the High Voltage Energy Storage System (or Pack 1 in systems with only one pack).  Not Operational is used when the module is initializing or not able to function (e.g. internal m...";
CM_ SG_ 2364606718 HVESSModule16OperationalStatus "HVESS Module 16 Operational Status: Operational Status of Module 16 in the High Voltage Energy Storage System (or Pack 1 in systems with only one pack).  Not Operational is used when the module is initializing or not able to function (e.g. internal m...";
CM_ SG_ 2364606718 HVESSModule17OperationalStatus "HVESS Module 17 Operational Status: Operational Status of Module 17 in the High Voltage Energy Storage System (or Pack 1 in systems with only one pack).  Not Operational is used when the module is initializing or not able to function (e.g. internal m...";
CM_ SG_ 2364606718 HVESSModule18OperationalStatus "HVESS Module 18 Operational Status: Operational Status of Module 18 in this High Voltage Energy Storage System (or Pack 1 in systems with only one pack).  Not Operational is used when the module is initializing or not able to function (e.g. internal ...";
CM_ SG_ 2364606718 HVESSModule19OperationalStatus "HVESS Module 19 Operational Status: Operational Status of Module 19 in this High Voltage Energy Storage System (or Pack 1 in systems with only one pack).  Not Operational is used when the module is initializing or not able to function (e.g. internal ...";
CM_ SG_ 2364606718 HVESSModule20OperationalStatus "HVESS Module 20 Operational Status: Operational Status of Module 20 in this High Voltage Energy Storage System (or Pack 1 in systems with only one pack).  Not Operational is used when the module is initializing or not able to function (e.g. internal ...";
CM_ SG_ 2364606718 HVESSModule21OperationalStatus "HVESS Module 21 Operational Status: Operational Status of Module 21 in this High Voltage Energy Storage System (or Pack 1 in systems with only one pack).  Not Operational is used when the module is initializing or not able to function (e.g. internal ...";
CM_ SG_ 2364606718 HVESSModule22OperationalStatus "HVESS Module 22 Operational Status: Operational Status of Module 22 in this High Voltage Energy Storage System (or Pack 1 in systems with only one pack).  Not Operational is used when the module is initializing or not able to function (e.g. internal ...";
CM_ SG_ 2364606718 HVESSModule23OperationalStatus "HVESS Module 23 Operational Status: Operational Status of Module 23 in this High Voltage Energy Storage System (or Pack 1 in systems with only one pack).  Not Operational is used when the module is initializing or not able to function (e.g. internal ...";
CM_ SG_ 2364606718 HVESSModule24OperationalStatus "HVESS Module 24 Operational Status: Operational Status of Module 24 in this High Voltage Energy Storage System (or Pack 1 in systems with only one pack).  Not Operational is used when the module is initializing or not able to function (e.g. internal ...";
CM_ SG_ 2364606718 HVESSModule25OperationalStatus "HVESS Module 25 Operational Status: Operational Status of Module 25 in this High Voltage Energy Storage System (or Pack 1 in systems with only one pack).  Not Operational is used when the module is initializing or not able to function (e.g. internal ...";
CM_ SG_ 2364606718 HVESSModule26OperationalStatus "HVESS Module 26 Operational Status: Operational Status of Module 26 in this High Voltage Energy Storage System (or Pack 1 in systems with only one pack).  Not Operational is used when the module is initializing or not able to function (e.g. internal ...";
CM_ SG_ 2364606718 HVESSModule27OperationalStatus "HVESS Module 27 Operational Status: Operational Status of Module 27 in this High Voltage Energy Storage System (or Pack 1 in systems with only one pack).  Not Operational is used when the module is initializing or not able to function (e.g. internal ...";
CM_ SG_ 2364606718 HVESSModule28OperationalStatus "HVESS Module 28 Operational Status: Operational Status of Module 28 in this High Voltage Energy Storage System (or Pack 1 in systems with only one pack).  Not Operational is used when the module is initializing or not able to function (e.g. internal ...";
CM_ SG_ 2364606718 HVESSModule29OperationalStatus "HVESS Module 29 Operational Status: Operational Status of Module 29 in this High Voltage Energy Storage System (or Pack 1 in systems with only one pack).  Not Operational is used when the module is initializing or not able to function (e.g. internal ...";
CM_ SG_ 2364606718 HVESSModule30OperationalStatus "HVESS Module 30 Operational Status: Operational Status of Module 30 in this High Voltage Energy Storage System (or Pack 1 in systems with only one pack).  Not Operational is used when the module is initializing or not able to function (e.g. internal ...";
CM_ SG_ 2364606718 HVESSModule31OperationalStatus "HVESS Module 31 Operational Status: Operational Status of Module 31 in this High Voltage Energy Storage System (or Pack 1 in systems with only one pack).  Not Operational is used when the module is initializing or not able to function (e.g. internal ...";
CM_ SG_ 2364606718 HVESSModule32OperationalStatus "HVESS Module 32 Operational Status: Operational Status of Module 32 in this High Voltage Energy Storage System (or Pack 1 in systems with only one pack).  Not Operational is used when the module is initializing or not able to function (e.g. internal ...";
CM_ BO_ 2364606974 "High Voltage Energy Storage System Thermal Management System Status 1";
CM_ SG_ 2364606974 HVESSThrmlMngmntSstmSLIInptPwr "HVESS Thermal Management System SLI Input Power: This is the low-voltage power consumed by this Thermal Management System (TMS). If there is only one pack, or a single TMS for the entire HVES system, then this represents the total low-voltage power c...";
CM_ SG_ 2364606974 HVESSTMtSstHVtIptPw "HVESS Thermal Management System High-Voltage Input Power: This is the high-voltage power consumed by this Thermal Management System (TMS). If there is only one pack, or a single TMS for the entire HVES system, then this represents the total high-volt...";
CM_ SG_ 2364606974 HVESSThrmlMngmntSstmCmprssrSpd "HVESS Thermal Management System Compressor Speed: When the High Voltage Energy Storage System (or Pack 1 in systems with only one pack) Thermal Management System is equipped with an active cooling system (e.g. air conditioner), this is the Compressor...";
CM_ SG_ 2364606974 HVESSThrmlMngmntSstmRltvHmdt "HVESS Thermal Management System Relative Humidty: When the High Voltage Energy Storage System (or Pack 1 in systems with only one pack) Thermal Management System is equipped with a relative humidity sensor, this is the  measured Relative Humidity.Thi...";
CM_ SG_ 2364606974 HVESSThrmlMngmntSstmHtrStts "HVESS Thermal Management System Heater Status: The state of the High Voltage Energy Storage System (or Pack 1 in systems with only one pack) heaterThis parameter provides HVES system level information. If there are multiple packs in the system, then ...";
CM_ SG_ 2364606974 HVESSThrmlMngmntSstmHVILStts "HVESS Thermal Management System HVIL Status: Status of the High Voltage Interlock Loop from the viewpoint of the High Voltage Energy Storage System Thermal Management System 1.00b = HVIL Closed01b = HVIL Open10b = Error11b = Not Available";
CM_ SG_ 2364606974 HVESSThrmlMngmntSstmMd "HVESS Thermal Management System Mode: Indicates the operating mode of the Thermal Management System.  The heat transfer medium may be (e.g. liquid or air).  The cooling system may be fans, liquid coolant, or a combination of mediums.  The system may ...";
CM_ SG_ 2364606974 HVESSThrmlMngmntSstmClntLvl "HVESS Thermal Management System Coolant Level: Indicates the coolant level in the High Voltage Energy Storage System (or Pack 1 in systems with only one pack) Thermal Management System.This parameter provides HVES system level information. If there a...";
CM_ BO_ 2364607230 "High Voltage Energy Storage System Data 8";
CM_ SG_ 2364607230 HVESSHghstCllVltgMdlNmr "HVESS Highest Cell Voltage Module Number: Identifies the location of the module containing SPN 5922 (HVESS Highest Cell Voltage).This parameter provides HVES system level information. If there are multiple packs in the system, then both individual pa...";
CM_ SG_ 2364607230 HVESSHghstCllVltgCllNmr "HVESS Highest Cell Voltage Cell Number: Identifies the location of SPN 5922 (HVESS Highest Cell Voltage) within SPN 8236 (HVESS Highest Cell Voltage Module Number).This parameter provides HVES system level information. If there are multiple packs in ...";
CM_ SG_ 2364607230 HVESSLwstCllVltgMdlNmr "HVESS Lowest Cell Voltage Module Number: Identifies the location of the module containing SPN 5923 (HVESS Lowest Cell Voltage).This parameter provides HVES system level information. If there are multiple packs in the system, then both individual pack...";
CM_ SG_ 2364607230 HVESSLwstCllVltgCllNmr "HVESS Lowest Cell Voltage Cell Number: Identifies the location of SPN 5923 (HVESS Lowest Cell Voltage) within SPN 8238 (HVESS Lowest Cell Voltage Module Number).This parameter provides HVES system level information. If there are multiple packs in the...";
CM_ SG_ 2364607230 HVESSAverageCellVoltage "HVESS Average Cell Voltage: The average cell voltage in the High Voltage Energy Storage System (or Pack 1 in systems with only one pack).This parameter provides HVES system level information. If there are multiple packs in the system, then both indiv...";
CM_ BO_ 2364607486 "High Voltage Energy Storage System Data 9";
CM_ SG_ 2364607486 HVESSHghstCllTmprtrMdlNmr "HVESS Highest Cell Temperature Module Number: Identifies the location of the module containing SPN 8075 (HVESS Highest Cell Temperature).This parameter provides HVES system level information. If there are multiple packs in the system, then both indiv...";
CM_ SG_ 2364607486 HVESSHghstCllTmprtrCllNmr "HVESS Highest Cell Temperature Cell Number: Identifies the location of SPN 8075 (HVESS Highest Cell Temperature) within SPN 8241 (HVESS Highest Cell Temperature Module Number).This parameter provides HVES system level information. If there are multip...";
CM_ SG_ 2364607486 HVESSLwstCllTmprtrMdlNmr "HVESS Lowest Cell Temperature Module Number: Identifies the location of the module containing SPN 8076 (HVESS Lowest Cell Temperature ).This parameter provides HVES system level information. If there are multiple packs in the system, then both indivi...";
CM_ SG_ 2364607486 HVESSLwstCllTmprtrCllNmr "HVESS Lowest Cell Temperature Cell Number: Identifies the location of SPN 8076 (HVESS Lowest Cell Temperature) within SPN 8243 (HVESS Lowest Cell Temperature Module Number).This parameter provides HVES system level information. If there are multiple ...";
CM_ BO_ 2364607742 "High Voltage Energy Storage System Data 10";
CM_ SG_ 2364607742 HVESSHghstCllSttfChrgMdlNmr "HVESS Highest Cell State of Charge Module Number: Identifies the location of the module containing SPN 8085 (HVESS Highest Cell State of Charge).This parameter provides HVES system level information. If there are multiple packs in the system, then bo...";
CM_ SG_ 2364607742 HVESSHghstCllSttfChrgCllNmr "HVESS Highest Cell State of Charge Cell Number: Identifies the location of SPN 8085 (HVESS Highest Cell State of Charge) within SPN 8245 (HVESS Highest Cell State of Charge Module Number).This parameter provides HVES system level information. If ther...";
CM_ SG_ 2364607742 HVESSLwstCllSttfChrgMdlNmr "HVESS Lowest Cell State of Charge Module Number: Identifies the location of the module containing SPN 8084 (HVESS Lowest Cell State of Charge).This parameter provides HVES system level information. If there are multiple packs in the system, then both...";
CM_ SG_ 2364607742 HVESSLwstCllSttfChrgCllNmr "HVESS Lowest Cell State of Charge Cell Number: Identifies the location of SPN 8084 (HVESS Lowest Cell State of Charge) within SPN 8247 (HVESS Lowest Cell State of Charge Module Number).This parameter provides HVES system level information. If there a...";
CM_ SG_ 2364607742 HVESSHghVltgBsAtvIsltnTstRslts "HVESS High-Voltage Bus Active Isolation Test Results: The isolation resistance expressed in Ohms per Volt that resulted from the High-Voltage Bus Active Isolation Test.See SPN 8096 (HVESS High-Voltage Bus Active Isolation Test Status) for test status...";
CM_ SG_ 2364607742 HVESSHghVltgBsPssvIsltnTstRslts "HVESS High-Voltage Bus Passive Isolation Test Results: The isolation resistance expressed in Ohms per Volt that resulted from the High-Voltage Bus Passive Isolation Test.See SPN 8097 (HVESS High-Voltage Bus Passive Isolation Test Status) for test sta...";
CM_ BO_ 2364608510 "Engine Operating Information 2";
CM_ SG_ 2364608510 EnginePowerDerateRequest "Engine Power Derate Request: Derate request made from the engine control system to an external system, where the engine is requesting an external device to reduce the load being applied. A zero value indicates no derate, while any other value indicat...";
CM_ SG_ 2364608510 EngineSelfInducedDerateLoad "Engine Self-Induced Derate Load: The self-induced derate load that the Engine Control Module is trying to achieve.  A value of 0% means there is no active derate.";
CM_ BO_ 2364609278 "DC/DC Converter 1 Control";
CM_ SG_ 2364609278 DCDC1HghSdVltgBstStpnt "DC/DC 1 High Side Voltage Boost Setpoint: The set point for regulating the high side voltage during boost mode.";
CM_ SG_ 2364609278 DCDC1LowSideVoltageBuckSetpoint "DC/DC 1 Low Side Voltage Buck Setpoint: The set point for regulating the low side voltage during buck mode.";
CM_ SG_ 2364609278 DCDC1LwSdVltgBkDfltStpnt "DC/DC 1 Low Side Voltage Buck Default Setpoint: The set point for the converter default low side voltage during buck mode.   This setting may be used for when communication has been lost with the controlling device.  When set to Not Available (FFFFh)...";
CM_ SG_ 2364609278 DCDC1OperationalCommand "DC/DC 1 Operational Command: Command to enable or disable operation.0000b = Disable - in this mode all high voltage switching is disabled0001b = Operate in standby mode; system is waiting for command to enter buck or boost mode0010b = Operate in buck...";
CM_ SG_ 2364609278 DCDC1ControlCounter "DCDC 1 Control Counter: The message counter is used to detect situations where the transmitting ECU malfunction repeats the same frame all the time. The receiver of the information may use the counter parameter to detect this situation. The transmitt...";
CM_ SG_ 2364609278 DCDC1ControlCRC "DCDC 1 Control CRC: The CRC is defined as follows: • Length: 8 bits • Polynomial: x^8+x^5+x^3+x^2+x+1 • Initial Value: FFh • Input Data Reflection: Not reflected • Result Data Reflection: Not reflected • XOR value: FFhSAE makes no claim of the functi...";
CM_ BO_ 2364609534 "DC/DC Converter 1 Operating Status";
CM_ SG_ 2364609534 DCDC1HVILStatus "DC/DC 1 HVIL Status: High Voltage Interlock Loop (HVIL) state of the DC/DC Converter.00b = HVIL Closed01b = HVIL Open10b = Error11b = Not Available";
CM_ SG_ 2364609534 DCDC1LoadshedRequest "DC/DC 1 Loadshed Request: The loadshed request is a request to the controlling device to reduce the DC/DC Converter loads.  The Loadshed Requested state is an indication that this DC/DC Converter has a malfunction or is in a limit condition and if th...";
CM_ SG_ 2364609534 DCDC1OperationalStatus "DC/DC 1 Operational Status: Operating state of the DC/DC Converter0000b = Disabled 0001b = Initialization in process.  The device is powering up.  This process may include both internal checks, as well as system checks being run by the DC/DC Converte...";
CM_ SG_ 2364609534 DCDC1PwrLmtdtCnvrtrTmprtr "DC/DC 1 Power Limit due to Converter Temperature: Indicates whether or not output power is being limited due to Converter Temperature (see SPN 8592) approaching or exceeding the maximum limit.00b = No power limit for this reason01b = Power limited fo...";
CM_ SG_ 2364609534 DCDC1PwrLmtdtEltrnFltrTmprtr "DC/DC 1 Power Limit due to Electronic Filter Temperature: Indicates whether or not output power is being limited due to Output Electronic Filter Temperature (see SPN 8693) approaching or exceeding the maximum limit.00b = No power limit for this reaso...";
CM_ SG_ 2364609534 DCDC1PwrLmtdtHghSdCrrnt "DC/DC 1 Power Limit due to High Side Current: Indicates whether or not output power is being limited due to high side current (see SPN 8588) approaching or exceeding the maximum limit (see SPN 8565).00b = No power limit for this reason01b = Power lim...";
CM_ SG_ 2364609534 DCDC1PwrLmtdtHghSdVltgMnmm "DC/DC 1 Power Limit due to High Side Voltage Minimum: Indicates whether or not output power is being limited due to high side voltage (see SPN 8587) approaching or falling below the minimum limit (see SPN 8563).00b = No power limit for this reason01b...";
CM_ SG_ 2364609534 DCDC1PwrLmtdtHghSdVltgMxmm "DC/DC 1 Power Limit due to High Side Voltage Maximum: Indicates whether or not output power is being limited due to high side voltage (see SPN 8587) approaching or exceeding the maximum limit (see SPN 8564).00b = No power limit for this reason01b = P...";
CM_ SG_ 2364609534 DCDC1PwrLmtdtLwSdCrrnt "DC/DC 1 Power Limit due to Low Side Current: Indicates whether or not output power is being limited due to low side current (see SPN 8586) approaching or exceeding the maximum limit (see SPN 8568).00b = No power limit for this reason01b = Power limit...";
CM_ SG_ 2364609534 DCDC1PwrLmtdtLwSdVltgMnmm "DC/DC 1 Power Limit due to Low Side Voltage Minimum: Indicates whether or not output power is being limited due to low side voltage (see SPN 8585) approaching or falling below the minimum limit (see SPN 8566).00b = No power limit for this reason01b =...";
CM_ SG_ 2364609534 DCDC1PwrLmtdtLwSdVltgMxmm "DC/DC 1 Power Limit due to Low Side Voltage Maximum: Indicates whether or not output power is being limited due to low side voltage (see SPN 8585) approaching or exceeding the maximum limit (see SPN 8567).00b = No power limit for this reason01b = Pow...";
CM_ SG_ 2364609534 DCDC1PwrLmtdtPwrEltrnsTmprtr "DC/DC 1 Power Limit due to Power Electronics Temperature: Indicates whether or not output power is being limited due to Power Electronics Temperature (see SPN 8594) approaching or exceeding the maximum limit.00b = No power limit for this reason01b = ...";
CM_ SG_ 2364609534 DCDC1PwrLmtdtSLIBttrTrmnlCrrnt "DC/DC 1 Power Limit due to SLI Battery Terminal Current: Indicates whether or not output power is being limited due to the SLI battery terminal current (see SPN 8590) approaching or exceeding limits (see SPN 8818).00b = No power limit for this reason...";
CM_ SG_ 2364609534 DCDC1PwrLmtdtSLIBttrTrmnlTmprtr "DC/DC 1 Power Limit due to SLI Battery Terminal Temperature: Indicates whether or not output power is being limited due to the SLI battery terminal temperature (see SPN 8591) approaching or exceeding limits (see SPN 8819).00b = No power limit for thi...";
CM_ SG_ 2364609534 DCDC1PwrLmtdtSLIBttrTrmnlVltg "DC/DC 1 Power Limit due to SLI Battery Terminal Voltage: Indicates whether or not output power is being limited due to the SLI battery terminal voltage (see SPN 8589) approaching or exceeding limits (see SPN 8817).00b = No power limit for this reason...";
CM_ SG_ 2364609534 DCDC1PwrLmtdtUndfndRsn "DC/DC 1 Power Limit due to Undefined Reason: Indicates whether or not output power is being limited due to an undefined reason.00b = No power limit for this reason01b = Power limited for this reason10b = Error11b = Not Available";
CM_ SG_ 2364609534 DCDC1OperatingStatusCounter "DCDC 1 Operating Status Counter: The message counter is used to detect situations where the transmitting ECU malfunction repeats the same frame all the time. The receiver of the information may use the counter parameter to detect this situation. The ...";
CM_ SG_ 2364609534 DCDC1OperatingStatusCRC "DCDC 1 Operating Status CRC: The CRC is defined as follows: • Length: 8 bits • Polynomial: x^8+x^5+x^3+x^2+x+1 • Initial Value: FFh • Input Data Reflection: Not reflected • Result Data Reflection: Not reflected • XOR value: FFhSAE makes no claim of t...";
CM_ BO_ 2364609790 "DC/DC Converter 1 Voltage and Current";
CM_ SG_ 2364609790 DCDC1HighSideCurrent "DC/DC 1 High Side Current: Indicates the measured HVES or high side current measured at the point of control inside the DC/DC Converter.  The current is negative if the converter is charging the SLI battery from the hybrid battery.";
CM_ SG_ 2364609790 DCDC1HighSideVoltage "DC/DC 1 High Side Voltage: Indicates the measured HVES or high side voltage measured at the point of control inside the DC/DC Converter.";
CM_ SG_ 2364609790 DCDC1LowSideCurrent "DC/DC 1 Low Side Current: Indicates the measured SLI battery or low side current measured at the point of control inside the DC/DC Converter.  The current is positive if the converter is charging the SLI battery from the hybrid battery.";
CM_ SG_ 2364609790 DCDC1LowSideVoltage "DC/DC 1 Low Side Voltage: Indicates the measured SLI battery or low side voltage measured at the point of control inside the DC/DC Converter.";
CM_ BO_ 2364610046 "DC/DC Converter 1 SLI Battery Status";
CM_ SG_ 2364610046 DCDC1SLIBatteryTerminalCurrent "DC/DC 1 SLI Battery Terminal Current: Parameter indicating the SLI battery terminal current for control use by the DC/DC converter.  The current is positive if the SLI battery or low side voltage source is being charged from the HVES.";
CM_ SG_ 2364610046 DCDC1SLIBatteryTerminalVoltage "DC/DC 1 SLI Battery Terminal Voltage: Parameter indicating the SLI battery terminal voltage for control use by the DC/DC converter.";
CM_ SG_ 2364610046 DCDC1SLIBttrTrmnlTmprtr "DC/DC 1 SLI Battery Terminal Temperature: Parameter indicating the SLI battery terminal temperature for control use by the DC/DC converter.";
CM_ BO_ 2364610558 "DC/DC Converter 1 Status 2";
CM_ SG_ 2364610558 DCDC1HighSidePower "DC/DC 1 High Side Power: Indicates the measured HVES or high side power measured at the DC/DC Converter.  The high side power is positive if the converter is charging the hybrid battery from the SLI battery (i.e. Boost Mode).  The high side power is ...";
CM_ SG_ 2364610558 DCDC1LowSidePower "DC/DC 1 Low Side Power: Indicates the measured SLI battery or low side power measured at the DC/DC Converter.  The low side power is positive if the converter is charging the SLI battery from the hybrid battery (i.e. Buck Mode).  The low side power i...";
CM_ SG_ 2364610558 DCDC1HghSdNgtvtChsssGrndVltg "DC/DC 1 High Side Negative to Chassis Ground Voltage: The voltage level of the high voltage DC side, as measured by the DC/DC between the negative side of the High Voltage DC Side input and the chassis of the DC/DC enclosure.  This voltage can be use...";
CM_ BO_ 2364610814 "DC/DC Converter 2 Control";
CM_ SG_ 2364610814 DCDC2HghSdVltgBstStpnt "DC/DC 2 High Side Voltage Boost Setpoint: The set point for regulating the high side voltage during boost mode.";
CM_ SG_ 2364610814 DCDC2LowSideVoltageBuckSetpoint "DC/DC 2 Low Side Voltage Buck Setpoint: The set point for regulating the low side voltage during buck mode.";
CM_ SG_ 2364610814 DCDC2LwSdVltgBkDfltStpnt "DC/DC 2 Low Side Voltage Buck Default Setpoint: The set point for the converter default low side voltage during buck mode.   This setting may be used for when communication has been lost with the controlling device.  When set to Not Available (FFFFh)...";
CM_ SG_ 2364610814 DCDC2OperationalCommand "DC/DC 2 Operational Command: Command to enable or disable operation.0000b = Disable - in this mode all high voltage switching is disabled0001b = Operate in standby mode; system is waiting for command to enter buck or boost mode0010b = Operate in buck...";
CM_ SG_ 2364610814 DCDC2ControlCounter "DCDC 2 Control Counter: The message counter is used to detect situations where the transmitting ECU malfunction repeats the same frame all the time. The receiver of the information may use the counter parameter to detect this situation. The transmitt...";
CM_ SG_ 2364610814 DCDC2ControlCRC "DCDC 2 Control CRC: The CRC is defined as follows: • Length: 8 bits • Polynomial: x^8+x^5+x^3+x^2+x+1 • Initial Value: FFh • Input Data Reflection: Not reflected • Result Data Reflection: Not reflected • XOR value: FFhSAE makes no claim of the functi...";
CM_ BO_ 2364611070 "DC/DC Converter 2 Operating Status";
CM_ SG_ 2364611070 DCDC2HVILStatus "DC/DC 2 HVIL Status: High Voltage Interlock Loop (HVIL) state of the DC/DC Converter.00b = HVIL Closed01b = HVIL Open10b = Error11b = Not Available";
CM_ SG_ 2364611070 DCDC2LoadshedRequest "DC/DC 2 Loadshed Request: The loadshed request is a request to the controlling device to reduce the DC/DC Converter loads.  The Loadshed Requested state is an indication that this DC/DC Converter has a malfunction or is in a limit condition and if th...";
CM_ SG_ 2364611070 DCDC2OperationalStatus "DC/DC 2 Operational Status: Operating state of the DC/DC Converter0000b = Disabled 0001b = Initialization in process.  The device is powering up.  This process may include both internal checks, as well as system checks being run by the DC/DC Converte...";
CM_ SG_ 2364611070 DCDC2PwrLmtdtCnvrtrTmprtr "DC/DC 2 Power Limit due to Converter Temperature: Indicates whether or not output power is being limited due to Converter Temperature (see SPN 8936) approaching or exceeding the maximum limit.00b = No power limit for this reason01b = Power limited fo...";
CM_ SG_ 2364611070 DCDC2PwrLmtdtEltrnFltrTmprtr "DC/DC 2 Power Limit due to Electronic Filter Temperature: Indicates whether or not output power is being limited due to Output Electronic Filter Temperature (see SPN 8937) approaching or exceeding the maximum limit.00b = No power limit for this reaso...";
CM_ SG_ 2364611070 DCDC2PwrLmtdtHghSdCrrnt "DC/DC 2 Power Limit due to High Side Current: Indicates whether or not output power is being limited due to high side current (see SPN 8914) approaching or exceeding the maximum limit (see SPN 8946).00b = No power limit for this reason01b = Power lim...";
CM_ SG_ 2364611070 DCDC2PwrLmtdtHghSdVltgMnmm "DC/DC 2 Power Limit due to High Side Voltage Minimum: Indicates whether or not output power is being limited due to high side voltage (see SPN 8913) approaching or falling below the minimum limit (see SPN 8944).00b = No power limit for this reason01b...";
CM_ SG_ 2364611070 DCDC2PwrLmtdtHghSdVltgMxmm "DC/DC 2 Power Limit due to High Side Voltage Maximum: Indicates whether or not output power is being limited due to high side voltage (see SPN 8913) approaching or exceeding the maximum limit (see SPN 8945).00b = No power limit for this reason01b = P...";
CM_ SG_ 2364611070 DCDC2PwrLmtdtLwSdCrrnt "DC/DC 2 Power Limit due to Low Side Current: Indicates whether or not output power is being limited due to low side current (see SPN 8912) approaching or exceeding the maximum limit (see SPN 8943).00b = No power limit for this reason01b = Power limit...";
CM_ SG_ 2364611070 DCDC2PwrLmtdtLwSdVltgMnmm "DC/DC 2 Power Limit due to Low Side Voltage Minimum: Indicates whether or not output power is being limited due to low side voltage (see SPN 8911) approaching or falling below the minimum limit (see SPN 8941).00b = No power limit for this reason01b =...";
CM_ SG_ 2364611070 DCDC2PwrLmtdtLwSdVltgMxmm "DC/DC 2 Power Limit due to Low Side Voltage Maximum: Indicates whether or not output power is being limited due to low side voltage (see SPN 8911) approaching or exceeding the maximum limit (see SPN 8942).00b = No power limit for this reason01b = Pow...";
CM_ SG_ 2364611070 DCDC2PwrLmtdtPwrEltrnsTmprtr "DC/DC 2 Power Limit due to Power Electronics Temperature: Indicates whether or not output power is being limited due to Power Electronics Temperature (see SPN 8938) approaching or exceeding the maximum limit.00b = No power limit for this reason01b = ...";
CM_ SG_ 2364611070 DCDC2PwrLmtdtSLIBttrTrmnlCrrnt "DC/DC 2 Power Limit due to SLI Battery Terminal Current: Indicates whether or not output power is being limited due to the SLI battery terminal current (see SPN 8916) approaching or exceeding limits (see SPN 8934).00b = No power limit for this reason...";
CM_ SG_ 2364611070 DCDC2PwrLmtdtSLIBttrTrmnlTmprtr "DC/DC 2 Power Limit due to SLI Battery Terminal Temperature: Indicates whether or not output power is being limited due to the SLI battery terminal temperature (see SPN 8917) approaching or exceeding limits (see SPN 8935).00b = No power limit for thi...";
CM_ SG_ 2364611070 DCDC2PwrLmtdtSLIBttrTrmnlVltg "DC/DC 2 Power Limit due to SLI Battery Terminal Voltage: Indicates whether or not output power is being limited due to the SLI battery terminal voltage (see SPN 8915) approaching or exceeding limits (see SPN 8933).00b = No power limit for this reason...";
CM_ SG_ 2364611070 DCDC2PwrLmtdtUndfndRsn "DC/DC 2 Power Limit due to Undefined Reason: Indicates whether or not output power is being limited due to an undefined reason.00b = No power limit for this reason01b = Power limited for this reason10b = Error11b = Not Available";
CM_ SG_ 2364611070 DCDC2OperatingStatusCounter "DCDC 2 Operating Status Counter: The message counter is used to detect situations where the transmitting ECU malfunction repeats the same frame all the time. The receiver of the information may use the counter parameter to detect this situation. The ...";
CM_ SG_ 2364611070 DCDC2OperatingStatusCRC "DCDC 2 Operating Status CRC: The CRC is defined as follows: • Length: 8 bits • Polynomial: x^8+x^5+x^3+x^2+x+1 • Initial Value: FFh • Input Data Reflection: Not reflected • Result Data Reflection: Not reflected • XOR value: FFhSAE makes no claim of t...";
CM_ BO_ 2364611326 "DC/DC Converter 2 Voltage and Current";
CM_ SG_ 2364611326 DCDC2HighSideCurrent "DC/DC 2 High Side Current: Indicates the measured HVES or high side current measured at the point of control inside the DC/DC Converter.  The current is negative if the converter is charging the SLI battery from the hybrid battery.";
CM_ SG_ 2364611326 DCDC2HighSideVoltage "DC/DC 2 High Side Voltage: Indicates the measured HVES or high side voltage measured at the point of control inside the DC/DC Converter.";
CM_ SG_ 2364611326 DCDC2LowSideCurrent "DC/DC 2 Low Side Current: Indicates the measured SLI battery or low side current measured at the point of control inside the DC/DC Converter.  The current is positive if the converter is charging the SLI battery from the hybrid battery.";
CM_ SG_ 2364611326 DCDC2LowSideVoltage "DC/DC 2 Low Side Voltage: Indicates the measured SLI battery or low side voltage measured at the point of control inside the DC/DC Converter.";
CM_ BO_ 2364611582 "DC/DC Converter 2 SLI Battery Status";
CM_ SG_ 2364611582 DCDC2SLIBatteryTerminalCurrent "DC/DC 2 SLI Battery Terminal Current: Parameter indicating the SLI battery terminal current for control use by the DC/DC converter.  The current is positive if the SLI battery or low side voltage source is being charged from the HVES.";
CM_ SG_ 2364611582 DCDC2SLIBatteryTerminalVoltage "DC/DC 2 SLI Battery Terminal Voltage: Parameter indicating the SLI battery terminal voltage for control use by the DC/DC converter.";
CM_ SG_ 2364611582 DCDC2SLIBttrTrmnlTmprtr "DC/DC 2 SLI Battery Terminal Temperature: Parameter indicating the SLI battery terminal temperature for control use by the DC/DC converter.";
CM_ BO_ 2364611838 "DC/DC Converter 2 Status 2";
CM_ SG_ 2364611838 DCDC2HighSidePower "DC/DC 2 High Side Power: Indicates the measured HVES or high side power measured at the DC/DC Converter.  The high side power is positive if the converter is charging the hybrid battery from the SLI battery (i.e. Boost Mode).  The high side power is ...";
CM_ SG_ 2364611838 DCDC2LowSidePower "DC/DC 2 Low Side Power: Indicates the measured SLI battery or low side power measured at the DC/DC Converter.  The low side power is positive if the converter is charging the SLI battery from the hybrid battery (i.e. Buck Mode).  The low side power i...";
CM_ SG_ 2364611838 DCDC2HghSdNgtvtChsssGrndVltg "DC/DC 2 High Side Negative to Chassis Ground Voltage: The voltage level of the high voltage DC side, as measured by the DC/DC between the negative side of the High Voltage DC Side input and the chassis of the DC/DC enclosure.  This voltage can be use...";
CM_ BO_ 2364612094 "DC/DC Converter 3 Control";
CM_ SG_ 2364612094 DCDC3HghSdVltgBstStpnt "DC/DC 3 High Side Voltage Boost Setpoint: The set point for regulating the high side voltage during boost mode.";
CM_ SG_ 2364612094 DCDC3LowSideVoltageBuckSetpoint "DC/DC 3 Low Side Voltage Buck Setpoint: The set point for regulating the low side voltage during buck mode.";
CM_ SG_ 2364612094 DCDC3LwSdVltgBkDfltStpnt "DC/DC 3 Low Side Voltage Buck Default Setpoint: The set point for the converter default low side voltage during buck mode.   This setting may be used for when communication has been lost with the controlling device.  When set to Not Available (FFFFh)...";
CM_ SG_ 2364612094 DCDC3OperationalCommand "DC/DC 3 Operational Command: Command to enable or disable operation.0000b = Disable - in this mode all high voltage switching is disabled0001b = Operate in standby mode; system is waiting for command to enter buck or boost mode0010b = Operate in buck...";
CM_ SG_ 2364612094 DCDC3ControlCounter "DCDC 3 Control Counter: The message counter is used to detect situations where the transmitting ECU malfunction repeats the same frame all the time. The receiver of the information may use the counter parameter to detect this situation. The transmitt...";
CM_ SG_ 2364612094 DCDC3ControlCRC "DCDC 3 Control CRC: The CRC is defined as follows: • Length: 8 bits • Polynomial: x^8+x^5+x^3+x^2+x+1 • Initial Value: FFh • Input Data Reflection: Not reflected • Result Data Reflection: Not reflected • XOR value: FFhSAE makes no claim of the functi...";
CM_ BO_ 2364612350 "DC/DC Converter 3 Operating Status";
CM_ SG_ 2364612350 DCDC3HVILStatus "DC/DC 3 HVIL Status: High Voltage Interlock Loop (HVIL) state of the DC/DC Converter.00b = HVIL Closed01b = HVIL Open10b = Error11b = Not Available";
CM_ SG_ 2364612350 DCDC3LoadshedRequest "DC/DC 3 Loadshed Request: The loadshed request is a request to the controlling device to reduce the DC/DC Converter loads.  The Loadshed Requested state is an indication that this DC/DC Converter has a malfunction or is in a limit condition and if th...";
CM_ SG_ 2364612350 DCDC3OperationalStatus "DC/DC 3 Operational Status: Operating state of the DC/DC Converter0000b = Disabled 0001b = Initialization in process.  The device is powering up.  This process may include both internal checks, as well as system checks being run by the DC/DC Converte...";
CM_ SG_ 2364612350 DCDC3PwrLmtdtCnvrtrTmprtr "DC/DC 3 Power Limit due to Converter Temperature: Indicates whether or not output power is being limited due to Converter Temperature (see SPN 8991) approaching or exceeding the maximum limit.00b = No power limit for this reason01b = Power limited fo...";
CM_ SG_ 2364612350 DCDC3PwrLmtdtEltrnFltrTmprtr "DC/DC 3 Power Limit due to Electronic Filter Temperature: Indicates whether or not output power is being limited due to Output Electronic Filter Temperature (see SPN 8992) approaching or exceeding the maximum limit.00b = No power limit for this reaso...";
CM_ SG_ 2364612350 DCDC3PwrLmtdtHghSdCrrnt "DC/DC 3 Power Limit due to High Side Current: Indicates whether or not output power is being limited due to high side current (see SPN 8969) approaching or exceeding the maximum limit (see SPN 9001).00b = No power limit for this reason01b = Power lim...";
CM_ SG_ 2364612350 DCDC3PwrLmtdtHghSdVltgMnmm "DC/DC 3 Power Limit due to High Side Voltage Minimum: Indicates whether or not output power is being limited due to high side voltage (see SPN 8968) approaching or falling below the minimum limit (see SPN 8999).00b = No power limit for this reason01b...";
CM_ SG_ 2364612350 DCDC3PwrLmtdtHghSdVltgMxmm "DC/DC 3 Power Limit due to High Side Voltage Maximum: Indicates whether or not output power is being limited due to high side voltage (see SPN 8968) approaching or exceeding the maximum limit (see SPN 9000).00b = No power limit for this reason01b = P...";
CM_ SG_ 2364612350 DCDC3PwrLmtdtLwSdCrrnt "DC/DC 3 Power Limit due to Low Side Current: Indicates whether or not output power is being limited due to low side current (see SPN 8967) approaching or exceeding the maximum limit (see SPN 8998).00b = No power limit for this reason01b = Power limit...";
CM_ SG_ 2364612350 DCDC3PwrLmtdtLwSdVltgMnmm "DC/DC 3 Power Limit due to Low Side Voltage Minimum: Indicates whether or not output power is being limited due to low side voltage (see SPN 8966) approaching or falling below the minimum limit (see SPN 8996).00b = No power limit for this reason01b =...";
CM_ SG_ 2364612350 DCDC3PwrLmtdtLwSdVltgMxmm "DC/DC 3 Power Limit due to Low Side Voltage Maximum: Indicates whether or not output power is being limited due to low side voltage (see SPN 8966) approaching or exceeding the maximum limit (see SPN 8997).00b = No power limit for this reason01b = Pow...";
CM_ SG_ 2364612350 DCDC3PwrLmtdtPwrEltrnsTmprtr "DC/DC 3 Power Limit due to Power Electronics Temperature: Indicates whether or not output power is being limited due to Power Electronics Temperature (see SPN 8993) approaching or exceeding the maximum limit.00b = No power limit for this reason01b = ...";
CM_ SG_ 2364612350 DCDC3PwrLmtdtSLIBttrTrmnlCrrnt "DC/DC 3 Power Limit due to SLI Battery Terminal Current: Indicates whether or not output power is being limited due to the SLI battery terminal current (see SPN 8971) approaching or exceeding limits (see SPN 8989).00b = No power limit for this reason...";
CM_ SG_ 2364612350 DCDC3PwrLmtdtSLIBttrTrmnlTmprtr "DC/DC 3 Power Limit due to SLI Battery Terminal Temperature: Indicates whether or not output power is being limited due to the SLI battery terminal temperature (see SPN 8972) approaching or exceeding limits (see SPN 8990).00b = No power limit for thi...";
CM_ SG_ 2364612350 DCDC3PwrLmtdtSLIBttrTrmnlVltg "DC/DC 3 Power Limit due to SLI Battery Terminal Voltage: Indicates whether or not output power is being limited due to the SLI battery terminal voltage (see SPN 8970) approaching or exceeding limits (see SPN 8988).00b = No power limit for this reason...";
CM_ SG_ 2364612350 DCDC3PwrLmtdtUndfndRsn "DC/DC 3 Power Limit due to Undefined Reason: Indicates whether or not output power is being limited due to an undefined reason.00b = No power limit for this reason01b = Power limited for this reason10b = Error11b = Not Available";
CM_ SG_ 2364612350 DCDC3OperatingStatusCounter "DCDC 3 Operating Status Counter: The message counter is used to detect situations where the transmitting ECU malfunction repeats the same frame all the time. The receiver of the information may use the counter parameter to detect this situation. The ...";
CM_ SG_ 2364612350 DCDC3OperatingStatusCRC "DCDC 3 Operating Status CRC: The CRC is defined as follows: • Length: 8 bits • Polynomial: x^8+x^5+x^3+x^2+x+1 • Initial Value: FFh • Input Data Reflection: Not reflected • Result Data Reflection: Not reflected • XOR value: FFhSAE makes no claim of t...";
CM_ BO_ 2364612606 "DC/DC Converter 3 Voltage and Current";
CM_ SG_ 2364612606 DCDC3HighSideCurrent "DC/DC 3 High Side Current: Indicates the measured HVES or high side current measured at the point of control inside the DC/DC Converter.  The current is negative if the converter is charging the SLI battery from the hybrid battery.";
CM_ SG_ 2364612606 DCDC3HighSideVoltage "DC/DC 3 High Side Voltage: Indicates the measured HVES or high side voltage measured at the point of control inside the DC/DC Converter.";
CM_ SG_ 2364612606 DCDC3LowSideCurrent "DC/DC 3 Low Side Current: Indicates the measured SLI battery or low side current measured at the point of control inside the DC/DC Converter.  The current is positive if the converter is charging the SLI battery from the hybrid battery.";
CM_ SG_ 2364612606 DCDC3LowSideVoltage "DC/DC 3 Low Side Voltage: Indicates the measured SLI battery or low side voltage measured at the point of control inside the DC/DC Converter.";
CM_ BO_ 2364612862 "DC/DC Converter 3 SLI Battery Status";
CM_ SG_ 2364612862 DCDC3SLIBatteryTerminalCurrent "DC/DC 3 SLI Battery Terminal Current: Parameter indicating the SLI battery terminal current for control use by the DC/DC converter.  The current is positive if the SLI battery or low side voltage source is being charged from the HVES.";
CM_ SG_ 2364612862 DCDC3SLIBatteryTerminalVoltage "DC/DC 3 SLI Battery Terminal Voltage: Parameter indicating the SLI battery terminal voltage for control use by the DC/DC converter.";
CM_ SG_ 2364612862 DCDC3SLIBttrTrmnlTmprtr "DC/DC 3 SLI Battery Terminal Temperature: Parameter indicating the SLI battery terminal temperature for control use by the DC/DC converter.";
CM_ BO_ 2364613118 "DC/DC Converter 3 Status 2";
CM_ SG_ 2364613118 DCDC3HighSidePower "DC/DC 3 High Side Power: Indicates the measured HVES or high side power measured at the DC/DC Converter.  The high side power is positive if the converter is charging the hybrid battery from the SLI battery (i.e. Boost Mode).  The high side power is ...";
CM_ SG_ 2364613118 DCDC3LowSidePower "DC/DC 3 Low Side Power: Indicates the measured SLI battery or low side power measured at the DC/DC Converter.  The low side power is positive if the converter is charging the SLI battery from the hybrid battery (i.e. Buck Mode).  The low side power i...";
CM_ SG_ 2364613118 DCDC3HghSdNgtvtChsssGrndVltg "DC/DC 3 High Side Negative to Chassis Ground Voltage: The voltage level of the high voltage DC side, as measured by the DC/DC between the negative side of the High Voltage DC Side input and the chassis of the DC/DC enclosure.  This voltage can be use...";
CM_ BO_ 2364613374 "DC/DC Converter 4 Control";
CM_ SG_ 2364613374 DCDC4HghSdVltgBstStpnt "DC/DC 4 High Side Voltage Boost Setpoint: The set point for regulating the high side voltage during boost mode.";
CM_ SG_ 2364613374 DCDC4LowSideVoltageBuckSetpoint "DC/DC 4 Low Side Voltage Buck Setpoint: The set point for regulating the low side voltage during buck mode.";
CM_ SG_ 2364613374 DCDC4LwSdVltgBkDfltStpnt "DC/DC 4 Low Side Voltage Buck Default Setpoint: The set point for the converter default low side voltage during buck mode.   This setting may be used for when communication has been lost with the controlling device.  When set to Not Available (FFFFh)...";
CM_ SG_ 2364613374 DCDC4OperationalCommand "DC/DC 4 Operational Command: Command to enable or disable operation.0000b = Disable - in this mode all high voltage switching is disabled0001b = Operate in standby mode; system is waiting for command to enter buck or boost mode0010b = Operate in buck...";
CM_ SG_ 2364613374 DCDC4ControlCounter "DCDC 4 Control Counter: The message counter is used to detect situations where the transmitting ECU malfunction repeats the same frame all the time. The receiver of the information may use the counter parameter to detect this situation. The transmitt...";
CM_ SG_ 2364613374 DCDC4ControlCRC "DCDC 4 Control CRC: The CRC is defined as follows: • Length: 8 bits • Polynomial: x^8+x^5+x^3+x^2+x+1 • Initial Value: FFh • Input Data Reflection: Not reflected • Result Data Reflection: Not reflected • XOR value: FFhSAE makes no claim of the functi...";
BA_DEF_ SG_  "SPN" INT 0 524287;
BA_DEF_ BO_  "VFrameFormat" ENUM  "StandardCAN","ExtendedCAN","reserved","J1939PG";
BA_DEF_DEF_  "SPN" 0;
BA_DEF_DEF_  "VFrameFormat" "J1939PG";
BA_ "SPN" SG_ 2364555262 EngineCylinder6HeatRelease 6416;
BA_ "SPN" SG_ 2364555262 EngineCylinder6PeakPressure 6417;
BA_ "SPN" SG_ 2364555262 EngnClndr6LwFrqnKnkLvl 7614;
BA_ "SPN" SG_ 2364555262 EngnClndr6MxmmPrssrInrsRt 7634;
BA_ "SPN" SG_ 2364555262 EngnClndr6PrssrSnsrPrlmnrFMI 6419;
BA_ "SPN" SG_ 2364555262 EngnClndr6SnhrnsKnkLvl 6418;
BA_ "SPN" SG_ 2364555518 EngineCylinder7HeatRelease 6420;
BA_ "SPN" SG_ 2364555518 EngineCylinder7PeakPressure 6421;
BA_ "SPN" SG_ 2364555518 EngnClndr7LwFrqnKnkLvl 7615;
BA_ "SPN" SG_ 2364555518 EngnClndr7MxmmPrssrInrsRt 7635;
BA_ "SPN" SG_ 2364555518 EngnClndr7PrssrSnsrPrlmnrFMI 6423;
BA_ "SPN" SG_ 2364555518 EngnClndr7SnhrnsKnkLvl 6422;
BA_ "SPN" SG_ 2364555774 EngineCylinder8HeatRelease 6424;
BA_ "SPN" SG_ 2364555774 EngineCylinder8PeakPressure 6425;
BA_ "SPN" SG_ 2364555774 EngnClndr8LwFrqnKnkLvl 7616;
BA_ "SPN" SG_ 2364555774 EngnClndr8MxmmPrssrInrsRt 7636;
BA_ "SPN" SG_ 2364555774 EngnClndr8PrssrSnsrPrlmnrFMI 6427;
BA_ "SPN" SG_ 2364555774 EngnClndr8SnhrnsKnkLvl 6426;
BA_ "SPN" SG_ 2364556030 EngineCylinder9HeatRelease 6428;
BA_ "SPN" SG_ 2364556030 EngineCylinder9PeakPressure 6429;
BA_ "SPN" SG_ 2364556030 EngnClndr9LwFrqnKnkLvl 7617;
BA_ "SPN" SG_ 2364556030 EngnClndr9MxmmPrssrInrsRt 7637;
BA_ "SPN" SG_ 2364556030 EngnClndr9PrssrSnsrPrlmnrFMI 6431;
BA_ "SPN" SG_ 2364556030 EngnClndr9SnhrnsKnkLvl 6430;
BA_ "SPN" SG_ 2364556286 EngineCylinder10HeatRelease 6432;
BA_ "SPN" SG_ 2364556286 EngineCylinder10PeakPressure 6433;
BA_ "SPN" SG_ 2364556286 EngnClndr10LwFrqnKnkLvl 7618;
BA_ "SPN" SG_ 2364556286 EngnClndr10MxmmPrssrInrsRt 7638;
BA_ "SPN" SG_ 2364556286 EngnClndr10PrssrSnsrPrlmnrFMI 6435;
BA_ "SPN" SG_ 2364556286 EngnClndr10SnhrnsKnkLvl 6434;
BA_ "SPN" SG_ 2364556542 EngineCylinder11HeatRelease 6436;
BA_ "SPN" SG_ 2364556542 EngineCylinder11PeakPressure 6437;
BA_ "SPN" SG_ 2364556542 EngnClndr11LwFrqnKnkLvl 7619;
BA_ "SPN" SG_ 2364556542 EngnClndr11MxmmPrssrInrsRt 7639;
BA_ "SPN" SG_ 2364556542 EngnClndr11PrssrSnsrPrlmnrFMI 6439;
BA_ "SPN" SG_ 2364556542 EngnClndr11SnhrnsKnkLvl 6438;
BA_ "SPN" SG_ 2364556798 EngineCylinder12HeatRelease 6440;
BA_ "SPN" SG_ 2364556798 EngineCylinder12PeakPressure 6441;
BA_ "SPN" SG_ 2364556798 EngnClndr12LwFrqnKnkLvl 7620;
BA_ "SPN" SG_ 2364556798 EngnClndr12MxmmPrssrInrsRt 7640;
BA_ "SPN" SG_ 2364556798 EngnClndr12PrssrSnsrPrlmnrFMI 6443;
BA_ "SPN" SG_ 2364556798 EngnClndr12SnhrnsKnkLvl 6442;
BA_ "SPN" SG_ 2364557054 EngineCylinder13HeatRelease 6444;
BA_ "SPN" SG_ 2364557054 EngineCylinder13PeakPressure 6445;
BA_ "SPN" SG_ 2364557054 EngnClndr13LwFrqnKnkLvl 7621;
BA_ "SPN" SG_ 2364557054 EngnClndr13MxmmPrssrInrsRt 7641;
BA_ "SPN" SG_ 2364557054 EngnClndr13PrssrSnsrPrlmnrFMI 6447;
BA_ "SPN" SG_ 2364557054 EngnClndr13SnhrnsKnkLvl 6446;
BA_ "SPN" SG_ 2364557310 EngineCylinder14HeatRelease 6448;
BA_ "SPN" SG_ 2364557310 EngineCylinder14PeakPressure 6449;
BA_ "SPN" SG_ 2364557310 EngnClndr14LwFrqnKnkLvl 7622;
BA_ "SPN" SG_ 2364557310 EngnClndr14MxmmPrssrInrsRt 7642;
BA_ "SPN" SG_ 2364557310 EngnClndr14PrssrSnsrPrlmnrFMI 6451;
BA_ "SPN" SG_ 2364557310 EngnClndr14SnhrnsKnkLvl 6450;
BA_ "SPN" SG_ 2364557566 EngineCylinder15HeatRelease 6452;
BA_ "SPN" SG_ 2364557566 EngineCylinder15PeakPressure 6453;
BA_ "SPN" SG_ 2364557566 EngnClndr15LwFrqnKnkLvl 7623;
BA_ "SPN" SG_ 2364557566 EngnClndr15MxmmPrssrInrsRt 7643;
BA_ "SPN" SG_ 2364557566 EngnClndr15PrssrSnsrPrlmnrFMI 6455;
BA_ "SPN" SG_ 2364557566 EngnClndr15SnhrnsKnkLvl 6454;
BA_ "SPN" SG_ 2364557822 EngineCylinder16HeatRelease 6456;
BA_ "SPN" SG_ 2364557822 EngineCylinder16PeakPressure 6457;
BA_ "SPN" SG_ 2364557822 EngnClndr16LwFrqnKnkLvl 7624;
BA_ "SPN" SG_ 2364557822 EngnClndr16MxmmPrssrInrsRt 7644;
BA_ "SPN" SG_ 2364557822 EngnClndr16PrssrSnsrPrlmnrFMI 6459;
BA_ "SPN" SG_ 2364557822 EngnClndr16SnhrnsKnkLvl 6458;
BA_ "SPN" SG_ 2364558078 EngineCylinder17HeatRelease 6460;
BA_ "SPN" SG_ 2364558078 EngineCylinder17PeakPressure 6461;
BA_ "SPN" SG_ 2364558078 EngnClndr17LwFrqnKnkLvl 7625;
BA_ "SPN" SG_ 2364558078 EngnClndr17MxmmPrssrInrsRt 7645;
BA_ "SPN" SG_ 2364558078 EngnClndr17PrssrSnsrPrlmnrFMI 6463;
BA_ "SPN" SG_ 2364558078 EngnClndr17SnhrnsKnkLvl 6462;
BA_ "SPN" SG_ 2364558334 EngineCylinder18HeatRelease 6464;
BA_ "SPN" SG_ 2364558334 EngineCylinder18PeakPressure 6465;
BA_ "SPN" SG_ 2364558334 EngnClndr18LwFrqnKnkLvl 7626;
BA_ "SPN" SG_ 2364558334 EngnClndr18MxmmPrssrInrsRt 7646;
BA_ "SPN" SG_ 2364558334 EngnClndr18PrssrSnsrPrlmnrFMI 6467;
BA_ "SPN" SG_ 2364558334 EngnClndr18SnhrnsKnkLvl 6466;
BA_ "SPN" SG_ 2364558590 EngineCylinder19HeatRelease 6468;
BA_ "SPN" SG_ 2364558590 EngineCylinder19PeakPressure 6469;
BA_ "SPN" SG_ 2364558590 EngnClndr19LwFrqnKnkLvl 7627;
BA_ "SPN" SG_ 2364558590 EngnClndr19MxmmPrssrInrsRt 7647;
BA_ "SPN" SG_ 2364558590 EngnClndr19PrssrSnsrPrlmnrFMI 6471;
BA_ "SPN" SG_ 2364558590 EngnClndr19SnhrnsKnkLvl 6470;
BA_ "SPN" SG_ 2364558846 EngineCylinder20HeatRelease 6472;
BA_ "SPN" SG_ 2364558846 EngineCylinder20PeakPressure 6473;
BA_ "SPN" SG_ 2364558846 EngnClndr20LwFrqnKnkLvl 7628;
BA_ "SPN" SG_ 2364558846 EngnClndr20MxmmPrssrInrsRt 7648;
BA_ "SPN" SG_ 2364558846 EngnClndr20PrssrSnsrPrlmnrFMI 6475;
BA_ "SPN" SG_ 2364558846 EngnClndr20SnhrnsKnkLvl 6474;
BA_ "SPN" SG_ 2364564478 EngnGssFlVlvNmnlDrtnCmmnd 6656;
BA_ "SPN" SG_ 2364564478 EngnGssFlVlvNmnlStrtfAttnCmmnd 6657;
BA_ "SPN" SG_ 2364564478 EngnPrChmrFlVlvNmnlDrtnCmmnd 9650;
BA_ "SPN" SG_ 2364564478 EPCFVvNSttAttCd 9651;
BA_ "SPN" SG_ 2364564734 EngnGssFlVlv1DrtnCmmnd 6658;
BA_ "SPN" SG_ 2364564734 EngnGssFlVlv2DrtnCmmnd 6659;
BA_ "SPN" SG_ 2364564734 EngnGssFlVlv3DrtnCmmnd 6660;
BA_ "SPN" SG_ 2364564734 EngnGssFlVlv4DrtnCmmnd 6661;
BA_ "SPN" SG_ 2364564990 EngnGssFlVlv5DrtnCmmnd 6662;
BA_ "SPN" SG_ 2364564990 EngnGssFlVlv6DrtnCmmnd 6663;
BA_ "SPN" SG_ 2364564990 EngnGssFlVlv7DrtnCmmnd 6664;
BA_ "SPN" SG_ 2364564990 EngnGssFlVlv8DrtnCmmnd 6665;
BA_ "SPN" SG_ 2364565246 EngnGssFlVlv10DrtnCmmnd 6667;
BA_ "SPN" SG_ 2364565246 EngnGssFlVlv11DrtnCmmnd 6668;
BA_ "SPN" SG_ 2364565246 EngnGssFlVlv12DrtnCmmnd 6669;
BA_ "SPN" SG_ 2364565246 EngnGssFlVlv9DrtnCmmnd 6666;
BA_ "SPN" SG_ 2364565502 EngnGssFlVlv13DrtnCmmnd 6670;
BA_ "SPN" SG_ 2364565502 EngnGssFlVlv14DrtnCmmnd 6671;
BA_ "SPN" SG_ 2364565502 EngnGssFlVlv15DrtnCmmnd 6672;
BA_ "SPN" SG_ 2364565502 EngnGssFlVlv16DrtnCmmnd 6673;
BA_ "SPN" SG_ 2364565758 EngnGssFlVlv17DrtnCmmnd 6674;
BA_ "SPN" SG_ 2364565758 EngnGssFlVlv18DrtnCmmnd 6675;
BA_ "SPN" SG_ 2364565758 EngnGssFlVlv19DrtnCmmnd 6676;
BA_ "SPN" SG_ 2364565758 EngnGssFlVlv20DrtnCmmnd 6677;
BA_ "SPN" SG_ 2364566014 EngnGssFlVlv1StrtfAttnCmmnd 6678;
BA_ "SPN" SG_ 2364566014 EngnGssFlVlv2StrtfAttnCmmnd 6679;
BA_ "SPN" SG_ 2364566014 EngnGssFlVlv3StrtfAttnCmmnd 6680;
BA_ "SPN" SG_ 2364566014 EngnGssFlVlv4StrtfAttnCmmnd 6681;
BA_ "SPN" SG_ 2364566270 EngnGssFlVlv5StrtfAttnCmmnd 6682;
BA_ "SPN" SG_ 2364566270 EngnGssFlVlv6StrtfAttnCmmnd 6683;
BA_ "SPN" SG_ 2364566270 EngnGssFlVlv7StrtfAttnCmmnd 6684;
BA_ "SPN" SG_ 2364566270 EngnGssFlVlv8StrtfAttnCmmnd 6685;
BA_ "SPN" SG_ 2364566526 EngnGssFlVlv10StrtfAttnCmmnd 6687;
BA_ "SPN" SG_ 2364566526 EngnGssFlVlv11StrtfAttnCmmnd 6688;
BA_ "SPN" SG_ 2364566526 EngnGssFlVlv12StrtfAttnCmmnd 6689;
BA_ "SPN" SG_ 2364566526 EngnGssFlVlv9StrtfAttnCmmnd 6686;
BA_ "SPN" SG_ 2364566782 EngnGssFlVlv13StrtfAttnCmmnd 6690;
BA_ "SPN" SG_ 2364566782 EngnGssFlVlv14StrtfAttnCmmnd 6691;
BA_ "SPN" SG_ 2364566782 EngnGssFlVlv15StrtfAttnCmmnd 6692;
BA_ "SPN" SG_ 2364566782 EngnGssFlVlv16StrtfAttnCmmnd 6693;
BA_ "SPN" SG_ 2364567038 EngnGssFlVlv17StrtfAttnCmmnd 6694;
BA_ "SPN" SG_ 2364567038 EngnGssFlVlv18StrtfAttnCmmnd 6695;
BA_ "SPN" SG_ 2364567038 EngnGssFlVlv19StrtfAttnCmmnd 6696;
BA_ "SPN" SG_ 2364567038 EngnGssFlVlv20StrtfAttnCmmnd 6697;
BA_ "SPN" SG_ 2364567294 EngnFlInjtnPmp1FlCntrlVlvCmmnd 6719;
BA_ "SPN" SG_ 2364567294 EngnFlInjtnPmp2FlCntrlVlvCmmnd 6720;
BA_ "SPN" SG_ 2364575998 HVESSAvailableDischargePower 5917;
BA_ "SPN" SG_ 2364575998 HVESSAvailableChargePower 5918;
BA_ "SPN" SG_ 2364575998 HVESSVoltageLevel 5919;
BA_ "SPN" SG_ 2364575998 HVESSCurrent 5920;
BA_ "SPN" SG_ 2364576254 HVESSFastUpdateStateofCharge 5921;
BA_ "SPN" SG_ 2364576254 HVESSHighestCellVoltage 5922;
BA_ "SPN" SG_ 2364576254 HVESSLowestCellVoltage 5923;
BA_ "SPN" SG_ 2364576254 HVESSCllVltgDffrntlStts 5924;
BA_ "SPN" SG_ 2364576510 HVESSHighestCellTemperature 8075;
BA_ "SPN" SG_ 2364576510 HVESSLowestCellTemperature 8076;
BA_ "SPN" SG_ 2364576510 HVESSAverageCellTemperature 8077;
BA_ "SPN" SG_ 2364576510 HVESSCllTmprtrDffrntlStts 8078;
BA_ "SPN" SG_ 2364576766 HVESSDischargeCapacity 8079;
BA_ "SPN" SG_ 2364576766 HVESSChargeCapacity 8080;
BA_ "SPN" SG_ 2364576766 HVESSCellBalancingCount 8081;
BA_ "SPN" SG_ 2364577022 HVESSDischargeCurrentLimit 8082;
BA_ "SPN" SG_ 2364577022 HVESSChargeCurrentLimit 8083;
BA_ "SPN" SG_ 2364577022 HVESSMinimumCellStateofCharge 8084;
BA_ "SPN" SG_ 2364577022 HVESSMaximumCellStateofCharge 8085;
BA_ "SPN" SG_ 2364577278 HVESSBusVoltage 8086;
BA_ "SPN" SG_ 2364577278 HVESSIgnitionVoltage 8087;
BA_ "SPN" SG_ 2364577278 HVESSIntakeCoolantTemperature 8088;
BA_ "SPN" SG_ 2364577278 HVESSOutletCoolantTemperature 8089;
BA_ "SPN" SG_ 2364577278 HVESSElectronicsTemperature 8204;
BA_ "SPN" SG_ 2364577278 HVESSTemperature 9119;
BA_ "SPN" SG_ 2364577534 HVESSHghVltgBsPstvCnttrStt 8091;
BA_ "SPN" SG_ 2364577534 HVESSHghVltgBsNgtvCnttrStt 8092;
BA_ "SPN" SG_ 2364577534 HVESSHghVltgBsDsnntFrwrnng 8093;
BA_ "SPN" SG_ 2364577534 HVESSHghVltgBsPrChrgRlStt 8094;
BA_ "SPN" SG_ 2364577534 HVESSCenterofPackContactorState 8095;
BA_ "SPN" SG_ 2364577534 HVESSHghVltgBsAtvIsltnTstStts 8096;
BA_ "SPN" SG_ 2364577534 HVESSHghVltgBsPssvIsltnTstStts 8097;
BA_ "SPN" SG_ 2364577534 HVESSHVILStatus 8098;
BA_ "SPN" SG_ 2364577534 HVESSInertiaSwitchStatus 8099;
BA_ "SPN" SG_ 2364577534 HVESSStateofChargeStatus 8100;
BA_ "SPN" SG_ 2364577534 HVESSCellBalanceStatus 8101;
BA_ "SPN" SG_ 2364577534 HVESSCellBalancingActive 8102;
BA_ "SPN" SG_ 2364577534 HVESSInternalChargerStatus 8207;
BA_ "SPN" SG_ 2364577534 HVESSHghVltgBsCnntnStts 8413;
BA_ "SPN" SG_ 2364577534 HVESSOperationalStatus 8414;
BA_ "SPN" SG_ 2364577534 HVESSNumberofHVESPsReady 12905;
BA_ "SPN" SG_ 2364577534 HVESSStatus1Counter 13013;
BA_ "SPN" SG_ 2364577534 HVESSStatus1CRC 13014;
BA_ "SPN" SG_ 2364580094 HVESSDischargeEnergyCapacity 8205;
BA_ "SPN" SG_ 2364580094 HVESSChargeEnergyCapacity 8206;
BA_ "SPN" SG_ 2364580094 HVESSMaximumChargeVoltageLimit 8090;
BA_ "SPN" SG_ 2364590334 DCACAssrInvrtr1DCSdCrrnt 8891;
BA_ "SPN" SG_ 2364590334 DCACAssrInvrtr1DCSdPwr 8889;
BA_ "SPN" SG_ 2364590334 DCACAssrInvrtr1DCSdVltg 8890;
BA_ "SPN" SG_ 2364590334 DCACAssIvt1DCSdNtvtCsssGdVt 9582;
BA_ "SPN" SG_ 2364590590 DCACAssrInvrtr1IgntnVltg 9209;
BA_ "SPN" SG_ 2364590590 DCACAssrInvrtr1UnswthdSLIVltg 9210;
BA_ "SPN" SG_ 2364591102 DCACAssrInvrtr2DCSdCrrnt 9238;
BA_ "SPN" SG_ 2364591102 DCACAssrInvrtr2DCSdPwr 9236;
BA_ "SPN" SG_ 2364591102 DCACAssrInvrtr2DCSdVltg 9237;
BA_ "SPN" SG_ 2364591102 DCACAssIvt2DCSdNtvtCsssGdVt 9583;
BA_ "SPN" SG_ 2364591358 DCACAssrInvrtr2IgntnVltg 9239;
BA_ "SPN" SG_ 2364591358 DCACAssrInvrtr2UnswthdSLIVltg 9240;
BA_ "SPN" SG_ 2364592382 EngnClndr10ExldfrmCmstnRqst 7001;
BA_ "SPN" SG_ 2364592382 EngnClndr11ExldfrmCmstnRqst 7002;
BA_ "SPN" SG_ 2364592382 EngnClndr12ExldfrmCmstnRqst 7003;
BA_ "SPN" SG_ 2364592382 EngnClndr13ExldfrmCmstnRqst 7004;
BA_ "SPN" SG_ 2364592382 EngnClndr14ExldfrmCmstnRqst 7005;
BA_ "SPN" SG_ 2364592382 EngnClndr15ExldfrmCmstnRqst 7006;
BA_ "SPN" SG_ 2364592382 EngnClndr16ExldfrmCmstnRqst 7007;
BA_ "SPN" SG_ 2364592382 EngnClndr17ExldfrmCmstnRqst 7008;
BA_ "SPN" SG_ 2364592382 EngnClndr18ExldfrmCmstnRqst 7009;
BA_ "SPN" SG_ 2364592382 EngnClndr19ExldfrmCmstnRqst 7010;
BA_ "SPN" SG_ 2364592382 EngnClndr1ExldfrmCmstnRqst 6992;
BA_ "SPN" SG_ 2364592382 EngnClndr20ExldfrmCmstnRqst 7011;
BA_ "SPN" SG_ 2364592382 EngnClndr21ExldfrmCmstnRqst 7012;
BA_ "SPN" SG_ 2364592382 EngnClndr22ExldfrmCmstnRqst 7013;
BA_ "SPN" SG_ 2364592382 EngnClndr23ExldfrmCmstnRqst 7014;
BA_ "SPN" SG_ 2364592382 EngnClndr24ExldfrmCmstnRqst 7015;
BA_ "SPN" SG_ 2364592382 EngnClndr2ExldfrmCmstnRqst 6993;
BA_ "SPN" SG_ 2364592382 EngnClndr3ExldfrmCmstnRqst 6994;
BA_ "SPN" SG_ 2364592382 EngnClndr4ExldfrmCmstnRqst 6995;
BA_ "SPN" SG_ 2364592382 EngnClndr5ExldfrmCmstnRqst 6996;
BA_ "SPN" SG_ 2364592382 EngnClndr6ExldfrmCmstnRqst 6997;
BA_ "SPN" SG_ 2364592382 EngnClndr7ExldfrmCmstnRqst 6998;
BA_ "SPN" SG_ 2364592382 EngnClndr8ExldfrmCmstnRqst 6999;
BA_ "SPN" SG_ 2364592382 EngnClndr9ExldfrmCmstnRqst 7000;
BA_ "SPN" SG_ 2364592382 NmrfEngnClndrstExldfrmCmstn 6991;
BA_ "SPN" SG_ 2364592638 EngnClndrHdBpssAttr1DsrdPstn 7091;
BA_ "SPN" SG_ 2364592638 EngnClndrHdBpssAttr1OprtnStts 7093;
BA_ "SPN" SG_ 2364592638 EngnClndrHdBpssAttr1PrlmnrFMI 7088;
BA_ "SPN" SG_ 2364592638 EngnClndrHdBpssAttr1Pstn 7092;
BA_ "SPN" SG_ 2364592638 EngnClndrHdBpssAttr1Tmprtr 7090;
BA_ "SPN" SG_ 2364592638 EngnClndrHdBpssAttr1TmprtrStts 7089;
BA_ "SPN" SG_ 2364592894 EngineIntakeAirSourceValve 6330;
BA_ "SPN" SG_ 2364592894 EngnClndrHdBpssAttr1Cmmnd 7094;
BA_ "SPN" SG_ 2364592894 EngnExhstGsRstrtnVlvPstn 8151;
BA_ "SPN" SG_ 2364593150 PrdtvCrsCntrlDrvlnDsnggInhtRqst 7430;
BA_ "SPN" SG_ 2364593150 PrdtvCrsCntrlEvntnRng 7431;
BA_ "SPN" SG_ 2364593150 PrdtvCrsCntrlSpdEvntIndtr 7434;
BA_ "SPN" SG_ 2364593150 PrdtvCrsCntrlStSpdOffst 7316;
BA_ "SPN" SG_ 2364593150 PredictiveCruiseControlState 7317;
BA_ "SPN" SG_ 2364593150 RoadwayNextGrade 7433;
BA_ "SPN" SG_ 2364593150 RoadwayNextGradeDistance 9199;
BA_ "SPN" SG_ 2364593150 RoadwayPresentGrade 7432;
BA_ "SPN" SG_ 2364593150 VhlSpdCntrlOvrrdEvntIndtr 7435;
BA_ "SPN" SG_ 2364593150 VhlSpdCntrlOvrrdRqst 7429;
BA_ "SPN" SG_ 2364597758 EngnClndr1IgntnTmngOffst 7356;
BA_ "SPN" SG_ 2364597758 EngnClndr2IgntnTmngOffst 7357;
BA_ "SPN" SG_ 2364597758 EngnClndr3IgntnTmngOffst 7358;
BA_ "SPN" SG_ 2364597758 EngnClndr4IgntnTmngOffst 7359;
BA_ "SPN" SG_ 2364597758 EngnClndr5IgntnTmngOffst 7360;
BA_ "SPN" SG_ 2364597758 EngnClndr6IgntnTmngOffst 7361;
BA_ "SPN" SG_ 2364597758 EngnClndr7IgntnTmngOffst 7362;
BA_ "SPN" SG_ 2364597758 EngnClndr8IgntnTmngOffst 7363;
BA_ "SPN" SG_ 2364598014 EngnClndr10IgntnTmngOffst 7365;
BA_ "SPN" SG_ 2364598014 EngnClndr11IgntnTmngOffst 7366;
BA_ "SPN" SG_ 2364598014 EngnClndr12IgntnTmngOffst 7367;
BA_ "SPN" SG_ 2364598014 EngnClndr13IgntnTmngOffst 7368;
BA_ "SPN" SG_ 2364598014 EngnClndr14IgntnTmngOffst 7369;
BA_ "SPN" SG_ 2364598014 EngnClndr15IgntnTmngOffst 7370;
BA_ "SPN" SG_ 2364598014 EngnClndr16IgntnTmngOffst 7371;
BA_ "SPN" SG_ 2364598014 EngnClndr9IgntnTmngOffst 7364;
BA_ "SPN" SG_ 2364598270 EngnClndr17IgntnTmngOffst 7372;
BA_ "SPN" SG_ 2364598270 EngnClndr18IgntnTmngOffst 7373;
BA_ "SPN" SG_ 2364598270 EngnClndr19IgntnTmngOffst 7374;
BA_ "SPN" SG_ 2364598270 EngnClndr20IgntnTmngOffst 7375;
BA_ "SPN" SG_ 2364598270 EngnClndr21IgntnTmngOffst 7376;
BA_ "SPN" SG_ 2364598270 EngnClndr22IgntnTmngOffst 7377;
BA_ "SPN" SG_ 2364598270 EngnClndr23IgntnTmngOffst 7378;
BA_ "SPN" SG_ 2364598270 EngnClndr24IgntnTmngOffst 7379;
BA_ "SPN" SG_ 2364598526 EngnFlAttr3CntrlCmmnd 7593;
BA_ "SPN" SG_ 2364598526 EngnFlAttr4CntrlCmmnd 7594;
BA_ "SPN" SG_ 2364602878 EngnVlvCntrlMdl1PrlmnrFMI 7770;
BA_ "SPN" SG_ 2364602878 EngnVlvCntrlMdl2PrlmnrFMI 7771;
BA_ "SPN" SG_ 2364602878 EngnVlvCntrlMdl3PrlmnrFMI 7772;
BA_ "SPN" SG_ 2364602878 EngnVlvCntrlMdl4PrlmnrFMI 7773;
BA_ "SPN" SG_ 2364602878 EngnVlvCntrlMdl5PrlmnrFMI 7774;
BA_ "SPN" SG_ 2364602878 EngnVlvCntrlMdl6PrlmnrFMI 7775;
BA_ "SPN" SG_ 2364602878 EngnVlvCntrlMdl7PrlmnrFMI 7776;
BA_ "SPN" SG_ 2364602878 EngnVlvCntrlMdl8PrlmnrFMI 7777;
BA_ "SPN" SG_ 2364603134 MxmmFrwrdTrnsmssnOtptShftSpd 7779;
BA_ "SPN" SG_ 2364603134 MxmmRvrsTrnsmssnOtptShftSpd 7780;
BA_ "SPN" SG_ 2364603134 SAddssAtvPdTsssRqstdG 8613;
BA_ "SPN" SG_ 2364603134 TransmissionMode11Indicator 12939;
BA_ "SPN" SG_ 2364603134 TransmissionMode12Indicator 12940;
BA_ "SPN" SG_ 2364603134 TransmissionMode13Indicator 12941;
BA_ "SPN" SG_ 2364603134 TransmissionMode14Indicator 12942;
BA_ "SPN" SG_ 2364603134 TransmissionMode15Indicator 12943;
BA_ "SPN" SG_ 2364603134 TransmissionMode16Indicator 12944;
BA_ "SPN" SG_ 2364603134 TransmissionMode17Indicator 12945;
BA_ "SPN" SG_ 2364603134 TransmissionMode18Indicator 12946;
BA_ "SPN" SG_ 2364603134 TransmissionMode19Indicator 12947;
BA_ "SPN" SG_ 2364603134 TransmissionMode20Indicator 12948;
BA_ "SPN" SG_ 2364603390 Atttt1DsExstFdDsVv1Cd 8442;
BA_ "SPN" SG_ 2364603390 Atttt1DsExstFdRqstdQttIttHRst 7783;
BA_ "SPN" SG_ 2364603646 Atttt2DsExstFdRqstdQttIttHRst 7784;
BA_ "SPN" SG_ 2364603902 Atttt1DsExstFdAtQttIttHRst 7786;
BA_ "SPN" SG_ 2364604158 Atttt2DsExstFdAtQttIttHRst 7787;
BA_ "SPN" SG_ 2364605438 GeneratorTripkVArHoursExport 7832;
BA_ "SPN" SG_ 2364605438 GeneratorTripkWHoursExport 7831;
BA_ "SPN" SG_ 2364605950 HydraulicLinePressure 7939;
BA_ "SPN" SG_ 2364605950 MechanicalMovementAngle 7940;
BA_ "SPN" SG_ 2364606718 HVESSModule1OperationalStatus 8214;
BA_ "SPN" SG_ 2364606718 HVESSModule2OperationalStatus 8215;
BA_ "SPN" SG_ 2364606718 HVESSModule3OperationalStatus 8216;
BA_ "SPN" SG_ 2364606718 HVESSModule4OperationalStatus 8217;
BA_ "SPN" SG_ 2364606718 HVESSModule5OperationalStatus 8218;
BA_ "SPN" SG_ 2364606718 HVESSModule6OperationalStatus 8219;
BA_ "SPN" SG_ 2364606718 HVESSModule7OperationalStatus 8220;
BA_ "SPN" SG_ 2364606718 HVESSModule8OperationalStatus 8221;
BA_ "SPN" SG_ 2364606718 HVESSModule9OperationalStatus 8222;
BA_ "SPN" SG_ 2364606718 HVESSModule10OperationalStatus 8223;
BA_ "SPN" SG_ 2364606718 HVESSModule11OperationalStatus 8224;
BA_ "SPN" SG_ 2364606718 HVESSModule12OperationalStatus 8225;
BA_ "SPN" SG_ 2364606718 HVESSModule13OperationalStatus 8226;
BA_ "SPN" SG_ 2364606718 HVESSModule14OperationalStatus 8227;
BA_ "SPN" SG_ 2364606718 HVESSModule15OperationalStatus 8228;
BA_ "SPN" SG_ 2364606718 HVESSModule16OperationalStatus 8229;
BA_ "SPN" SG_ 2364606718 HVESSModule17OperationalStatus 14609;
BA_ "SPN" SG_ 2364606718 HVESSModule18OperationalStatus 14610;
BA_ "SPN" SG_ 2364606718 HVESSModule19OperationalStatus 14611;
BA_ "SPN" SG_ 2364606718 HVESSModule20OperationalStatus 14612;
BA_ "SPN" SG_ 2364606718 HVESSModule21OperationalStatus 14613;
BA_ "SPN" SG_ 2364606718 HVESSModule22OperationalStatus 14614;
BA_ "SPN" SG_ 2364606718 HVESSModule23OperationalStatus 14615;
BA_ "SPN" SG_ 2364606718 HVESSModule24OperationalStatus 14616;
BA_ "SPN" SG_ 2364606718 HVESSModule25OperationalStatus 14617;
BA_ "SPN" SG_ 2364606718 HVESSModule26OperationalStatus 14618;
BA_ "SPN" SG_ 2364606718 HVESSModule27OperationalStatus 14619;
BA_ "SPN" SG_ 2364606718 HVESSModule28OperationalStatus 14620;
BA_ "SPN" SG_ 2364606718 HVESSModule29OperationalStatus 14621;
BA_ "SPN" SG_ 2364606718 HVESSModule30OperationalStatus 14622;
BA_ "SPN" SG_ 2364606718 HVESSModule31OperationalStatus 14623;
BA_ "SPN" SG_ 2364606718 HVESSModule32OperationalStatus 14624;
BA_ "SPN" SG_ 2364606974 HVESSThrmlMngmntSstmSLIInptPwr 8230;
BA_ "SPN" SG_ 2364606974 HVESSTMtSstHVtIptPw 8231;
BA_ "SPN" SG_ 2364606974 HVESSThrmlMngmntSstmCmprssrSpd 8232;
BA_ "SPN" SG_ 2364606974 HVESSThrmlMngmntSstmRltvHmdt 8233;
BA_ "SPN" SG_ 2364606974 HVESSThrmlMngmntSstmHtrStts 8234;
BA_ "SPN" SG_ 2364606974 HVESSThrmlMngmntSstmHVILStts 12813;
BA_ "SPN" SG_ 2364606974 HVESSThrmlMngmntSstmMd 8235;
BA_ "SPN" SG_ 2364606974 HVESSThrmlMngmntSstmClntLvl 12897;
BA_ "SPN" SG_ 2364607230 HVESSHghstCllVltgMdlNmr 8236;
BA_ "SPN" SG_ 2364607230 HVESSHghstCllVltgCllNmr 8237;
BA_ "SPN" SG_ 2364607230 HVESSLwstCllVltgMdlNmr 8238;
BA_ "SPN" SG_ 2364607230 HVESSLwstCllVltgCllNmr 8239;
BA_ "SPN" SG_ 2364607230 HVESSAverageCellVoltage 8240;
BA_ "SPN" SG_ 2364607486 HVESSHghstCllTmprtrMdlNmr 8241;
BA_ "SPN" SG_ 2364607486 HVESSHghstCllTmprtrCllNmr 8242;
BA_ "SPN" SG_ 2364607486 HVESSLwstCllTmprtrMdlNmr 8243;
BA_ "SPN" SG_ 2364607486 HVESSLwstCllTmprtrCllNmr 8244;
BA_ "SPN" SG_ 2364607742 HVESSHghstCllSttfChrgMdlNmr 8245;
BA_ "SPN" SG_ 2364607742 HVESSHghstCllSttfChrgCllNmr 8246;
BA_ "SPN" SG_ 2364607742 HVESSLwstCllSttfChrgMdlNmr 8247;
BA_ "SPN" SG_ 2364607742 HVESSLwstCllSttfChrgCllNmr 8248;
BA_ "SPN" SG_ 2364607742 HVESSHghVltgBsAtvIsltnTstRslts 8431;
BA_ "SPN" SG_ 2364607742 HVESSHghVltgBsPssvIsltnTstRslts 8432;
BA_ "SPN" SG_ 2364608510 EnginePowerDerateRequest 8436;
BA_ "SPN" SG_ 2364608510 EngineSelfInducedDerateLoad 8435;
BA_ "SPN" SG_ 2364609278 DCDC1HghSdVltgBstStpnt 8562;
BA_ "SPN" SG_ 2364609278 DCDC1LowSideVoltageBuckSetpoint 8561;
BA_ "SPN" SG_ 2364609278 DCDC1LwSdVltgBkDfltStpnt 9515;
BA_ "SPN" SG_ 2364609278 DCDC1OperationalCommand 8560;
BA_ "SPN" SG_ 2364609278 DCDC1ControlCounter 7955;
BA_ "SPN" SG_ 2364609278 DCDC1ControlCRC 7956;
BA_ "SPN" SG_ 2364609534 DCDC1HVILStatus 8570;
BA_ "SPN" SG_ 2364609534 DCDC1LoadshedRequest 8571;
BA_ "SPN" SG_ 2364609534 DCDC1OperationalStatus 8569;
BA_ "SPN" SG_ 2364609534 DCDC1PwrLmtdtCnvrtrTmprtr 8578;
BA_ "SPN" SG_ 2364609534 DCDC1PwrLmtdtEltrnFltrTmprtr 8579;
BA_ "SPN" SG_ 2364609534 DCDC1PwrLmtdtHghSdCrrnt 8572;
BA_ "SPN" SG_ 2364609534 DCDC1PwrLmtdtHghSdVltgMnmm 8574;
BA_ "SPN" SG_ 2364609534 DCDC1PwrLmtdtHghSdVltgMxmm 8575;
BA_ "SPN" SG_ 2364609534 DCDC1PwrLmtdtLwSdCrrnt 8573;
BA_ "SPN" SG_ 2364609534 DCDC1PwrLmtdtLwSdVltgMnmm 8576;
BA_ "SPN" SG_ 2364609534 DCDC1PwrLmtdtLwSdVltgMxmm 8577;
BA_ "SPN" SG_ 2364609534 DCDC1PwrLmtdtPwrEltrnsTmprtr 8580;
BA_ "SPN" SG_ 2364609534 DCDC1PwrLmtdtSLIBttrTrmnlCrrnt 8583;
BA_ "SPN" SG_ 2364609534 DCDC1PwrLmtdtSLIBttrTrmnlTmprtr 8582;
BA_ "SPN" SG_ 2364609534 DCDC1PwrLmtdtSLIBttrTrmnlVltg 8581;
BA_ "SPN" SG_ 2364609534 DCDC1PwrLmtdtUndfndRsn 8584;
BA_ "SPN" SG_ 2364609534 DCDC1OperatingStatusCounter 7957;
BA_ "SPN" SG_ 2364609534 DCDC1OperatingStatusCRC 7958;
BA_ "SPN" SG_ 2364609790 DCDC1HighSideCurrent 8588;
BA_ "SPN" SG_ 2364609790 DCDC1HighSideVoltage 8587;
BA_ "SPN" SG_ 2364609790 DCDC1LowSideCurrent 8586;
BA_ "SPN" SG_ 2364609790 DCDC1LowSideVoltage 8585;
BA_ "SPN" SG_ 2364610046 DCDC1SLIBatteryTerminalCurrent 8590;
BA_ "SPN" SG_ 2364610046 DCDC1SLIBatteryTerminalVoltage 8589;
BA_ "SPN" SG_ 2364610046 DCDC1SLIBttrTrmnlTmprtr 8591;
BA_ "SPN" SG_ 2364610558 DCDC1HighSidePower 8821;
BA_ "SPN" SG_ 2364610558 DCDC1LowSidePower 8820;
BA_ "SPN" SG_ 2364610558 DCDC1HghSdNgtvtChsssGrndVltg 9587;
BA_ "SPN" SG_ 2364610814 DCDC2HghSdVltgBstStpnt 8894;
BA_ "SPN" SG_ 2364610814 DCDC2LowSideVoltageBuckSetpoint 8893;
BA_ "SPN" SG_ 2364610814 DCDC2LwSdVltgBkDfltStpnt 9516;
BA_ "SPN" SG_ 2364610814 DCDC2OperationalCommand 8892;
BA_ "SPN" SG_ 2364610814 DCDC2ControlCounter 7959;
BA_ "SPN" SG_ 2364610814 DCDC2ControlCRC 7960;
BA_ "SPN" SG_ 2364611070 DCDC2HVILStatus 8896;
BA_ "SPN" SG_ 2364611070 DCDC2LoadshedRequest 8897;
BA_ "SPN" SG_ 2364611070 DCDC2OperationalStatus 8895;
BA_ "SPN" SG_ 2364611070 DCDC2PwrLmtdtCnvrtrTmprtr 8904;
BA_ "SPN" SG_ 2364611070 DCDC2PwrLmtdtEltrnFltrTmprtr 8905;
BA_ "SPN" SG_ 2364611070 DCDC2PwrLmtdtHghSdCrrnt 8898;
BA_ "SPN" SG_ 2364611070 DCDC2PwrLmtdtHghSdVltgMnmm 8900;
BA_ "SPN" SG_ 2364611070 DCDC2PwrLmtdtHghSdVltgMxmm 8901;
BA_ "SPN" SG_ 2364611070 DCDC2PwrLmtdtLwSdCrrnt 8899;
BA_ "SPN" SG_ 2364611070 DCDC2PwrLmtdtLwSdVltgMnmm 8902;
BA_ "SPN" SG_ 2364611070 DCDC2PwrLmtdtLwSdVltgMxmm 8903;
BA_ "SPN" SG_ 2364611070 DCDC2PwrLmtdtPwrEltrnsTmprtr 8906;
BA_ "SPN" SG_ 2364611070 DCDC2PwrLmtdtSLIBttrTrmnlCrrnt 8908;
BA_ "SPN" SG_ 2364611070 DCDC2PwrLmtdtSLIBttrTrmnlTmprtr 8909;
BA_ "SPN" SG_ 2364611070 DCDC2PwrLmtdtSLIBttrTrmnlVltg 8907;
BA_ "SPN" SG_ 2364611070 DCDC2PwrLmtdtUndfndRsn 8910;
BA_ "SPN" SG_ 2364611070 DCDC2OperatingStatusCounter 7961;
BA_ "SPN" SG_ 2364611070 DCDC2OperatingStatusCRC 7962;
BA_ "SPN" SG_ 2364611326 DCDC2HighSideCurrent 8914;
BA_ "SPN" SG_ 2364611326 DCDC2HighSideVoltage 8913;
BA_ "SPN" SG_ 2364611326 DCDC2LowSideCurrent 8912;
BA_ "SPN" SG_ 2364611326 DCDC2LowSideVoltage 8911;
BA_ "SPN" SG_ 2364611582 DCDC2SLIBatteryTerminalCurrent 8916;
BA_ "SPN" SG_ 2364611582 DCDC2SLIBatteryTerminalVoltage 8915;
BA_ "SPN" SG_ 2364611582 DCDC2SLIBttrTrmnlTmprtr 8917;
BA_ "SPN" SG_ 2364611838 DCDC2HighSidePower 8919;
BA_ "SPN" SG_ 2364611838 DCDC2LowSidePower 8918;
BA_ "SPN" SG_ 2364611838 DCDC2HghSdNgtvtChsssGrndVltg 9588;
BA_ "SPN" SG_ 2364612094 DCDC3HghSdVltgBstStpnt 8949;
BA_ "SPN" SG_ 2364612094 DCDC3LowSideVoltageBuckSetpoint 8948;
BA_ "SPN" SG_ 2364612094 DCDC3LwSdVltgBkDfltStpnt 9517;
BA_ "SPN" SG_ 2364612094 DCDC3OperationalCommand 8947;
BA_ "SPN" SG_ 2364612094 DCDC3ControlCounter 7963;
BA_ "SPN" SG_ 2364612094 DCDC3ControlCRC 7964;
BA_ "SPN" SG_ 2364612350 DCDC3HVILStatus 8951;
BA_ "SPN" SG_ 2364612350 DCDC3LoadshedRequest 8952;
BA_ "SPN" SG_ 2364612350 DCDC3OperationalStatus 8950;
BA_ "SPN" SG_ 2364612350 DCDC3PwrLmtdtCnvrtrTmprtr 8959;
BA_ "SPN" SG_ 2364612350 DCDC3PwrLmtdtEltrnFltrTmprtr 8960;
BA_ "SPN" SG_ 2364612350 DCDC3PwrLmtdtHghSdCrrnt 8953;
BA_ "SPN" SG_ 2364612350 DCDC3PwrLmtdtHghSdVltgMnmm 8955;
BA_ "SPN" SG_ 2364612350 DCDC3PwrLmtdtHghSdVltgMxmm 8956;
BA_ "SPN" SG_ 2364612350 DCDC3PwrLmtdtLwSdCrrnt 8954;
BA_ "SPN" SG_ 2364612350 DCDC3PwrLmtdtLwSdVltgMnmm 8957;
BA_ "SPN" SG_ 2364612350 DCDC3PwrLmtdtLwSdVltgMxmm 8958;
BA_ "SPN" SG_ 2364612350 DCDC3PwrLmtdtPwrEltrnsTmprtr 8961;
BA_ "SPN" SG_ 2364612350 DCDC3PwrLmtdtSLIBttrTrmnlCrrnt 8963;
BA_ "SPN" SG_ 2364612350 DCDC3PwrLmtdtSLIBttrTrmnlTmprtr 8964;
BA_ "SPN" SG_ 2364612350 DCDC3PwrLmtdtSLIBttrTrmnlVltg 8962;
BA_ "SPN" SG_ 2364612350 DCDC3PwrLmtdtUndfndRsn 8965;
BA_ "SPN" SG_ 2364612350 DCDC3OperatingStatusCounter 7965;
BA_ "SPN" SG_ 2364612350 DCDC3OperatingStatusCRC 7966;
BA_ "SPN" SG_ 2364612606 DCDC3HighSideCurrent 8969;
BA_ "SPN" SG_ 2364612606 DCDC3HighSideVoltage 8968;
BA_ "SPN" SG_ 2364612606 DCDC3LowSideCurrent 8967;
BA_ "SPN" SG_ 2364612606 DCDC3LowSideVoltage 8966;
BA_ "SPN" SG_ 2364612862 DCDC3SLIBatteryTerminalCurrent 8971;
BA_ "SPN" SG_ 2364612862 DCDC3SLIBatteryTerminalVoltage 8970;
BA_ "SPN" SG_ 2364612862 DCDC3SLIBttrTrmnlTmprtr 8972;
BA_ "SPN" SG_ 2364613118 DCDC3HighSidePower 8974;
BA_ "SPN" SG_ 2364613118 DCDC3LowSidePower 8973;
BA_ "SPN" SG_ 2364613118 DCDC3HghSdNgtvtChsssGrndVltg 9589;
BA_ "SPN" SG_ 2364613374 DCDC4HghSdVltgBstStpnt 9004;
BA_ "SPN" SG_ 2364613374 DCDC4LowSideVoltageBuckSetpoint 9003;
BA_ "SPN" SG_ 2364613374 DCDC4LwSdVltgBkDfltStpnt 9518;
BA_ "SPN" SG_ 2364613374 DCDC4OperationalCommand 9002;
BA_ "SPN" SG_ 2364613374 DCDC4ControlCounter 8625;
BA_ "SPN" SG_ 2364613374 DCDC4ControlCRC 8626;
